VERSION "Version"

NS_ :

BS_:

BU_: Tester CCU IBCS EPB EPS ADC CCURT1 CCURT2 ZCUF ZCUL ZCUR ZCUT EMS IDM DCDC DCDCI IPS NIDU DCU2 OBC OPC LPC CPC EMCM GCU DCU IPU BMS EOP EVCC DCDC2 EDL SRS ECS RBM ICM IID IDC AMP WHUD ARHUD IMR FIMR CD INU IFC FAPA RRR RLR PAS PCS SCMF SCMR SCMRL SCMRR MFS DRM FCP RCP LBMSAD AVAS DLPFL FBLCM FLISD FLLCM FRLCM RLLCMA RLLCMB RRLCMA RRLCMB RLISD DLPML DLPMR TRM PSDL PSDR FLDCM FRDCM HVSPRL HVSPRR RFR SBM WCM ETC TBOX2 TBOX RLBMS EBU FLPDM RLPDM FRPDM RRPDM FLOAR FROAR RLOAR RROAR EOSL EOSR EOST PRBU RT2_C3 OTAWL IDUR PHUDD RAS CBM PLGM TMC LPC2 SAS RCICP SCMRM SCMT SLMRL SLMRR IDU RRISD DSASBM LBMS RT1_C0 RT1_C1

BO_ 2015 Fun_Diag_Rx: 64 Tester
 SG_ Fun_Diag_Request : 7|512@0+ (1,0) [0|0] ""  CCURT1,CCURT2,ZCUF,ZCUL,ZCUR,ZCUT,EMS,IDM,DCDC,DCDCI,IPS,NIDU,DCU2,OBC,OPC,LPC,CPC,EMCM,GCU,DCU,IPU,BMS,EOP,EVCC,DCDC2,EDL,SRS,ECS,EPS,EPB,RBM,IBCS,ICM,IID,IDC,AMP,WHUD,ARHUD,IMR,FIMR,CD,INU,ADC,IFC,FAPA,RRR,RLR,PAS,PCS,SCMF,SCMR,SCMRL,SCMRR,MFS,DRM,FCP,RCP,LBMSAD,AVAS,DLPFL,FBLCM,FLISD,FLLCM,FRLCM,RLLCMA,RLLCMB,RRLCMA,RRLCMB,RLISD,DLPML,DLPMR,TRM,PSDL,PSDR,FLDCM,FRDCM,HVSPRL,HVSPRR,RFR,SBM,WCM,ETC,TBOX2,TBOX,RLBMS,EBU,FLPDM,RLPDM,FRPDM,RRPDM,FLOAR,FROAR,RLOAR,RROAR,EOSL,EOSR,EOST,PRBU

BO_ 368 CCU_DCU_1: 64 CCU
 SG_ DCU_1_CRC : 7|16@0+ (1,0) [0|65535] ""  ADC
 SG_ DCU_1_Counter : 23|8@0+ (1,0) [0|255] ""  ADC
 SG_ DCU_RotSpdAct : 31|16@0+ (1,-32767) [-32767|32766] "rpm"  EPB,ADC
 SG_ DCU_ModeSt : 79|4@0+ (1,0) [0|15] ""  ADC
 SG_ DCU_ADC_MCUBlkst : 268|3@0+ (1,0) [0|7] ""  ADC
 SG_ DCU_ADC_SpdSvModAvl : 256|1@0+ (1,0) [0|1] ""  ADC
 SG_ DCU_ADC_MCUStandstill : 257|1@0+ (1,0) [0|1] ""  ADC
 SG_ DCU_ADC_MCUSpdSVModFit : 271|3@0+ (1,0) [0|7] ""  ADC
 SG_ DCU_ADC_MCUVehSldSt : 258|1@0+ (1,0) [0|1] ""  ADC
 SG_ DCU_ADC_MCUReqTq : 253|11@0+ (1,-1023) [-1023|1023] "Nm"  ADC
 SG_ DCU_TorqAct : 169|13@0+ (0.2,-819) [-819|819] "Nm"  ADC

BO_ 369 CCU_DCU2_1: 64 CCU
 SG_ DCU2_1_CRC : 7|16@0+ (1,0) [0|65535] ""  ADC
 SG_ DCU2_1_Counter : 23|8@0+ (1,0) [0|255] ""  ADC
 SG_ DCU2_RotSpdAct : 31|16@0+ (1,-32767) [-32767|32766] "rpm"  ADC
 SG_ DCU2_ModeSt_Hyb : 221|4@0+ (1,0) [0|15] ""  ADC
 SG_ DCU2_ADC_MCUBlkst : 268|3@0+ (1,0) [0|7] ""  ADC
 SG_ DCU2_ADC_SpdSvModAvl : 256|1@0+ (1,0) [0|1] ""  ADC
 SG_ DCU2_ADC_MCUStandstill : 257|1@0+ (1,0) [0|1] ""  ADC
 SG_ DCU2_ADC_MCUSpdSVModFit : 271|3@0+ (1,0) [0|7] ""  ADC
 SG_ DCU2_ADC_MCUVehSldSt : 258|1@0+ (1,0) [0|1] ""  ADC
 SG_ DCU2_ADC_MCUReqTq : 253|11@0+ (1,-1023) [-1023|1023] "Nm"  ADC

BO_ 513 CCU_IDUR_1: 64 CCU
 SG_ IDUR_RotSpdActL : 31|16@0+ (1,-32767) [-32767|32766] "rpm"  ADC
 SG_ IDUR_RotSpdActR : 135|16@0+ (1,-32767) [-32767|32766] "rpm"  ADC

BO_ 860 CCU_VCU_7: 64 CCU
 SG_ VCU_7_CRC : 7|16@0+ (1,0) [0|65535] ""  CCURT2,RT2_C3,ZCUF,ZCUL,ZCUR,ZCUT,EPB,IID,IDC,ADC,IFC,FAPA,RRR,RLR,DRM
 SG_ VCU_7_Counter : 23|8@0+ (1,0) [0|255] ""  CCURT2,RT2_C3,ZCUF,ZCUL,ZCUR,ZCUT,EPB,IID,IDC,ADC,IFC,FAPA,RRR,RLR,DRM
 SG_ VCU_RoadMod : 27|3@0+ (1,0) [0|7] ""  ECS,IBCS,IDC,ADC,FAPA
 SG_ VCU_GearLvl : 31|4@0+ (1,0) [0|15] ""  CCURT2,RT2_C3,ZCUF,ZCUL,ZCUR,ZCUT,EMS,EPB,IBCS,ADC,IFC,FAPA,RRR,RLR,DRM
 SG_ VCU_VehDrvMod : 38|3@0+ (1,0) [0|7] ""  CCURT2,RT2_C3,ZCUL,ZCUR,EMS,ECS,IBCS,ICM,IDC,AMP,ADC,IFC,FAPA
 SG_ VCU_VehRdySt : 39|1@0+ (1,0) [0|1] ""  CCURT2,RT2_C3,OTAWL,ZCUF,ZCUL,ZCUR,ZCUT,EMS,IDM,IPS,NIDU,DCU2,IDUR,OBC,GCU,DCU,IPU,BMS,ECS,EPB,IBCS,ICM,IID,IDC,PHUDD,ADC,IFC,FAPA,RRR,RLR,EBU
 SG_ VCU_ChgActiveSt_toADC : 52|1@0+ (1,0) [0|1] ""  ADC,IFC,FAPA
 SG_ VCU_PlgConnSt : 91|1@0+ (1,0) [0|1] ""  CCURT2,RT2_C3,ZCUR,ZCUT,NIDU,DCU2,IDUR,GCU,DCU,IPU,ECS,ICM,IID,IDC,PHUDD,ADC,IFC,FAPA,FLLCM,FRLCM
 SG_ VCU_EVRng : 143|9@0+ (1,0) [0|511] "km"  CCURT1,CCURT2,ICM,IID,IDC,PHUDD,ADC,IFC,FAPA
 SG_ VCU_GearLvlDisp : 155|4@0+ (1,0) [0|15] ""  ICM,IID,IDC,PHUDD,WHUD,ARHUD,IMR,FIMR,ADC,IFC,FAPA,PCS
 SG_ VCU_BMS_BattSocDisp : 199|8@0+ (0.3937,0) [0|100] "%"  CCURT2,RT2_C3,ZCUF,ZCUL,ZCUR,ZCUT,EMS,BMS,ICM,IID,IDC,PHUDD,ADC,IFC,FAPA,TBOX,RLBMS
 SG_ VCU_SuspModeReq : 257|2@0+ (1,0) [0|3] ""  ECS,ADC,IFC,FAPA
 SG_ VCU_SuspModeReqEnable : 316|1@0+ (1,0) [0|1] ""  ECS,ADC,IFC,FAPA
 SG_ VCU_PivotSteeringStAvailable : 24|1@0+ (1,0) [0|1] ""  IBCS,IDC,ADC,IFC
 SG_ VCU_PivotSteeringSt : 183|3@0+ (1,0) [0|7] ""  IDUR,IPU,IBCS,IDC,ADC,IFC
 SG_ VCU_GearPosition : 315|3@0+ (1,0) [0|7] ""  CCURT2,BMS,ADC,IFC,FAPA
 SG_ VCU_EcoPlusMod : 341|2@0+ (1,0) [0|3] ""  CCURT2,RT2_C3,IDC,WHUD,ARHUD,ADC
 SG_ ICC_RoadMod : 339|4@0+ (1,0) [0|8] ""  ECS,IBCS,IDC,ADC

BO_ 431 CCU_VCU_8: 64 CCU
 SG_ VCU_TargetRecpTorqSt : 133|2@0+ (1,0) [0|3] ""  IBCS,ADC,IFC,FAPA
 SG_ VCU_AccElecECFail : 151|1@0+ (1,0) [0|1] ""  IBCS,ADC,IFC,FAPA
 SG_ VCU_AccDriverOrvd : 150|1@0+ (1,0) [0|1] ""  ADC,IFC,FAPA
 SG_ VCU_AccTMCFail : 149|1@0+ (1,0) [0|1] ""  IBCS,ADC,IFC,FAPA
 SG_ VCU_TargetRecpTorqNm : 423|14@0+ (1,0) [0|16000] "Nm"  IBCS,ADC,IFC,FAPA
 SG_ VCU_TargetRecpTorqFA : 153|14@0+ (1,0) [0|16000] "Nm"  IBCS,ADC,IFC,FAPA,EBU
 SG_ VCU_TargetRecpTorqRA : 171|14@0+ (1,0) [0|16000] "Nm"  IBCS,ADC,IFC,FAPA,EBU
 SG_ VCU_TorqDriverReqFA : 189|14@0+ (1,0) [0|16000] "Nm"  ECS,IBCS,ADC,IFC,FAPA,EBU
 SG_ VCU_TorqDriverReqRA : 207|14@0+ (1,0) [0|16000] "Nm"  ECS,IBCS,ADC,IFC,FAPA,EBU
 SG_ VCU_VehActDrvTorqFA : 209|14@0+ (1,0) [0|16000] "Nm"  ECS,EPS,IBCS,ADC,IFC,FAPA,EBU
 SG_ VCU_VehActDrvTorqRA : 227|14@0+ (1,0) [0|16000] "Nm"  IDM,ECS,EPS,IBCS,ADC,IFC,FAPA,EBU
 SG_ VCU_TargetRecpTorqFAVD : 104|1@0+ (1,0) [0|1] ""  IBCS,ADC,IFC,FAPA,EBU
 SG_ VCU_TargetRecpTorqRAVD : 105|1@0+ (1,0) [0|1] ""  IBCS,ADC,IFC,FAPA,EBU
 SG_ VCU_TorqDriverReqFAVD : 128|1@0+ (1,0) [0|1] ""  ECS,IBCS,ADC,IFC,FAPA,EBU
 SG_ VCU_TorqDriverReqRAVD : 129|1@0+ (1,0) [0|1] ""  ECS,IBCS,ADC,IFC,FAPA,EBU
 SG_ VCU_VehActDrvTorqFAVD : 244|1@0+ (1,0) [0|1] ""  ECS,EPS,IBCS,ADC,IFC,FAPA,EBU
 SG_ VCU_VehActDrvTorqRAVD : 245|1@0+ (1,0) [0|1] ""  IDM,ECS,EPS,IBCS,ADC,IFC,FAPA,EBU
 SG_ VCU_BcsDecelReq : 243|4@0+ (0.066,-0.99) [-0.99|0] "m/s2"  IBCS,ADC,IFC,FAPA
 SG_ VCU_BcsDecelVD : 255|1@0+ (1,0) [0|1] ""  IBCS,ADC,IFC,FAPA
 SG_ VCU_RecpTorqRL : 261|14@0+ (1,0) [0|16000] ""  IBCS,ADC,FAPA
 SG_ VCU_RecpTorqRLVD : 262|1@0+ (1,0) [0|1] ""  IBCS,ADC,FAPA
 SG_ VCU_RecpTorqRR : 277|14@0+ (1,0) [0|16000] ""  IBCS,ADC,FAPA
 SG_ VCU_RecpTorqRRVD : 278|1@0+ (1,0) [0|1] ""  IBCS,ADC,FAPA
 SG_ VCU_ADSNetErrorFb : 159|3@0+ (1,0) [0|7] ""  ADC,IFC,FAPA
 SG_ VCU_NetModeResp : 156|2@0+ (1,0) [0|3] ""  ADC,FAPA

BO_ 516 CCU_VCU_9: 64 CCU
 SG_ VCU_9_CRC : 7|16@0+ (1,0) [0|65535] ""  CCURT2,RT2_C3,ZCUF,ZCUL,ZCUR,ZCUT,EMS,NIDU,DCU2,IDUR,EDL,ECS,EPB,IBCS,ICM,IDC,INU,ADC,IFC,FAPA,RRR,RLR,PAS,EBU
 SG_ VCU_9_Counter : 23|8@0+ (1,0) [0|255] ""  CCURT2,RT2_C3,ZCUF,ZCUL,ZCUR,ZCUT,EMS,NIDU,DCU2,IDUR,EDL,ECS,EPB,IBCS,ICM,IDC,INU,ADC,IFC,FAPA,RRR,RLR,PAS,EBU
 SG_ VCU_VehWheelTorqMaxVD : 25|1@0+ (1,0) [0|1] ""  ADC,IFC,FAPA
 SG_ VCU_RecpTorq : 71|10@0+ (2,0) [0|2000] "Nm"  IBCS,ADC,IFC,FAPA
 SG_ VCU_RecpTorqSt : 75|2@0+ (1,0) [0|3] ""  IBCS,ADC,IFC,FAPA
 SG_ VCU_MaxRecpTorqSt : 73|2@0+ (1,0) [0|3] ""  IBCS,ADC,IFC,FAPA
 SG_ VCU_MaxRecpTorq : 87|10@0+ (2,0) [0|2000] "Nm"  IBCS,ADC,IFC,FAPA
 SG_ VCU_CrntGearLvl : 92|3@0+ (1,0) [0|7] ""  CCURT2,RT2_C3,OTAWL,ZCUF,ZCUL,ZCUR,ZCUT,NIDU,DCU2,IDUR,DCU,IPU,SRS,ECS,RAS,EPS,EPB,IBCS,IDC,AMP,INU,ADC,IFC,FAPA,RRR,RLR,PAS,DLPML,DLPMR,TBOX,EBU
 SG_ VCU_CrntGearLvlVD : 88|1@0+ (1,0) [0|1] ""  ZCUF,ZCUL,ZCUR,ZCUT,SRS,ECS,EPS,IBCS,AMP,INU,ADC,IFC,FAPA,RRR,RLR,PAS
 SG_ VCU_BrkPedPstVD : 89|1@0+ (1,0) [0|1] ""  CCURT2,RT2_C3,NIDU,DCU2,IDUR,SRS,ECS,IBCS,IDC,ADC,IFC,FAPA
 SG_ VCU_BrkPedPst : 103|8@0+ (0.392,0) [0|99.96] "%"  CCURT2,RT2_C3,NIDU,DCU2,IDUR,SRS,ECS,IBCS,IDC,ADC,IFC,FAPA
 SG_ VCU_APAGasPedalIntv : 112|1@0+ (1,0) [0|1] ""  IBCS,ADC,IFC,FAPA
 SG_ VCU_APAAvailable : 113|1@0+ (1,0) [0|1] ""  IBCS,ADC,IFC,FAPA
 SG_ VCU_APAWheelTorqDriverReq : 111|14@0+ (1,-5000) [-5000|5000] "Nm"  ADC,IFC,FAPA
 SG_ VCU_APAGearIntervern : 137|1@0+ (1,0) [0|1] ""  IBCS,ADC,IFC,FAPA
 SG_ VCU_EMS_AccPedalActPst : 127|8@0+ (0.392,0) [0|99.96] "%"  CCURT2,RT2_C3,EMS,NIDU,DCU2,IDUR,SRS,ECS,IBCS,IDC,AMP,ADC,IFC,FAPA,RRR,RLR,EBU
 SG_ VCU_EMS_AccPedalActPstVD : 136|1@0+ (1,0) [0|1] ""  CCURT2,RT2_C3,EMS,NIDU,DCU2,IDUR,SRS,ECS,IBCS,IDC,AMP,ADC,IFC,FAPA,EBU
 SG_ VCU_ActVehWheelTorq : 135|14@0+ (1,-5000) [-5000|5000] "Nm"  IBCS,ADC,IFC,FAPA
 SG_ VCU_VehWheelTorqMax : 167|14@0+ (1,-5000) [-5000|5000] "Nm"  IBCS,ADC,IFC,FAPA
 SG_ VCU_EMS_BrkPedalSt : 189|1@0+ (1,0) [0|1] ""  CCURT2,RT2_C3,EMS,SRS,ECS,IDC,ADC,IFC,FAPA,RRR,RLR,TBOX
 SG_ VCU_EMS_BrkPedalStVD : 188|1@0+ (1,0) [0|1] ""  CCURT2,RT2_C3,EMS,SRS,ECS,IDC,ADC,IFC,FAPA
 SG_ VCU_ACCMaxRecpDecelVD : 187|1@0+ (1,0) [0|1] ""  ADC,IFC,FAPA
 SG_ VCU_ACCLimitOperatingSt : 186|1@0+ (1,0) [0|1] ""  ADC,IFC,FAPA
 SG_ VCU_APAResp : 185|1@0+ (1,0) [0|1] ""  IBCS,ADC,IFC,FAPA
 SG_ VCU_ADSEcoModReq : 184|1@0+ (1,0) [0|1] ""  ADC,IFC,FAPA
 SG_ VCU_AccButtInfo : 199|8@0+ (1,0) [0|255] ""  IDC,ADC,IFC,FAPA
 SG_ VCU_ACCMaxRecpDecel : 207|8@0+ (0.05,-5) [-5|7.75] "m/s2"  ADC,IFC,FAPA
 SG_ VCU_ACCmaxSpdLimit : 215|4@0+ (1,0) [0|15] ""  ADC,IFC,FAPA
 SG_ VCU_APA_Resp : 210|1@0+ (1,0) [0|1] ""  ADC,IFC,FAPA
 SG_ VCU_RecpTorqFAVD : 208|1@0+ (1,0) [0|1] ""  IBCS,ADC,IFC,FAPA,EBU
 SG_ VCU_RecpTorqRAVD : 209|1@0+ (1,0) [0|1] ""  IBCS,ADC,IFC,FAPA,EBU
 SG_ VCU_MaxRecpTorqFAVD : 152|1@0+ (1,0) [0|1] ""  IBCS,ADC,IFC,FAPA,EBU
 SG_ VCU_MaxRecpTorqRAVD : 153|1@0+ (1,0) [0|1] ""  IBCS,ADC,IFC,FAPA,EBU
 SG_ VCU_RecpTorqNm : 359|14@0+ (1,0) [0|16000] "Nm"  IBCS,ADC,IFC,FAPA
 SG_ VCU_APAWheelTorqDriverReqNm : 361|15@0+ (1,-16000) [-16000|16000] "Nm"  ADC,IFC,FAPA
 SG_ VCU_ActVehWheelTorqNm : 378|15@0+ (1,-16000) [-16000|16000] "Nm"  ECS,IBCS,AMP,ADC,IFC,FAPA
 SG_ VCU_VehWheelTorqMinNm : 395|15@0+ (1,-16000) [-16000|16000] "Nm"  ECS,IBCS,ADC,IFC,FAPA
 SG_ VCU_VehWheelTorqMaxNm : 412|15@0+ (1,-16000) [-16000|16000] "Nm"  ECS,IBCS,ADC,IFC,FAPA
 SG_ VCU_RecpTorqFA : 231|14@0+ (1,0) [0|16000] "Nm"  IBCS,ADC,IFC,FAPA,EBU
 SG_ VCU_RecpTorqRA : 233|14@0+ (1,0) [0|16000] "Nm"  IBCS,ADC,IFC,FAPA,EBU
 SG_ VCU_MaxRecpTorqFA : 251|14@0+ (1,0) [0|16000] "Nm"  IBCS,ADC,IFC,FAPA,EBU
 SG_ VCU_MaxRecpTorqRA : 269|14@0+ (1,0) [0|16000] "Nm"  IBCS,ADC,IFC,FAPA,EBU
 SG_ VCU_BcsDecelEnable : 305|1@0+ (1,0) [0|1] ""  IBCS,IDC,ADC,IFC,FAPA
 SG_ VCU_CrntGearNoTrans : 317|3@0+ (1,0) [0|7] ""  ADC,IFC,FAPA
 SG_ VCU_EzTSt : 314|2@0+ (1,0) [0|3] ""  IBCS,IDC,ADC,FAPA
 SG_ VCU_ITASSt : 444|3@0+ (1,0) [0|7] ""  IBCS,IDC,ADC,FAPA

BO_ 616 CCU_1: 64 CCU
 SG_ CCU_1_CRC : 7|16@0+ (1,0) [0|65535] ""  CCURT2,RT2_C3,OTAWL,ZCUF,ZCUL,ZCUR,ZCUT,NIDU,DCU2,BMS,CBM,RBM,ICM,IID,IDC,ADC,IFC,FAPA,DRM,PLGM,TRM,RLBMS
 SG_ CCU_1_Counter : 23|8@0+ (1,0) [0|255] ""  CCURT2,RT2_C3,OTAWL,ZCUF,ZCUL,ZCUR,ZCUT,NIDU,DCU2,BMS,CBM,RBM,ICM,IID,IDC,ADC,IFC,FAPA,DRM,PLGM,TRM,RLBMS
 SG_ UMM_UsageModeSt : 26|3@0+ (1,0) [0|7] ""  CCURT2,RT2_C3,OTAWL,TMC,ZCUF,ZCUL,ZCUR,ZCUT,EMS,DCDC,DCDCI,IPS,NIDU,DCU2,IDUR,OBC,OPC,LPC,LPC2,CPC,EMCM,GCU,DCU,IPU,BMS,EOP,DCDC2,EDL,SRS,ECS,SAS,CBM,RAS,EPS,EPB,RBM,IBCS,ICM,IID,IDC,PHUDD,RCICP,AMP,WHUD,ARHUD,IMR,FIMR,CD,INU,ADC,IFC,FAPA,RRR,RLR,PAS,PCS,SCMR,SCMRL,SCMRR,SCMRM,SCMT,MFS,SLMRL,SLMRR,DRM,IDU,FCP,RCP,LBMSAD,AVAS,DLPFL,FBLCM,FLISD,FLLCM,FRLCM,RLLCMA,RLLCMB,RRLCMA,RRLCMB,RLISD,RRISD,DLPML,DSASBM,DLPMR,PLGM,TRM,PSDL,PSDR,HVSPRL,HVSPRR,LBMS,TBOX2,TBOX,RLBMS,EBU,FLPDM,RLPDM,FRPDM,RRPDM,FLOAR,FROAR
 SG_ OTA_FuncReq_ADCWakeup : 45|3@0+ (1,0) [0|7] ""  ADC,FAPA
 SG_ UMM_FrontPassengerSeatSt : 57|2@0+ (1,0) [0|3] ""  CCURT2,RT2_C3,OTAWL,ZCUR,SRS,IBCS,ICM,IDC,ADC,IFC,FAPA,RRR,RLR,EBU
 SG_ UMM_DriverSeatSt : 59|2@0+ (1,0) [0|3] ""  CCURT1,CCURT2,RT2_C3,OTAWL,ZCUR,SRS,IBCS,ICM,IDC,ADC,IFC,FAPA,RRR,RLR,EBU
 SG_ VMM_VehModeSt : 159|4@0+ (1,0) [0|15] ""  CCURT2,RT2_C3,OTAWL,TMC,ZCUF,ZCUL,ZCUR,ZCUT,EMS,DCDC,DCDCI,IPS,NIDU,DCU2,IDUR,OBC,OPC,LPC,LPC2,CPC,EMCM,GCU,DCU,IPU,BMS,EOP,DCDC2,EDL,SRS,ECS,SAS,EPS,EPB,RBM,IBCS,ICM,IDC,RCICP,AMP,WHUD,ARHUD,IMR,FIMR,ADC,IFC,FAPA,RRR,RLR,PAS,SCMR,SCMRL,SCMRR,SCMRM,SCMT,MFS,SLMRL,SLMRR,IDU,FCP,RCP,LBMSAD,AVAS,DLPFL,FBLCM,FLISD,FLLCM,FRLCM,RLLCMA,RLLCMB,RRLCMA,RRLCMB,RLISD,RRISD,DLPML,DLPMR,PLGM,TRM,PSDL,PSDR,HVSPRL,HVSPRR,LBMS,RFR,SBM,WCM,ETC,TBOX2,TBOX,RLBMS,EBU,FLPDM,RLPDM,FRPDM,RRPDM,FLOAR,FROAR,RLOAR,RROAR
 SG_ VMM_LastVehModeSt : 155|4@0+ (1,0) [0|15] ""  TMC,ZCUF,ZCUL,ZCUR,ZCUT,EMS,DCDC,DCDCI,IPS,NIDU,DCU2,IDUR,OBC,OPC,LPC,LPC2,CPC,EMCM,GCU,DCU,IPU,BMS,DCDC2,EDL,SRS,EPS,EPB,RBM,IBCS,ICM,IDC,AMP,ADC,IFC,FAPA,PAS,SCMR,SCMRL,SCMRR,MFS,SLMRL,SLMRR,FCP,RCP,AVAS,FLLCM,FRLCM,TRM,PSDL,RFR,SBM,WCM,ETC,TBOX,EBU,FLPDM,FLOAR,FROAR,RLOAR,RROAR
 SG_ VMM_OTAModeSt : 167|2@0+ (1,0) [0|3] ""  CCURT2,RT2_C3,OTAWL,ZCUF,ZCUL,ZCUR,ZCUT,EMS,DCDC,DCDCI,IPS,NIDU,DCU2,IDUR,OBC,OPC,LPC,LPC2,CPC,EMCM,GCU,DCU,IPU,BMS,EOP,DCDC2,EDL,SRS,ECS,EPS,EPB,RBM,IBCS,ICM,IID,IDC,RCICP,AMP,WHUD,ARHUD,ADC,IFC,FAPA,RRR,RLR,PAS,SCMR,SCMRL,SCMRR,SCMRM,SCMT,MFS,SLMRL,SLMRR,IDU,FCP,RCP,LBMSAD,AVAS,DLPFL,FBLCM,FLISD,FLLCM,FRLCM,RLLCMA,RLLCMB,RRLCMA,RRLCMB,RLISD,RRISD,DLPML,DLPMR,TRM,PSDL,PSDR,HVSPRL,HVSPRR,LBMS,RFR,SBM,WCM,ETC,TBOX,RLBMS,EBU,FLPDM,RLPDM,FRPDM,RRPDM,FLOAR,FROAR,RLOAR,RROAR
 SG_ CSM_RC_PAARequest : 287|4@0+ (1,0) [0|15] ""  ADC,FAPA
 SG_ CSM_RC_AuthSt : 281|2@0+ (1,0) [0|3] ""  ADC,FAPA
 SG_ IPDS_EnablePowerSup : 327|2@0+ (1,0) [0|3] ""  CCURT2,ZCUF,ZCUL,ZCUR,ZCUT,EMS,IPS,NIDU,DCU2,IDUR,OBC,OPC,LPC,LPC2,CPC,EMCM,GCU,DCU,IPU,BMS,EDL,SRS,ECS,EPB,RBM,IBCS,ICM,IID,IDC,PHUDD,ADC,FAPA,PCS,EBU
 SG_ Time_Year : 343|8@0+ (1,2000) [2000|2255] "y"  CCURT2,RT2_C3,TMC,ZCUF,ZCUL,ZCUR,ZCUT,EMS,DCDC,DCDCI,IPS,NIDU,DCU2,IDUR,OBC,OPC,LPC,LPC2,CPC,EMCM,GCU,DCU,IPU,BMS,EOP,EVCC,DCDC2,EDL,SRS,ECS,CBM,EPS,EPB,RBM,IBCS,RCICP,AMP,WHUD,ARHUD,IMR,FIMR,INU,ADC,IFC,FAPA,RRR,RLR,PAS,PCS,SCMR,SCMRL,SCMRR,SCMT,MFS,SLMRL,SLMRR,DRM,IDU,FCP,RCP,LBMSAD,DLPFL,FBLCM,FLISD,FLLCM,FRLCM,RLLCMA,RLLCMB,RRLCMA,RRLCMB,RLISD,RRISD,DLPML,DSASBM,DLPMR,PLGM,TRM,PSDL,PSDR,HVSPRL,HVSPRR,LBMS,RLBMS,EBU,FLPDM,RLPDM,FRPDM,RRPDM,FLOAR,FROAR,RLOAR,RROAR
 SG_ Time_Month : 351|4@0+ (1,0) [1|12] "m"  CCURT2,RT2_C3,TMC,ZCUF,ZCUL,ZCUR,ZCUT,EMS,DCDC,DCDCI,IPS,NIDU,DCU2,IDUR,OBC,OPC,LPC,LPC2,CPC,EMCM,GCU,DCU,IPU,BMS,EOP,EVCC,DCDC2,EDL,SRS,ECS,CBM,EPS,EPB,RBM,IBCS,RCICP,AMP,WHUD,ARHUD,IMR,FIMR,INU,ADC,IFC,FAPA,RRR,RLR,PAS,PCS,SCMR,SCMRL,SCMRR,SCMT,MFS,SLMRL,SLMRR,DRM,IDU,FCP,RCP,LBMSAD,DLPFL,FBLCM,FLISD,FLLCM,FRLCM,RLLCMA,RLLCMB,RRLCMA,RRLCMB,RLISD,RRISD,DLPML,DSASBM,DLPMR,PLGM,TRM,PSDL,PSDR,HVSPRL,HVSPRR,LBMS,RLBMS,EBU,FLPDM,RLPDM,FRPDM,RRPDM,FLOAR,FROAR,RLOAR,RROAR
 SG_ Time_Day : 347|5@0+ (1,0) [1|31] "d"  CCURT2,RT2_C3,TMC,ZCUF,ZCUL,ZCUR,ZCUT,EMS,DCDC,DCDCI,IPS,NIDU,DCU2,IDUR,OBC,OPC,LPC,LPC2,CPC,EMCM,GCU,DCU,IPU,BMS,EOP,EVCC,DCDC2,EDL,SRS,ECS,CBM,EPS,EPB,RBM,IBCS,RCICP,AMP,WHUD,ARHUD,IMR,FIMR,INU,ADC,IFC,FAPA,RRR,RLR,PAS,PCS,SCMR,SCMRL,SCMRR,SCMT,MFS,SLMRL,SLMRR,DRM,IDU,FCP,RCP,LBMSAD,DLPFL,FBLCM,FLISD,FLLCM,FRLCM,RLLCMA,RLLCMB,RRLCMA,RRLCMB,RLISD,RRISD,DLPML,DSASBM,DLPMR,PLGM,TRM,PSDL,PSDR,HVSPRL,HVSPRR,LBMS,RLBMS,EBU,FLPDM,RLPDM,FRPDM,RRPDM,FLOAR,FROAR,RLOAR,RROAR
 SG_ Time_Hour : 358|5@0+ (1,0) [0|23] "h"  CCURT2,RT2_C3,TMC,ZCUF,ZCUL,ZCUR,ZCUT,EMS,DCDC,DCDCI,IPS,NIDU,DCU2,IDUR,OBC,OPC,LPC,LPC2,CPC,EMCM,GCU,DCU,IPU,BMS,EOP,EVCC,DCDC2,EDL,SRS,ECS,CBM,EPS,EPB,RBM,IBCS,RCICP,AMP,WHUD,ARHUD,IMR,FIMR,INU,ADC,IFC,FAPA,RRR,RLR,PAS,PCS,SCMR,SCMRL,SCMRR,SCMT,MFS,SLMRL,SLMRR,DRM,IDU,FCP,RCP,LBMSAD,DLPFL,FBLCM,FLISD,FLLCM,FRLCM,RLLCMA,RLLCMB,RRLCMA,RRLCMB,RLISD,RRISD,DLPML,DSASBM,DLPMR,PLGM,TRM,PSDL,PSDR,HVSPRL,HVSPRR,LBMS,RLBMS,EBU,FLPDM,RLPDM,FRPDM,RRPDM,FLOAR,FROAR,RLOAR,RROAR
 SG_ Time_Min : 353|6@0+ (1,0) [0|59] "min"  CCURT2,RT2_C3,TMC,ZCUF,ZCUL,ZCUR,ZCUT,EMS,DCDC,DCDCI,IPS,NIDU,DCU2,IDUR,OBC,OPC,LPC,LPC2,CPC,EMCM,GCU,DCU,IPU,BMS,EOP,EVCC,DCDC2,EDL,SRS,ECS,CBM,EPS,EPB,RBM,IBCS,RCICP,AMP,WHUD,ARHUD,IMR,FIMR,INU,ADC,IFC,FAPA,RRR,RLR,PAS,PCS,SCMR,SCMRL,SCMRR,SCMT,MFS,SLMRL,SLMRR,DRM,IDU,FCP,RCP,LBMSAD,DLPFL,FBLCM,FLISD,FLLCM,FRLCM,RLLCMA,RLLCMB,RRLCMA,RRLCMB,RLISD,RRISD,DLPML,DSASBM,DLPMR,PLGM,TRM,PSDL,PSDR,HVSPRL,HVSPRR,LBMS,RLBMS,EBU,FLPDM,RLPDM,FRPDM,RRPDM,FLOAR,FROAR,RLOAR,RROAR
 SG_ Time_Sec : 363|6@0+ (1,0) [0|59] "s"  CCURT2,RT2_C3,TMC,ZCUF,ZCUL,ZCUR,ZCUT,EMS,DCDC,DCDCI,IPS,NIDU,DCU2,IDUR,OBC,OPC,LPC,LPC2,CPC,EMCM,GCU,DCU,IPU,BMS,EOP,EVCC,DCDC2,EDL,SRS,ECS,CBM,EPS,EPB,RBM,IBCS,RCICP,AMP,WHUD,ARHUD,IMR,FIMR,INU,ADC,IFC,FAPA,RRR,RLR,PAS,PCS,SCMR,SCMRL,SCMRR,SCMT,MFS,SLMRL,SLMRR,DRM,IDU,FCP,RCP,LBMSAD,DLPFL,FBLCM,FLISD,FLLCM,FRLCM,RLLCMA,RLLCMB,RRLCMA,RRLCMB,RLISD,RRISD,DLPML,DSASBM,DLPMR,PLGM,TRM,PSDL,PSDR,HVSPRL,HVSPRR,LBMS,RLBMS,EBU,FLPDM,RLPDM,FRPDM,RRPDM,FLOAR,FROAR,RLOAR,RROAR
 SG_ CCU_DstFlag : 272|1@0+ (1,0) [0|1] ""  ZCUF,ZCUL,ZCUR,ZCUT,ADC,FAPA
 SG_ ASB_DriverActiveBeltFaultSt : 420|1@0+ (1,0) [0|1] ""  IDC,ADC,IFC,FAPA

BO_ 432 ICC_1: 64 CCU
 SG_ ICC_1_CRC : 7|16@0+ (1,0) [0|65535] ""  ECS,RAS,EPS,IBCS,ADC
 SG_ ICC_1_Counter : 23|8@0+ (1,0) [0|255] ""  ECS,RAS,EPS,IBCS,ADC
 SG_ ICC_FcnInfo : 87|12@0+ (1,0) [0|4095] ""  ECS,EPS,IBCS,ADC
 SG_ ICC_FaultSt : 91|12@0+ (1,0) [0|4095] ""  ECS,EPS,ADC
 SG_ ICC_ActorSt : 119|8@0+ (1,0) [0|255] ""  ECS,EPS,ADC
 SG_ ICC_RAS_AgCtrlAvl : 353|2@0+ (1,0) [0|3] "/"  ADC
 SG_ ICC_RAS_CalibratedSt : 360|1@0+ (1,0) [0|1] "/"  ADC
 SG_ ICC_RAS_ErrFeedback : 364|4@0+ (1,0) [0|15] "/"  ADC
 SG_ ICC_RAS_AngleVD : 365|1@0+ (1,0) [0|1] "/"  ADC
 SG_ ICC_RAS_PstOverlaySt : 367|2@0+ (1,0) [0|3] "/"  ADC
 SG_ ICC_RAS_SteerMod : 373|3@0+ (1,0) [0|7] "/"  ADC
 SG_ ICC_RAS_SteeringAngle : 370|11@0+ (0.01,-10.23) [-10.23|10.24] "deg"  ADC
 SG_ ICC_RAS_HealthyStForADC : 375|2@0+ (1,0) [0|3] "/"  ADC
 SG_ ICC_RAS_SteeringAngleSpdVD : 389|1@0+ (1,0) [0|1] "/"  ADC
 SG_ ICC_RAS_ThermalSt : 391|2@0+ (1,0) [0|3] "/"  ADC
 SG_ ICC_RAS_SteeringAngleRate : 388|13@0+ (0.01,-22.52) [-22.52|22.53] "°/s"  ADC
 SG_ ICC_RAS_WarnLamp : 411|2@0+ (1,0) [0|3] "/"  ADC
 SG_ ICC_RAS_MotorTorActMot : 407|12@0+ (0.01,-15) [-15|15] "Nm"  ADC
 SG_ ICC_RAS_ADASTargetAngle : 409|11@0+ (0.01,-10.23) [-10.23|10.24] "deg"  ADC

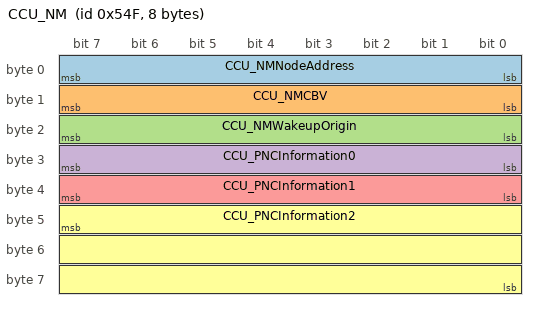
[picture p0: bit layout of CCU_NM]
BO_ 1359 CCU_NM: 8 CCU
 SG_ CCU_NMNodeAddress : 7|8@0+ (1,0) [0|255] ""  CCURT1,TMC,ZCUF,ZCUL,ZCUR,ZCUT,EMS,IPS,NIDU,BMS,EVCC,ECS,CBM,RBM,IBCS,ICM,IID,IDC,PHUDD,AMP,CD,ADC,FAPA,SCMR,SCMRL,SCMRR,SCMRM,SCMT,MFS,SLMRL,SLMRR,IDU,LBMSAD,PLGM,PSDL,PSDR,FLDCM,FRDCM,LBMS,TBOX,RLBMS,EBU,FLPDM,RLPDM,FRPDM,RRPDM
 SG_ CCU_NMCBV : 15|8@0+ (1,0) [0|0] ""  CCURT1,TMC,ZCUF,ZCUL,ZCUR,ZCUT,EMS,IPS,NIDU,BMS,EVCC,ECS,CBM,RBM,IBCS,ICM,IID,IDC,PHUDD,AMP,CD,ADC,FAPA,SCMR,SCMRL,SCMRR,SCMRM,SCMT,MFS,SLMRL,SLMRR,IDU,LBMSAD,PLGM,PSDL,PSDR,FLDCM,FRDCM,LBMS,TBOX,RLBMS,EBU,FLPDM,RLPDM,FRPDM,RRPDM
 SG_ CCU_NMWakeupOrigin : 23|8@0+ (1,0) [0|255] ""  CCURT1,TMC,ZCUF,ZCUL,ZCUR,ZCUT,EMS,IPS,NIDU,BMS,EVCC,ECS,CBM,RBM,IBCS,ICM,IID,IDC,PHUDD,AMP,CD,ADC,FAPA,SCMR,SCMRL,SCMRR,SCMRM,SCMT,MFS,SLMRL,SLMRR,IDU,LBMSAD,PLGM,PSDL,PSDR,FLDCM,FRDCM,LBMS,TBOX,RLBMS,EBU
 SG_ CCU_PNCInformation0 : 31|8@0+ (1,0) [0|255] ""  CCURT1,TMC,ZCUF,ZCUL,ZCUR,ZCUT,EMS,IPS,NIDU,BMS,EVCC,ECS,CBM,RBM,IBCS,ICM,IID,IDC,PHUDD,AMP,CD,ADC,FAPA,SCMR,SCMRL,SCMRR,SCMRM,SCMT,MFS,SLMRL,SLMRR,IDU,LBMSAD,PLGM,PSDL,PSDR,FLDCM,FRDCM,LBMS,TBOX,RLBMS,EBU,FLPDM,RLPDM,FRPDM,RRPDM
 SG_ CCU_PNCInformation1 : 39|8@0+ (1,0) [0|255] ""  CCURT1,TMC,ZCUF,ZCUL,ZCUR,ZCUT,EMS,IPS,NIDU,BMS,EVCC,ECS,CBM,RBM,IBCS,ICM,IID,IDC,PHUDD,AMP,CD,ADC,FAPA,SCMR,SCMRL,SCMRR,SCMRM,SCMT,MFS,SLMRL,SLMRR,IDU,LBMSAD,PLGM,PSDL,PSDR,FLDCM,FRDCM,LBMS,TBOX,RLBMS,EBU,FLPDM,RLPDM,FRPDM,RRPDM
 SG_ CCU_PNCInformation2 : 47|24@0+ (1,0) [0|0] ""  CCURT1,TMC,ZCUF,ZCUL,ZCUR,ZCUT,EMS,IPS,NIDU,BMS,EVCC,ECS,CBM,RBM,IBCS,ICM,IID,IDC,PHUDD,AMP,CD,ADC,FAPA,SCMR,SCMRL,SCMRR,SCMRM,SCMT,MFS,SLMRL,SLMRR,IDU,LBMSAD,PLGM,PSDL,PSDR,FLDCM,FRDCM,LBMS,TBOX,RLBMS,EBU,FLPDM,RLPDM,FRPDM,RRPDM

BO_ 359 BCS_1_B: 64 IBCS
 SG_ BCS_1_B_CRC : 7|16@0+ (1,0) [0|65535] ""  CCU,CCURT1,RT1_C0,RT1_C1,EPS,EPB,ADC
 SG_ BCS_1_B_Counter : 23|8@0+ (1,0) [0|255] ""  CCU,CCURT1,RT1_C0,RT1_C1,EPS,EPB,ADC
 SG_ BCS_FLWheelSpd_B : 31|13@0+ (0.05625,0) [0|240] "km/h"  CCU,CCURT1,RT1_C0,RT1_C1,EPS,EPB,ADC
 SG_ BCS_FLWheelSpdVD_B : 34|1@0+ (1,0) [0|1] ""  CCU,CCURT1,RT1_C0,RT1_C1,EPS,EPB,ADC
 SG_ BCS_FLWheelRotatedDirection_B : 33|1@0+ (1,0) [0|1] ""  CCU,CCURT1,RT1_C0,RT1_C1,EPB,ADC
 SG_ BCS_FLWheelRotatedDirectionVD_B : 32|1@0+ (1,0) [0|1] ""  CCU,CCURT1,RT1_C0,RT1_C1,EPB,ADC
 SG_ BCS_FRWheelSpd_B : 47|13@0+ (0.05625,0) [0|240] "km/h"  CCU,CCURT1,RT1_C0,RT1_C1,EPS,EPB,ADC
 SG_ BCS_FRWheelSpdVD_B : 50|1@0+ (1,0) [0|1] ""  CCU,CCURT1,RT1_C0,RT1_C1,EPS,EPB,ADC
 SG_ BCS_FRWheelRotatedDirection_B : 49|1@0+ (1,0) [0|1] ""  CCU,CCURT1,RT1_C0,RT1_C1,EPB,ADC
 SG_ BCS_FRWheelRotatedDirectionVD_B : 48|1@0+ (1,0) [0|1] ""  CCU,CCURT1,RT1_C0,RT1_C1,EPB,ADC
 SG_ BCS_RLWheelSpd_B : 63|13@0+ (0.05625,0) [0|240] "km/h"  CCU,CCURT1,RT1_C0,RT1_C1,EPS,EPB,ADC
 SG_ BCS_RLWheelSpdVD_B : 66|1@0+ (1,0) [0|1] ""  CCU,CCURT1,RT1_C0,RT1_C1,EPS,EPB,ADC
 SG_ BCS_RLWheelRotatedDirection_B : 65|1@0+ (1,0) [0|1] ""  CCU,CCURT1,RT1_C0,RT1_C1,EPB,ADC
 SG_ BCS_RLWheelRotatedDirectionVD_B : 64|1@0+ (1,0) [0|1] ""  CCU,CCURT1,RT1_C0,RT1_C1,EPB,ADC
 SG_ BCS_RRWheelSpd_B : 79|13@0+ (0.05625,0) [0|240] "km/h"  CCU,CCURT1,RT1_C0,RT1_C1,EPS,EPB,ADC
 SG_ BCS_RRWheelSpdVD_B : 82|1@0+ (1,0) [0|1] ""  CCU,CCURT1,RT1_C0,RT1_C1,EPS,EPB,ADC
 SG_ BCS_RRWheelRotatedDirection_B : 81|1@0+ (1,0) [0|1] ""  CCU,CCURT1,RT1_C0,RT1_C1,EPB,ADC
 SG_ BCS_RRWheelRotatedDirectionVD_B : 80|1@0+ (1,0) [0|1] ""  CCU,CCURT1,RT1_C0,RT1_C1,EPB,ADC
 SG_ BCS_HHCCtrlSt_B : 95|1@0+ (1,0) [0|1] ""  ADC
 SG_ BCS_HDCCtrlSt_B : 93|2@0+ (1,0) [0|3] ""  ADC
 SG_ BCS_HDCErrSt_B : 91|1@0+ (1,0) [0|1] ""  ADC
 SG_ BCS_FLWheelSpdEdgesSum_B : 103|12@0+ (1,0) [0|4095] ""  EPB,ADC
 SG_ BCS_FRWheelSpdEdgesSum_B : 107|12@0+ (1,0) [0|4095] ""  EPB,ADC
 SG_ BCS_RLWheelSpdEdgesSum_B : 127|12@0+ (1,0) [0|4095] ""  EPB,ADC
 SG_ BCS_RRWheelSpdEdgesSum_B : 131|12@0+ (1,0) [0|4095] ""  EPB,ADC
 SG_ BCS_FLWheelSpdEdgesSumVD_B : 151|1@0+ (1,0) [0|1] ""  EPB,ADC
 SG_ BCS_FRWheelSpdEdgesSumVD_B : 150|1@0+ (1,0) [0|1] ""  EPB,ADC
 SG_ BCS_RLWheelSpdEdgesSumVD_B : 149|1@0+ (1,0) [0|1] ""  EPB,ADC
 SG_ BCS_RRWheelSpdEdgesSumVD_B : 148|1@0+ (1,0) [0|1] ""  EPB,ADC
 SG_ BCS_FLWheelRotatedDirectionAPA_B : 147|2@0+ (1,0) [0|3] ""  EPB,ADC
 SG_ BCS_FRWheelRotatedDirectionAPA_B : 145|2@0+ (1,0) [0|3] ""  EPB,ADC
 SG_ BCS_RLWheelRotatedDirectionAPA_B : 159|2@0+ (1,0) [0|3] ""  EPB,ADC
 SG_ BCS_RRWheelRotatedDirectionAPA_B : 157|2@0+ (1,0) [0|3] ""  EPB,ADC
 SG_ BCS_ParkingReqToEPB_B : 155|2@0+ (1,0) [0|3] ""  EPB,ADC
 SG_ BCS_VDCOff_B : 153|1@0+ (1,0) [0|1] ""  ADC
 SG_ BCS_AVHSt_B : 152|1@0+ (1,0) [0|1] ""  EPB,ADC
 SG_ BCS_AVHStandby_B : 167|1@0+ (1,0) [0|1] ""  EPB,ADC
 SG_ BCS_AVHAvailable_B : 166|1@0+ (1,0) [0|1] ""  EPB,ADC
 SG_ BCS_TCSOff_B : 165|1@0+ (1,0) [0|1] ""  ADC
 SG_ BCS_BrakeOverHeat_B : 160|1@0+ (1,0) [0|1] ""  ADC
 SG_ BCS_ABAactive_B : 175|1@0+ (1,0) [0|1] ""  ADC
 SG_ BCS_ABAavailable_B : 174|1@0+ (1,0) [0|1] ""  ADC
 SG_ BCS_ABPActive_B : 173|1@0+ (1,0) [0|1] ""  ADC
 SG_ BCS_ABPAvailable_B : 172|1@0+ (1,0) [0|1] ""  ADC
 SG_ BCS_AEBActive_B : 171|1@0+ (1,0) [0|1] ""  ADC
 SG_ BCS_AEBAvailable_B : 170|1@0+ (1,0) [0|1] ""  ADC
 SG_ BCS_AWBActive_B : 169|1@0+ (1,0) [0|1] ""  ADC
 SG_ BCS_AWBAvailable_B : 168|1@0+ (1,0) [0|1] ""  ADC
 SG_ BCS_VehicleStandStillSt_B : 180|2@0+ (1,0) [0|3] ""  EPB,ADC
 SG_ BCS_AEBBAActive_B : 178|1@0+ (1,0) [0|1] ""  ADC
 SG_ IPB_InputRodStroke_B : 363|10@0+ (0.05,-5) [-5|46.15] "mm"  CCU,CCURT1,RT1_C0,RT1_C1,ADC
 SG_ IPB_InputRodStrokeSt_B : 379|1@0+ (1,0) [0|1] ""  CCU,CCURT1,ADC
 SG_ BCS_RAEBActive_B : 378|1@0+ (1,0) [0|1] ""  ADC
 SG_ BCS_RAEBAvailable_B : 377|1@0+ (1,0) [0|1] ""  ADC
 SG_ IPB_PlungerPressureSt_B : 376|1@0+ (1,0) [0|1] ""  CCU,CCURT1,RT1_C0,RT1_C1,EPB,ADC
 SG_ IPB_PlungerPressure_B : 391|12@0+ (0.3,-5) [-5|301.9] "bar"  CCU,CCURT1,RT1_C0,RT1_C1,EPB,ADC
 SG_ BCS_BrkTqCtrlAvlDrivingRdn_B : 191|3@0+ (1,0) [0|7] ""  CCU,ADC
 SG_ BCS_BrkTqCtrlActvRdn_B : 188|2@0+ (1,0) [0|3] ""  CCU,ADC
 SG_ BCS_L3CommunicationVld_B : 88|1@0+ (1,0) [0|1] ""  CCU,ADC
 SG_ BCS_LFIActiveSt_B : 163|1@0+ (1,0) [0|1] ""  CCU,ADC

CM_ SG_ 2015 Fun_Diag_Request "Diagnostic function request";
CM_ SG_ 368 DCU_1_CRC "E2E Profile 5 CRC";
CM_ SG_ 368 DCU_1_Counter "E2E Profile 5 Counter";
CM_ SG_ 368 DCU_RotSpdAct "actual rotation speed of drvie motor";
CM_ SG_ 368 DCU_ModeSt "mode status of drive motor";
CM_ SG_ 368 DCU_ADC_MCUBlkst "DCU block state";
CM_ SG_ 368 DCU_ADC_SpdSvModAvl "DCU speed mode available state";
CM_ SG_ 368 DCU_ADC_MCUStandstill "DCU standstill state";
CM_ SG_ 368 DCU_ADC_MCUSpdSVModFit "DCU speed mode fault";
CM_ SG_ 368 DCU_ADC_MCUVehSldSt "DCU detect vehicle slide state";
CM_ SG_ 368 DCU_ADC_MCUReqTq "DCU innner request torque";
CM_ SG_ 368 DCU_TorqAct "actual torque of drive motor";
CM_ SG_ 369 DCU2_1_CRC "E2E Profile 5 CRC";
CM_ SG_ 369 DCU2_1_Counter "E2E Profile 5 Counter";
CM_ SG_ 369 DCU2_RotSpdAct "actual rotation speed of drvie motor";
CM_ SG_ 369 DCU2_ModeSt_Hyb "mode status of drive motor";
CM_ SG_ 369 DCU2_ADC_MCUBlkst "DCU2 block state";
CM_ SG_ 369 DCU2_ADC_SpdSvModAvl "DCU2 speed mode available state";
CM_ SG_ 369 DCU2_ADC_MCUStandstill "DCU2 standstill state";
CM_ SG_ 369 DCU2_ADC_MCUSpdSVModFit "DCU2 speed mode fault";
CM_ SG_ 369 DCU2_ADC_MCUVehSldSt "DCU2 detect vehicle slide state";
CM_ SG_ 369 DCU2_ADC_MCUReqTq "DCU2 innner request torque";
CM_ SG_ 513 IDUR_RotSpdActL "actual rotation speed of drvie motor";
CM_ SG_ 513 IDUR_RotSpdActR "actual rotation speed of drvie motor";
CM_ SG_ 860 VCU_7_CRC "E2E Profile 5 CRC";
CM_ SG_ 860 VCU_7_Counter "E2E Profile 5 Counter";
CM_ SG_ 860 VCU_RoadMod "Road mode for display";
CM_ SG_ 860 VCU_GearLvl "Gear lever for PEPS";
CM_ SG_ 860 VCU_VehDrvMod "Drive mode for display";
CM_ SG_ 860 VCU_VehRdySt "HEV system ready status";
CM_ SG_ 860 VCU_ChgActiveSt_toADC "Charge active status";
CM_ SG_ 860 VCU_PlgConnSt "Charge connector  connected Status";
CM_ SG_ 860 VCU_EVRng "EV range for display";
CM_ SG_ 860 VCU_GearLvlDisp "Gear lever for display";
CM_ SG_ 860 VCU_BMS_BattSocDisp "Average SOC of battery pack for display";
CM_ SG_ 860 VCU_SuspModeReq "VCU to SDC  AVDC mode request ";
CM_ SG_ 860 VCU_SuspModeReqEnable "VCU to SDC AVDC  mode request enable status ";
CM_ SG_ 860 VCU_PivotSteeringStAvailable "Whether VCU is available for VCU pivot steering status";
CM_ SG_ 860 VCU_PivotSteeringSt "ITAS working status";
CM_ SG_ 860 VCU_GearPosition "Gear lever for PEPS TCC";
CM_ SG_ 860 VCU_EcoPlusMod "EcoPlus mode is activated";
CM_ SG_ 860 ICC_RoadMod "Cross-Country Road Mode for Display";
CM_ SG_ 431 VCU_TargetRecpTorqSt "Status of  Target cuperation torque of generator";
CM_ SG_ 431 VCU_AccElecECFail "Indicate the error state of electronic engine control";
CM_ SG_ 431 VCU_AccDriverOrvd "Indicating the torque demanded by the driver is higher than the torque demanded by ACC";
CM_ SG_ 431 VCU_AccTMCFail "Indicating VCU in limp-home (error) mode";
CM_ SG_ 431 VCU_TargetRecpTorqNm "Current target recuperation torque of generator";
CM_ SG_ 431 VCU_TargetRecpTorqFA "Target cuperation torque of generator for front axel";
CM_ SG_ 431 VCU_TargetRecpTorqRA "Target cuperation torque of generator for rear axel";
CM_ SG_ 431 VCU_TorqDriverReqFA "the driver torque request for front axel";
CM_ SG_ 431 VCU_TorqDriverReqRA "the driver torque request for rear axel or left rear wheel hub motor";
CM_ SG_ 431 VCU_VehActDrvTorqFA "Vehicle actual drive torque for front axel";
CM_ SG_ 431 VCU_VehActDrvTorqRA "Vehicle actual drive torque for  rear axel or  left rear wheel hub motor";
CM_ SG_ 431 VCU_TargetRecpTorqFAVD "Status of? Target cuperation torque of generator for front axel";
CM_ SG_ 431 VCU_TargetRecpTorqRAVD "Status of? Target cuperation torque of generator for rear axel";
CM_ SG_ 431 VCU_TorqDriverReqFAVD "Status of the driver torque request for front axel";
CM_ SG_ 431 VCU_TorqDriverReqRAVD "Status of the driver torque request for rear axel or  left rear wheel hub motor";
CM_ SG_ 431 VCU_VehActDrvTorqFAVD "Vehicle actual drive torque valid data for front axel";
CM_ SG_ 431 VCU_VehActDrvTorqRAVD "Vehicle actual drive torque valid data for rear axel or  left rear wheel hub motor";
CM_ SG_ 431 VCU_BcsDecelReq "target deceleration to BCS by AVDC";
CM_ SG_ 431 VCU_BcsDecelVD "Quality/Fault of AVDC deceleration to BCS";
CM_ SG_ 431 VCU_RecpTorqRL "Current recuperation torque of left rear wheel hub motor";
CM_ SG_ 431 VCU_RecpTorqRLVD "Status ofCurrent recuperation torque of left rear wheel hub motor";
CM_ SG_ 431 VCU_RecpTorqRR "Current recuperation torque of Right rear wheel hub motor";
CM_ SG_ 431 VCU_RecpTorqRRVD "Status ofCurrent recuperation torque of Right rear wheel hub motor";
CM_ SG_ 431 VCU_ADSNetErrorFb "ADS Net Error Feedback";
CM_ SG_ 431 VCU_NetModeResp "VCU Use Net Feedback";
CM_ SG_ 516 VCU_9_CRC "E2E Profile 5 CRC";
CM_ SG_ 516 VCU_9_Counter "E2E Profile 5 Counter";
CM_ SG_ 516 VCU_VehWheelTorqMaxVD "Actual effective maximum adjustable torque on wheel level validity";
CM_ SG_ 516 VCU_RecpTorq "Current recuperation torque of generator";
CM_ SG_ 516 VCU_RecpTorqSt "Status of recuperation torque of generator";
CM_ SG_ 516 VCU_MaxRecpTorqSt "Status of target recuperation torque request by BCS to generator";
CM_ SG_ 516 VCU_MaxRecpTorq "Current maximum available recuperation torque of generator";
CM_ SG_ 516 VCU_CrntGearLvl "VCU current carry out gear level";
CM_ SG_ 516 VCU_CrntGearLvlVD "Valid bit for ActualGearPosition.";
CM_ SG_ 516 VCU_BrkPedPstVD "Current brake pedal position valid data";
CM_ SG_ 516 VCU_BrkPedPst "Current brake pedal position";
CM_ SG_ 516 VCU_APAGasPedalIntv "VCU judge if  the driver intervened base the accelerator pedal position";
CM_ SG_ 516 VCU_APAAvailable "Whether VCU is available for APA function";
CM_ SG_ 516 VCU_APAWheelTorqDriverReq "The driver torque on wheel request to APA";
CM_ SG_ 516 VCU_APAGearIntervern "During parking, If there is a request from GSM to change the gearlevel, this signal will be set to 1:with intervention (GSM gearlevel invalid will also be regard as a gearlevel request)";
CM_ SG_ 516 VCU_EMS_AccPedalActPst "Current accelerate pedal actual position";
CM_ SG_ 516 VCU_EMS_AccPedalActPstVD "Current accelerate pedal actual position validity";
CM_ SG_ 516 VCU_ActVehWheelTorq "Actual effective engine torque on wheel level";
CM_ SG_ 516 VCU_VehWheelTorqMax "Actual effective maximum adjustable torque on wheel level";
CM_ SG_ 516 VCU_EMS_BrkPedalSt " Brake pedal status";
CM_ SG_ 516 VCU_EMS_BrkPedalStVD "VCU_EMS_BrakePedSt valid data";
CM_ SG_ 516 VCU_ACCMaxRecpDecelVD "VCU_ACCMaxRecpDecel validvalidity";
CM_ SG_ 516 VCU_ACCLimitOperatingSt "Operation status of ACC Limit mode, When VCU Enter the power-saving mode";
CM_ SG_ 516 VCU_APAResp "Indicate whether VCU can response PAA gear and torque request";
CM_ SG_ 516 VCU_ADSEcoModReq "Request ADS to enter ECO mode";
CM_ SG_ 516 VCU_AccButtInfo "ACC Button Information";
CM_ SG_ 516 VCU_ACCMaxRecpDecel "Current maximum recuperationdeceleration of generator";
CM_ SG_ 516 VCU_ACCmaxSpdLimit "When VCU Enter the power-saving mode，the maximum ACC target speed limited by VCU";
CM_ SG_ 516 VCU_APA_Resp "VCU response to APA if VCU is response the gear shif and torque request";
CM_ SG_ 516 VCU_RecpTorqFAVD "Status of front axel maximum recuperation torque of generator";
CM_ SG_ 516 VCU_RecpTorqRAVD "Status of rear axel maximum recuperation torque of generator";
CM_ SG_ 516 VCU_MaxRecpTorqFAVD "Status of front axel maximum recuperation torque of generator";
CM_ SG_ 516 VCU_MaxRecpTorqRAVD "Status of front axel maximum recuperation torque of generator";
CM_ SG_ 516 VCU_RecpTorqNm "Current recuperation torque of generator";
CM_ SG_ 516 VCU_APAWheelTorqDriverReqNm "The driver torque on wheel request to APA";
CM_ SG_ 516 VCU_ActVehWheelTorqNm "Actual effective engine torque on wheel level";
CM_ SG_ 516 VCU_VehWheelTorqMinNm "Actual effective minimum adjustable torque on wheel level";
CM_ SG_ 516 VCU_VehWheelTorqMaxNm "Actual effective maximum adjustable torque on wheel level";
CM_ SG_ 516 VCU_RecpTorqFA "Current recuperation torque of generator FA";
CM_ SG_ 516 VCU_RecpTorqRA "Current recuperation torque of generator RA";
CM_ SG_ 516 VCU_MaxRecpTorqFA "Current maximum available recuperation torque of generator FA";
CM_ SG_ 516 VCU_MaxRecpTorqRA "Current maximum available recuperation torque of generator RA";
CM_ SG_ 516 VCU_BcsDecelEnable "AVDC deceleration to BCS enable";
CM_ SG_ 516 VCU_CrntGearNoTrans "VCU Gear Lever send to ADS without trans";
CM_ SG_ 516 VCU_EzTSt "This signal indicates VCU-Easy turn state";
CM_ SG_ 516 VCU_ITASSt "This signal indicates VCU state that can enter iTAS or not";
CM_ SG_ 616 CCU_1_CRC "E2E Profile 5 CRC";
CM_ SG_ 616 CCU_1_Counter "E2E Profile 5 Counter";
CM_ SG_ 616 UMM_UsageModeSt "Usage mode state";
CM_ SG_ 616 OTA_FuncReq_ADCWakeup "OTA Requset ADC to Wakeup";
CM_ SG_ 616 UMM_FrontPassengerSeatSt "Front Right Seat Sensor Status";
CM_ SG_ 616 UMM_DriverSeatSt "Front Left Seat Sensor Status";
CM_ SG_ 616 VMM_VehModeSt "Vehicle mode state";
CM_ SG_ 616 VMM_LastVehModeSt "Last time vehicle mode";
CM_ SG_ 616 VMM_OTAModeSt "OTA Mode state";
CM_ SG_ 616 CSM_RC_PAARequest "CSM_RC_Park request";
CM_ SG_ 616 CSM_RC_AuthSt "Auth Result with SBM/TBOX/KAE";
CM_ SG_ 616 IPDS_EnablePowerSup "Enable power supply";
CM_ SG_ 616 Time_Year "Year number";
CM_ SG_ 616 Time_Month "Month number";
CM_ SG_ 616 Time_Day "Day number";
CM_ SG_ 616 Time_Hour "Hour number";
CM_ SG_ 616 Time_Min "Minute number";
CM_ SG_ 616 Time_Sec "Second number";
CM_ SG_ 616 CCU_DstFlag "Daylight Saving Time Flag";
CM_ SG_ 616 ASB_DriverActiveBeltFaultSt "Driver Side Active Seat Belt Fault State";
CM_ SG_ 432 ICC_1_CRC "E2E Profile 5 CRC";
CM_ SG_ 432 ICC_1_Counter "E2E Profile 5 Counter";
CM_ SG_ 432 ICC_FcnInfo "ICC system Function Action Information";
CM_ SG_ 432 ICC_FaultSt "ICC System Fault Status";
CM_ SG_ 432 ICC_ActorSt "ICC System Actor Status";
CM_ SG_ 432 ICC_RAS_AgCtrlAvl "RAS  Angle  control status";
CM_ SG_ 432 ICC_RAS_CalibratedSt "Calibration status of RAS sensors";
CM_ SG_ 432 ICC_RAS_ErrFeedback "RAS fault feedback";
CM_ SG_ 432 ICC_RAS_AngleVD "RAS Angle VD";
CM_ SG_ 432 ICC_RAS_PstOverlaySt "RAS  Angle  control status";
CM_ SG_ 432 ICC_RAS_SteerMod "The current working mode of RAS";
CM_ SG_ 432 ICC_RAS_SteeringAngle "The actual Angle of the rear wheel";
CM_ SG_ 432 ICC_RAS_HealthyStForADC "The health status of RAS's own software and hardware";
CM_ SG_ 432 ICC_RAS_SteeringAngleSpdVD "rear wheel angular velocity VD";
CM_ SG_ 432 ICC_RAS_ThermalSt "The overheating state of the RAS motor";
CM_ SG_ 432 ICC_RAS_SteeringAngleRate "Rear wheel rotation Angle speed";
CM_ SG_ 432 ICC_RAS_WarnLamp "The status of RAS fault light indicates";
CM_ SG_ 432 ICC_RAS_MotorTorActMot "RAS Actural motor torque";
CM_ SG_ 432 ICC_RAS_ADASTargetAngle "The target request Angle of ICC to RAS";
CM_ SG_ 1359 CCU_NMNodeAddress "CCU node address";
CM_ SG_ 1359 CCU_NMCBV "CCU Network management control bit vector";
CM_ SG_ 1359 CCU_NMWakeupOrigin "Origin of the wake up";
CM_ SG_ 1359 CCU_PNCInformation0 "PNC Information";
CM_ SG_ 1359 CCU_PNCInformation1 "PNC Information";
CM_ SG_ 1359 CCU_PNCInformation2 "PNC Information";
CM_ SG_ 359 BCS_1_B_CRC "E2E Profile 5 CRC";
CM_ SG_ 359 BCS_1_B_Counter "E2E Profile 5 Counter";
CM_ SG_ 359 BCS_FLWheelSpd_B "Current wheel speed information of front left wheel";
CM_ SG_ 359 BCS_FLWheelSpdVD_B "Quality/fault information to current wheel speed of front left wheel";
CM_ SG_ 359 BCS_FLWheelRotatedDirection_B "FL wheel rotate direction";
CM_ SG_ 359 BCS_FLWheelRotatedDirectionVD_B "FL wheel rotate direction validity";
CM_ SG_ 359 BCS_FRWheelSpd_B "Current wheel speed information of front right wheel";
CM_ SG_ 359 BCS_FRWheelSpdVD_B "Quality/fault information to current wheel speed of front right  wheel";
CM_ SG_ 359 BCS_FRWheelRotatedDirection_B "FR wheel rotate direction";
CM_ SG_ 359 BCS_FRWheelRotatedDirectionVD_B "FR wheel rotate direction validity";
CM_ SG_ 359 BCS_RLWheelSpd_B "Current wheel speed information of rear left wheel";
CM_ SG_ 359 BCS_RLWheelSpdVD_B "Quality/fault information to current wheel speed of rear left wheel";
CM_ SG_ 359 BCS_RLWheelRotatedDirection_B "RL wheel rotate direction";
CM_ SG_ 359 BCS_RLWheelRotatedDirectionVD_B "RL wheel rotate direction validity";
CM_ SG_ 359 BCS_RRWheelSpd_B "Current wheel speed information of rear right wheel";
CM_ SG_ 359 BCS_RRWheelSpdVD_B "Quality/fault information to current wheel speed of rear right wheel";
CM_ SG_ 359 BCS_RRWheelRotatedDirection_B "RR wheel rotate direction";
CM_ SG_ 359 BCS_RRWheelRotatedDirectionVD_B "RR wheel rotate direction validity";
CM_ SG_ 359 BCS_HHCCtrlSt_B "HHC(Hill Hold Control) control status";
CM_ SG_ 359 BCS_HDCCtrlSt_B "HDC(Hill Descent Control) control status";
CM_ SG_ 359 BCS_HDCErrSt_B "HDC error status";
CM_ SG_ 359 BCS_FLWheelSpdEdgesSum_B "Accumulated sum of rising and falling edges of front left wheel speed sensor output·since IGN ON( the wheel plate have 48 teeth/cycle,the edge is 96)";
CM_ SG_ 359 BCS_FRWheelSpdEdgesSum_B "Accumulated sum of rising and falling edges of front right wheel speed sensor output·since IGN ON( the wheel plate have 48 teeth/cycle,the edge is 96)";
CM_ SG_ 359 BCS_RLWheelSpdEdgesSum_B "Accumulated sum of rising and falling edges of rear left wheel speed sensor output·since IGN ON( the wheel plate have 48 teeth/cycle,the edge is 96)";
CM_ SG_ 359 BCS_RRWheelSpdEdgesSum_B "Accumulated sum of rising and falling edges of  rear right wheel speed sensor output·since IGN ON( the wheel plate have 48 teeth/cycle,the edge is 96)";
CM_ SG_ 359 BCS_FLWheelSpdEdgesSumVD_B "Quality/fault information to current wheel speed edges sum of front left wheel";
CM_ SG_ 359 BCS_FRWheelSpdEdgesSumVD_B "Quality/fault information to current wheel speed edges sum of front right wheel";
CM_ SG_ 359 BCS_RLWheelSpdEdgesSumVD_B "Quality/fault information to current wheel speed edges sum of rear left wheel";
CM_ SG_ 359 BCS_RRWheelSpdEdgesSumVD_B "Quality/fault information to current wheel speed edges sum of rear right wheel";
CM_ SG_ 359 BCS_FLWheelRotatedDirectionAPA_B "FL wheel rotate direction for APA";
CM_ SG_ 359 BCS_FRWheelRotatedDirectionAPA_B "FR wheel rotate direction for APA";
CM_ SG_ 359 BCS_RLWheelRotatedDirectionAPA_B "RL wheel rotate direction for APA";
CM_ SG_ 359 BCS_RRWheelRotatedDirectionAPA_B "RR wheel rotate direction for APA";
CM_ SG_ 359 BCS_ParkingReqToEPB_B "Indicates the release/lock brake request to EPB";
CM_ SG_ 359 BCS_VDCOff_B "VDC is switched off ";
CM_ SG_ 359 BCS_AVHSt_B "Indicates AVH(Auto Vehicle Hold)in active or not ";
CM_ SG_ 359 BCS_AVHStandby_B "Indicates AVH(Auto Vehicle Hold)in standby mode or not ";
CM_ SG_ 359 BCS_AVHAvailable_B "HMI responsible, can get degrate AVH(Auto Vehicle Hold) statement from DSW and send out ";
CM_ SG_ 359 BCS_TCSOff_B "TCS is switched off ";
CM_ SG_ 359 BCS_BrakeOverHeat_B "Indicating brake temperature too high or not";
CM_ SG_ 359 BCS_ABAactive_B "ABA(Adaptive Brake Assistance) is active";
CM_ SG_ 359 BCS_ABAavailable_B "The ABA(Adaptive Brake Assistance)  function is available";
CM_ SG_ 359 BCS_ABPActive_B "ABP(Automatic brake Pre-fill) is active";
CM_ SG_ 359 BCS_ABPAvailable_B "ABP(Automatic brake Pre-fill) is available";
CM_ SG_ 359 BCS_AEBActive_B "AEB(Automatic EmergencyBraking) is active (in deceleration)";
CM_ SG_ 359 BCS_AEBAvailable_B "AEB(Automatic EmergencyBraking) is available";
CM_ SG_ 359 BCS_AWBActive_B "AWB(Automatic Warning Brake) is active";
CM_ SG_ 359 BCS_AWBAvailable_B "AWB(Automatic Warning Brake) is available";
CM_ SG_ 359 BCS_VehicleStandStillSt_B "Indicating whether the vehicle is standstill or not;must not be set until standstill is surely reached.";
CM_ SG_ 359 BCS_AEBBAActive_B "Indicates AEBBA active or not";
CM_ SG_ 359 IPB_InputRodStroke_B "Indicate inputRod stroke value";
CM_ SG_ 359 IPB_InputRodStrokeSt_B "Indicate inputRod stroke status";
CM_ SG_ 359 BCS_RAEBActive_B "RAEB is active ";
CM_ SG_ 359 BCS_RAEBAvailable_B "RAEB is available ";
CM_ SG_ 359 IPB_PlungerPressureSt_B "Indicate plunger pressure status";
CM_ SG_ 359 IPB_PlungerPressure_B "Indicate plunger pressure value";
CM_ SG_ 359 BCS_BrkTqCtrlAvlDrivingRdn_B "It indicates  whether  ESP/IPB is available for cruise function ，in redunant mode,including L3/L4/L5.";
CM_ SG_ 359 BCS_BrkTqCtrlActvRdn_B "It indicates  whether  ESP/IPB is  responsed for the brake request of ADAS, in redunant mode,including L3/L4/L5.";
CM_ SG_ 359 BCS_L3CommunicationVld_B "The validity of CAN bus communication .";
CM_ SG_ 359 BCS_LFIActiveSt_B "The activation status of the LFI function。";

BA_DEF_ BO_  "GenMsgCycleTime" INT 0 0;
BA_DEF_ BO_  "GenMsgCycleTimeFast" INT 0 0;
BA_DEF_ BO_  "GenMsgSendType" ENUM  "Periodic","Event","IfActive","POE","PA","FixedPeriodic","Event","EnabledPeriodic","NotUsed","NotUsed","EventPeriodic","NotUsed","NotUsed","NoMsgSendType";
BA_DEF_ BO_  "VFrameFormat" ENUM  "StandardCAN","ExtendedCAN","reserved","reserved","reserved","reserved","reserved","reserved","reserved","reserved","reserved","reserved","reserved","reserved","StandardCAN_FD","ExtendedCAN_FD";
BA_DEF_ BO_  "CANFD_BRS" ENUM  "0","1";
BA_DEF_ SG_  "EventCommandSignal" ENUM  "No","Yes";
BA_DEF_ SG_  "GatewayedSignals" ENUM  "No","Yes";
BA_DEF_ SG_  "GenSigInactiveValue" HEX 0 0;
BA_DEF_ SG_  "GenSigInvalidValue" HEX 0 0;
BA_DEF_ SG_  "GenSigSendType" ENUM  "Trigger","Passive","Cyclic","OnWrite","OnWriteWithRepetition","OnChange","OnChangeWithRepetition","IfActive","IfActiveWithRepetition","NoSigSendType";
BA_DEF_ SG_  "GenSigStartValue" HEX 0 0;
BA_DEF_ SG_  "GenSigTimeoutValue" HEX 0 0;
BA_DEF_ SG_  "Remark" STRING ;
BA_DEF_  "Manufacturer" STRING ;
BA_DEF_  "Project" STRING ;
BA_DEF_  "Version" STRING ;
BA_DEF_  "Date" STRING ;
BA_DEF_  "Author" STRING ;
BA_DEF_  "DBName" STRING ;
BA_DEF_  "BusType" STRING ;
BA_DEF_  "Checker" STRING ;
BA_DEF_  "Approver" STRING ;
BA_ "Manufacturer" "GACRND";
BA_ "Project" "A88";
BA_ "Version" "0.1";
BA_ "Date" "2026/7/27 10:55:45";
BA_ "Author" "LeoFeng";
BA_ "DBName" "ADCPublic_CANFD2";
BA_ "BusType" "CAN FD";
BA_ "Checker" "Miss Fan";
BA_ "Approver" "Mr Hu";

BA_ "GenMsgCycleTime" BO_ 2015 0;
BA_ "GenMsgCycleTimeFast" BO_ 2015 0;
BA_ "GenMsgSendType" BO_ 2015 1;
BA_ "VFrameFormat" BO_ 2015 14;
BA_ "CANFD_BRS" BO_ 2015 1;
BA_ "GenMsgCycleTime" BO_ 368 10;
BA_ "GenMsgCycleTimeFast" BO_ 368 0;
BA_ "GenMsgSendType" BO_ 368 0;
BA_ "VFrameFormat" BO_ 368 14;
BA_ "CANFD_BRS" BO_ 368 1;
BA_ "GenMsgCycleTime" BO_ 368 10;
BA_ "GenMsgCycleTimeFast" BO_ 368 0;
BA_ "GenMsgSendType" BO_ 368 0;
BA_ "VFrameFormat" BO_ 368 14;
BA_ "CANFD_BRS" BO_ 368 1;
BA_ "GenMsgCycleTime" BO_ 368 10;
BA_ "GenMsgCycleTimeFast" BO_ 368 0;
BA_ "GenMsgSendType" BO_ 368 0;
BA_ "VFrameFormat" BO_ 368 14;
BA_ "CANFD_BRS" BO_ 368 1;
BA_ "GenMsgCycleTime" BO_ 368 10;
BA_ "GenMsgCycleTimeFast" BO_ 368 0;
BA_ "GenMsgSendType" BO_ 368 0;
BA_ "VFrameFormat" BO_ 368 14;
BA_ "CANFD_BRS" BO_ 368 1;
BA_ "GenMsgCycleTime" BO_ 368 10;
BA_ "GenMsgCycleTimeFast" BO_ 368 0;
BA_ "GenMsgSendType" BO_ 368 0;
BA_ "VFrameFormat" BO_ 368 14;
BA_ "CANFD_BRS" BO_ 368 1;
BA_ "GenMsgCycleTime" BO_ 368 10;
BA_ "GenMsgCycleTimeFast" BO_ 368 0;
BA_ "GenMsgSendType" BO_ 368 0;
BA_ "VFrameFormat" BO_ 368 14;
BA_ "CANFD_BRS" BO_ 368 1;
BA_ "GenMsgCycleTime" BO_ 368 10;
BA_ "GenMsgCycleTimeFast" BO_ 368 0;
BA_ "GenMsgSendType" BO_ 368 0;
BA_ "VFrameFormat" BO_ 368 14;
BA_ "CANFD_BRS" BO_ 368 1;
BA_ "GenMsgCycleTime" BO_ 368 10;
BA_ "GenMsgCycleTimeFast" BO_ 368 0;
BA_ "GenMsgSendType" BO_ 368 0;
BA_ "VFrameFormat" BO_ 368 14;
BA_ "CANFD_BRS" BO_ 368 1;
BA_ "GenMsgCycleTime" BO_ 368 10;
BA_ "GenMsgCycleTimeFast" BO_ 368 0;
BA_ "GenMsgSendType" BO_ 368 0;
BA_ "VFrameFormat" BO_ 368 14;
BA_ "CANFD_BRS" BO_ 368 1;
BA_ "GenMsgCycleTime" BO_ 368 10;
BA_ "GenMsgCycleTimeFast" BO_ 368 0;
BA_ "GenMsgSendType" BO_ 368 0;
BA_ "VFrameFormat" BO_ 368 14;
BA_ "CANFD_BRS" BO_ 368 1;
BA_ "GenMsgCycleTime" BO_ 368 10;
BA_ "GenMsgCycleTimeFast" BO_ 368 0;
BA_ "GenMsgSendType" BO_ 368 0;
BA_ "VFrameFormat" BO_ 368 14;
BA_ "CANFD_BRS" BO_ 368 1;
BA_ "GenMsgCycleTime" BO_ 369 10;
BA_ "GenMsgCycleTimeFast" BO_ 369 0;
BA_ "GenMsgSendType" BO_ 369 0;
BA_ "VFrameFormat" BO_ 369 14;
BA_ "CANFD_BRS" BO_ 369 1;
BA_ "GenMsgCycleTime" BO_ 369 10;
BA_ "GenMsgCycleTimeFast" BO_ 369 0;
BA_ "GenMsgSendType" BO_ 369 0;
BA_ "VFrameFormat" BO_ 369 14;
BA_ "CANFD_BRS" BO_ 369 1;
BA_ "GenMsgCycleTime" BO_ 369 10;
BA_ "GenMsgCycleTimeFast" BO_ 369 0;
BA_ "GenMsgSendType" BO_ 369 0;
BA_ "VFrameFormat" BO_ 369 14;
BA_ "CANFD_BRS" BO_ 369 1;
BA_ "GenMsgCycleTime" BO_ 369 10;
BA_ "GenMsgCycleTimeFast" BO_ 369 0;
BA_ "GenMsgSendType" BO_ 369 0;
BA_ "VFrameFormat" BO_ 369 14;
BA_ "CANFD_BRS" BO_ 369 1;
BA_ "GenMsgCycleTime" BO_ 369 10;
BA_ "GenMsgCycleTimeFast" BO_ 369 0;
BA_ "GenMsgSendType" BO_ 369 0;
BA_ "VFrameFormat" BO_ 369 14;
BA_ "CANFD_BRS" BO_ 369 1;
BA_ "GenMsgCycleTime" BO_ 369 10;
BA_ "GenMsgCycleTimeFast" BO_ 369 0;
BA_ "GenMsgSendType" BO_ 369 0;
BA_ "VFrameFormat" BO_ 369 14;
BA_ "CANFD_BRS" BO_ 369 1;
BA_ "GenMsgCycleTime" BO_ 369 10;
BA_ "GenMsgCycleTimeFast" BO_ 369 0;
BA_ "GenMsgSendType" BO_ 369 0;
BA_ "VFrameFormat" BO_ 369 14;
BA_ "CANFD_BRS" BO_ 369 1;
BA_ "GenMsgCycleTime" BO_ 369 10;
BA_ "GenMsgCycleTimeFast" BO_ 369 0;
BA_ "GenMsgSendType" BO_ 369 0;
BA_ "VFrameFormat" BO_ 369 14;
BA_ "CANFD_BRS" BO_ 369 1;
BA_ "GenMsgCycleTime" BO_ 369 10;
BA_ "GenMsgCycleTimeFast" BO_ 369 0;
BA_ "GenMsgSendType" BO_ 369 0;
BA_ "VFrameFormat" BO_ 369 14;
BA_ "CANFD_BRS" BO_ 369 1;
BA_ "GenMsgCycleTime" BO_ 369 10;
BA_ "GenMsgCycleTimeFast" BO_ 369 0;
BA_ "GenMsgSendType" BO_ 369 0;
BA_ "VFrameFormat" BO_ 369 14;
BA_ "CANFD_BRS" BO_ 369 1;
BA_ "GenMsgCycleTime" BO_ 513 10;
BA_ "GenMsgCycleTimeFast" BO_ 513 0;
BA_ "GenMsgSendType" BO_ 513 0;
BA_ "VFrameFormat" BO_ 513 14;
BA_ "CANFD_BRS" BO_ 513 1;
BA_ "GenMsgCycleTime" BO_ 513 10;
BA_ "GenMsgCycleTimeFast" BO_ 513 0;
BA_ "GenMsgSendType" BO_ 513 0;
BA_ "VFrameFormat" BO_ 513 14;
BA_ "CANFD_BRS" BO_ 513 1;
BA_ "GenMsgCycleTime" BO_ 860 100;
BA_ "GenMsgCycleTimeFast" BO_ 860 0;
BA_ "GenMsgSendType" BO_ 860 0;
BA_ "VFrameFormat" BO_ 860 14;
BA_ "CANFD_BRS" BO_ 860 1;
BA_ "GenMsgCycleTime" BO_ 860 100;
BA_ "GenMsgCycleTimeFast" BO_ 860 0;
BA_ "GenMsgSendType" BO_ 860 0;
BA_ "VFrameFormat" BO_ 860 14;
BA_ "CANFD_BRS" BO_ 860 1;
BA_ "GenMsgCycleTime" BO_ 860 100;
BA_ "GenMsgCycleTimeFast" BO_ 860 0;
BA_ "GenMsgSendType" BO_ 860 0;
BA_ "VFrameFormat" BO_ 860 14;
BA_ "CANFD_BRS" BO_ 860 1;
BA_ "GenMsgCycleTime" BO_ 860 100;
BA_ "GenMsgCycleTimeFast" BO_ 860 0;
BA_ "GenMsgSendType" BO_ 860 0;
BA_ "VFrameFormat" BO_ 860 14;
BA_ "CANFD_BRS" BO_ 860 1;
BA_ "GenMsgCycleTime" BO_ 860 100;
BA_ "GenMsgCycleTimeFast" BO_ 860 0;
BA_ "GenMsgSendType" BO_ 860 0;
BA_ "VFrameFormat" BO_ 860 14;
BA_ "CANFD_BRS" BO_ 860 1;
BA_ "GenMsgCycleTime" BO_ 860 100;
BA_ "GenMsgCycleTimeFast" BO_ 860 0;
BA_ "GenMsgSendType" BO_ 860 0;
BA_ "VFrameFormat" BO_ 860 14;
BA_ "CANFD_BRS" BO_ 860 1;
BA_ "GenMsgCycleTime" BO_ 860 100;
BA_ "GenMsgCycleTimeFast" BO_ 860 0;
BA_ "GenMsgSendType" BO_ 860 0;
BA_ "VFrameFormat" BO_ 860 14;
BA_ "CANFD_BRS" BO_ 860 1;
BA_ "GenMsgCycleTime" BO_ 860 100;
BA_ "GenMsgCycleTimeFast" BO_ 860 0;
BA_ "GenMsgSendType" BO_ 860 0;
BA_ "VFrameFormat" BO_ 860 14;
BA_ "CANFD_BRS" BO_ 860 1;
BA_ "GenMsgCycleTime" BO_ 860 100;
BA_ "GenMsgCycleTimeFast" BO_ 860 0;
BA_ "GenMsgSendType" BO_ 860 0;
BA_ "VFrameFormat" BO_ 860 14;
BA_ "CANFD_BRS" BO_ 860 1;
BA_ "GenMsgCycleTime" BO_ 860 100;
BA_ "GenMsgCycleTimeFast" BO_ 860 0;
BA_ "GenMsgSendType" BO_ 860 0;
BA_ "VFrameFormat" BO_ 860 14;
BA_ "CANFD_BRS" BO_ 860 1;
BA_ "GenMsgCycleTime" BO_ 860 100;
BA_ "GenMsgCycleTimeFast" BO_ 860 0;
BA_ "GenMsgSendType" BO_ 860 0;
BA_ "VFrameFormat" BO_ 860 14;
BA_ "CANFD_BRS" BO_ 860 1;
BA_ "GenMsgCycleTime" BO_ 860 100;
BA_ "GenMsgCycleTimeFast" BO_ 860 0;
BA_ "GenMsgSendType" BO_ 860 0;
BA_ "VFrameFormat" BO_ 860 14;
BA_ "CANFD_BRS" BO_ 860 1;
BA_ "GenMsgCycleTime" BO_ 860 100;
BA_ "GenMsgCycleTimeFast" BO_ 860 0;
BA_ "GenMsgSendType" BO_ 860 0;
BA_ "VFrameFormat" BO_ 860 14;
BA_ "CANFD_BRS" BO_ 860 1;
BA_ "GenMsgCycleTime" BO_ 860 100;
BA_ "GenMsgCycleTimeFast" BO_ 860 0;
BA_ "GenMsgSendType" BO_ 860 0;
BA_ "VFrameFormat" BO_ 860 14;
BA_ "CANFD_BRS" BO_ 860 1;
BA_ "GenMsgCycleTime" BO_ 860 100;
BA_ "GenMsgCycleTimeFast" BO_ 860 0;
BA_ "GenMsgSendType" BO_ 860 0;
BA_ "VFrameFormat" BO_ 860 14;
BA_ "CANFD_BRS" BO_ 860 1;
BA_ "GenMsgCycleTime" BO_ 860 100;
BA_ "GenMsgCycleTimeFast" BO_ 860 0;
BA_ "GenMsgSendType" BO_ 860 0;
BA_ "VFrameFormat" BO_ 860 14;
BA_ "CANFD_BRS" BO_ 860 1;
BA_ "GenMsgCycleTime" BO_ 860 100;
BA_ "GenMsgCycleTimeFast" BO_ 860 0;
BA_ "GenMsgSendType" BO_ 860 0;
BA_ "VFrameFormat" BO_ 860 14;
BA_ "CANFD_BRS" BO_ 860 1;
BA_ "GenMsgCycleTime" BO_ 860 100;
BA_ "GenMsgCycleTimeFast" BO_ 860 0;
BA_ "GenMsgSendType" BO_ 860 0;
BA_ "VFrameFormat" BO_ 860 14;
BA_ "CANFD_BRS" BO_ 860 1;
BA_ "GenMsgCycleTime" BO_ 431 10;
BA_ "GenMsgCycleTimeFast" BO_ 431 0;
BA_ "GenMsgSendType" BO_ 431 0;
BA_ "VFrameFormat" BO_ 431 14;
BA_ "CANFD_BRS" BO_ 431 1;
BA_ "GenMsgCycleTime" BO_ 431 10;
BA_ "GenMsgCycleTimeFast" BO_ 431 0;
BA_ "GenMsgSendType" BO_ 431 0;
BA_ "VFrameFormat" BO_ 431 14;
BA_ "CANFD_BRS" BO_ 431 1;
BA_ "GenMsgCycleTime" BO_ 431 10;
BA_ "GenMsgCycleTimeFast" BO_ 431 0;
BA_ "GenMsgSendType" BO_ 431 0;
BA_ "VFrameFormat" BO_ 431 14;
BA_ "CANFD_BRS" BO_ 431 1;
BA_ "GenMsgCycleTime" BO_ 431 10;
BA_ "GenMsgCycleTimeFast" BO_ 431 0;
BA_ "GenMsgSendType" BO_ 431 0;
BA_ "VFrameFormat" BO_ 431 14;
BA_ "CANFD_BRS" BO_ 431 1;
BA_ "GenMsgCycleTime" BO_ 431 10;
BA_ "GenMsgCycleTimeFast" BO_ 431 0;
BA_ "GenMsgSendType" BO_ 431 0;
BA_ "VFrameFormat" BO_ 431 14;
BA_ "CANFD_BRS" BO_ 431 1;
BA_ "GenMsgCycleTime" BO_ 431 10;
BA_ "GenMsgCycleTimeFast" BO_ 431 0;
BA_ "GenMsgSendType" BO_ 431 0;
BA_ "VFrameFormat" BO_ 431 14;
BA_ "CANFD_BRS" BO_ 431 1;
BA_ "GenMsgCycleTime" BO_ 431 10;
BA_ "GenMsgCycleTimeFast" BO_ 431 0;
BA_ "GenMsgSendType" BO_ 431 0;
BA_ "VFrameFormat" BO_ 431 14;
BA_ "CANFD_BRS" BO_ 431 1;
BA_ "GenMsgCycleTime" BO_ 431 10;
BA_ "GenMsgCycleTimeFast" BO_ 431 0;
BA_ "GenMsgSendType" BO_ 431 0;
BA_ "VFrameFormat" BO_ 431 14;
BA_ "CANFD_BRS" BO_ 431 1;
BA_ "GenMsgCycleTime" BO_ 431 10;
BA_ "GenMsgCycleTimeFast" BO_ 431 0;
BA_ "GenMsgSendType" BO_ 431 0;
BA_ "VFrameFormat" BO_ 431 14;
BA_ "CANFD_BRS" BO_ 431 1;
BA_ "GenMsgCycleTime" BO_ 431 10;
BA_ "GenMsgCycleTimeFast" BO_ 431 0;
BA_ "GenMsgSendType" BO_ 431 0;
BA_ "VFrameFormat" BO_ 431 14;
BA_ "CANFD_BRS" BO_ 431 1;
BA_ "GenMsgCycleTime" BO_ 431 10;
BA_ "GenMsgCycleTimeFast" BO_ 431 0;
BA_ "GenMsgSendType" BO_ 431 0;
BA_ "VFrameFormat" BO_ 431 14;
BA_ "CANFD_BRS" BO_ 431 1;
BA_ "GenMsgCycleTime" BO_ 431 10;
BA_ "GenMsgCycleTimeFast" BO_ 431 0;
BA_ "GenMsgSendType" BO_ 431 0;
BA_ "VFrameFormat" BO_ 431 14;
BA_ "CANFD_BRS" BO_ 431 1;
BA_ "GenMsgCycleTime" BO_ 431 10;
BA_ "GenMsgCycleTimeFast" BO_ 431 0;
BA_ "GenMsgSendType" BO_ 431 0;
BA_ "VFrameFormat" BO_ 431 14;
BA_ "CANFD_BRS" BO_ 431 1;
BA_ "GenMsgCycleTime" BO_ 431 10;
BA_ "GenMsgCycleTimeFast" BO_ 431 0;
BA_ "GenMsgSendType" BO_ 431 0;
BA_ "VFrameFormat" BO_ 431 14;
BA_ "CANFD_BRS" BO_ 431 1;
BA_ "GenMsgCycleTime" BO_ 431 10;
BA_ "GenMsgCycleTimeFast" BO_ 431 0;
BA_ "GenMsgSendType" BO_ 431 0;
BA_ "VFrameFormat" BO_ 431 14;
BA_ "CANFD_BRS" BO_ 431 1;
BA_ "GenMsgCycleTime" BO_ 431 10;
BA_ "GenMsgCycleTimeFast" BO_ 431 0;
BA_ "GenMsgSendType" BO_ 431 0;
BA_ "VFrameFormat" BO_ 431 14;
BA_ "CANFD_BRS" BO_ 431 1;
BA_ "GenMsgCycleTime" BO_ 431 10;
BA_ "GenMsgCycleTimeFast" BO_ 431 0;
BA_ "GenMsgSendType" BO_ 431 0;
BA_ "VFrameFormat" BO_ 431 14;
BA_ "CANFD_BRS" BO_ 431 1;
BA_ "GenMsgCycleTime" BO_ 431 10;
BA_ "GenMsgCycleTimeFast" BO_ 431 0;
BA_ "GenMsgSendType" BO_ 431 0;
BA_ "VFrameFormat" BO_ 431 14;
BA_ "CANFD_BRS" BO_ 431 1;
BA_ "GenMsgCycleTime" BO_ 431 10;
BA_ "GenMsgCycleTimeFast" BO_ 431 0;
BA_ "GenMsgSendType" BO_ 431 0;
BA_ "VFrameFormat" BO_ 431 14;
BA_ "CANFD_BRS" BO_ 431 1;
BA_ "GenMsgCycleTime" BO_ 431 10;
BA_ "GenMsgCycleTimeFast" BO_ 431 0;
BA_ "GenMsgSendType" BO_ 431 0;
BA_ "VFrameFormat" BO_ 431 14;
BA_ "CANFD_BRS" BO_ 431 1;
BA_ "GenMsgCycleTime" BO_ 431 10;
BA_ "GenMsgCycleTimeFast" BO_ 431 0;
BA_ "GenMsgSendType" BO_ 431 0;
BA_ "VFrameFormat" BO_ 431 14;
BA_ "CANFD_BRS" BO_ 431 1;
BA_ "GenMsgCycleTime" BO_ 431 10;
BA_ "GenMsgCycleTimeFast" BO_ 431 0;
BA_ "GenMsgSendType" BO_ 431 0;
BA_ "VFrameFormat" BO_ 431 14;
BA_ "CANFD_BRS" BO_ 431 1;
BA_ "GenMsgCycleTime" BO_ 431 10;
BA_ "GenMsgCycleTimeFast" BO_ 431 0;
BA_ "GenMsgSendType" BO_ 431 0;
BA_ "VFrameFormat" BO_ 431 14;
BA_ "CANFD_BRS" BO_ 431 1;
BA_ "GenMsgCycleTime" BO_ 431 10;
BA_ "GenMsgCycleTimeFast" BO_ 431 0;
BA_ "GenMsgSendType" BO_ 431 0;
BA_ "VFrameFormat" BO_ 431 14;
BA_ "CANFD_BRS" BO_ 431 1;
BA_ "GenMsgCycleTime" BO_ 431 10;
BA_ "GenMsgCycleTimeFast" BO_ 431 0;
BA_ "GenMsgSendType" BO_ 431 0;
BA_ "VFrameFormat" BO_ 431 14;
BA_ "CANFD_BRS" BO_ 431 1;
BA_ "GenMsgCycleTime" BO_ 516 20;
BA_ "GenMsgCycleTimeFast" BO_ 516 0;
BA_ "GenMsgSendType" BO_ 516 0;
BA_ "VFrameFormat" BO_ 516 14;
BA_ "CANFD_BRS" BO_ 516 1;
BA_ "GenMsgCycleTime" BO_ 516 20;
BA_ "GenMsgCycleTimeFast" BO_ 516 0;
BA_ "GenMsgSendType" BO_ 516 0;
BA_ "VFrameFormat" BO_ 516 14;
BA_ "CANFD_BRS" BO_ 516 1;
BA_ "GenMsgCycleTime" BO_ 516 20;
BA_ "GenMsgCycleTimeFast" BO_ 516 0;
BA_ "GenMsgSendType" BO_ 516 0;
BA_ "VFrameFormat" BO_ 516 14;
BA_ "CANFD_BRS" BO_ 516 1;
BA_ "GenMsgCycleTime" BO_ 516 20;
BA_ "GenMsgCycleTimeFast" BO_ 516 0;
BA_ "GenMsgSendType" BO_ 516 0;
BA_ "VFrameFormat" BO_ 516 14;
BA_ "CANFD_BRS" BO_ 516 1;
BA_ "GenMsgCycleTime" BO_ 516 20;
BA_ "GenMsgCycleTimeFast" BO_ 516 0;
BA_ "GenMsgSendType" BO_ 516 0;
BA_ "VFrameFormat" BO_ 516 14;
BA_ "CANFD_BRS" BO_ 516 1;
BA_ "GenMsgCycleTime" BO_ 516 20;
BA_ "GenMsgCycleTimeFast" BO_ 516 0;
BA_ "GenMsgSendType" BO_ 516 0;
BA_ "VFrameFormat" BO_ 516 14;
BA_ "CANFD_BRS" BO_ 516 1;
BA_ "GenMsgCycleTime" BO_ 516 20;
BA_ "GenMsgCycleTimeFast" BO_ 516 0;
BA_ "GenMsgSendType" BO_ 516 0;
BA_ "VFrameFormat" BO_ 516 14;
BA_ "CANFD_BRS" BO_ 516 1;
BA_ "GenMsgCycleTime" BO_ 516 20;
BA_ "GenMsgCycleTimeFast" BO_ 516 0;
BA_ "GenMsgSendType" BO_ 516 0;
BA_ "VFrameFormat" BO_ 516 14;
BA_ "CANFD_BRS" BO_ 516 1;
BA_ "GenMsgCycleTime" BO_ 516 20;
BA_ "GenMsgCycleTimeFast" BO_ 516 0;
BA_ "GenMsgSendType" BO_ 516 0;
BA_ "VFrameFormat" BO_ 516 14;
BA_ "CANFD_BRS" BO_ 516 1;
BA_ "GenMsgCycleTime" BO_ 516 20;
BA_ "GenMsgCycleTimeFast" BO_ 516 0;
BA_ "GenMsgSendType" BO_ 516 0;
BA_ "VFrameFormat" BO_ 516 14;
BA_ "CANFD_BRS" BO_ 516 1;
BA_ "GenMsgCycleTime" BO_ 516 20;
BA_ "GenMsgCycleTimeFast" BO_ 516 0;
BA_ "GenMsgSendType" BO_ 516 0;
BA_ "VFrameFormat" BO_ 516 14;
BA_ "CANFD_BRS" BO_ 516 1;
BA_ "GenMsgCycleTime" BO_ 516 20;
BA_ "GenMsgCycleTimeFast" BO_ 516 0;
BA_ "GenMsgSendType" BO_ 516 0;
BA_ "VFrameFormat" BO_ 516 14;
BA_ "CANFD_BRS" BO_ 516 1;
BA_ "GenMsgCycleTime" BO_ 516 20;
BA_ "GenMsgCycleTimeFast" BO_ 516 0;
BA_ "GenMsgSendType" BO_ 516 0;
BA_ "VFrameFormat" BO_ 516 14;
BA_ "CANFD_BRS" BO_ 516 1;
BA_ "GenMsgCycleTime" BO_ 516 20;
BA_ "GenMsgCycleTimeFast" BO_ 516 0;
BA_ "GenMsgSendType" BO_ 516 0;
BA_ "VFrameFormat" BO_ 516 14;
BA_ "CANFD_BRS" BO_ 516 1;
BA_ "GenMsgCycleTime" BO_ 516 20;
BA_ "GenMsgCycleTimeFast" BO_ 516 0;
BA_ "GenMsgSendType" BO_ 516 0;
BA_ "VFrameFormat" BO_ 516 14;
BA_ "CANFD_BRS" BO_ 516 1;
BA_ "GenMsgCycleTime" BO_ 516 20;
BA_ "GenMsgCycleTimeFast" BO_ 516 0;
BA_ "GenMsgSendType" BO_ 516 0;
BA_ "VFrameFormat" BO_ 516 14;
BA_ "CANFD_BRS" BO_ 516 1;
BA_ "GenMsgCycleTime" BO_ 516 20;
BA_ "GenMsgCycleTimeFast" BO_ 516 0;
BA_ "GenMsgSendType" BO_ 516 0;
BA_ "VFrameFormat" BO_ 516 14;
BA_ "CANFD_BRS" BO_ 516 1;
BA_ "GenMsgCycleTime" BO_ 516 20;
BA_ "GenMsgCycleTimeFast" BO_ 516 0;
BA_ "GenMsgSendType" BO_ 516 0;
BA_ "VFrameFormat" BO_ 516 14;
BA_ "CANFD_BRS" BO_ 516 1;
BA_ "GenMsgCycleTime" BO_ 516 20;
BA_ "GenMsgCycleTimeFast" BO_ 516 0;
BA_ "GenMsgSendType" BO_ 516 0;
BA_ "VFrameFormat" BO_ 516 14;
BA_ "CANFD_BRS" BO_ 516 1;
BA_ "GenMsgCycleTime" BO_ 516 20;
BA_ "GenMsgCycleTimeFast" BO_ 516 0;
BA_ "GenMsgSendType" BO_ 516 0;
BA_ "VFrameFormat" BO_ 516 14;
BA_ "CANFD_BRS" BO_ 516 1;
BA_ "GenMsgCycleTime" BO_ 516 20;
BA_ "GenMsgCycleTimeFast" BO_ 516 0;
BA_ "GenMsgSendType" BO_ 516 0;
BA_ "VFrameFormat" BO_ 516 14;
BA_ "CANFD_BRS" BO_ 516 1;
BA_ "GenMsgCycleTime" BO_ 516 20;
BA_ "GenMsgCycleTimeFast" BO_ 516 0;
BA_ "GenMsgSendType" BO_ 516 0;
BA_ "VFrameFormat" BO_ 516 14;
BA_ "CANFD_BRS" BO_ 516 1;
BA_ "GenMsgCycleTime" BO_ 516 20;
BA_ "GenMsgCycleTimeFast" BO_ 516 0;
BA_ "GenMsgSendType" BO_ 516 0;
BA_ "VFrameFormat" BO_ 516 14;
BA_ "CANFD_BRS" BO_ 516 1;
BA_ "GenMsgCycleTime" BO_ 516 20;
BA_ "GenMsgCycleTimeFast" BO_ 516 0;
BA_ "GenMsgSendType" BO_ 516 0;
BA_ "VFrameFormat" BO_ 516 14;
BA_ "CANFD_BRS" BO_ 516 1;
BA_ "GenMsgCycleTime" BO_ 516 20;
BA_ "GenMsgCycleTimeFast" BO_ 516 0;
BA_ "GenMsgSendType" BO_ 516 0;
BA_ "VFrameFormat" BO_ 516 14;
BA_ "CANFD_BRS" BO_ 516 1;
BA_ "GenMsgCycleTime" BO_ 516 20;
BA_ "GenMsgCycleTimeFast" BO_ 516 0;
BA_ "GenMsgSendType" BO_ 516 0;
BA_ "VFrameFormat" BO_ 516 14;
BA_ "CANFD_BRS" BO_ 516 1;
BA_ "GenMsgCycleTime" BO_ 516 20;
BA_ "GenMsgCycleTimeFast" BO_ 516 0;
BA_ "GenMsgSendType" BO_ 516 0;
BA_ "VFrameFormat" BO_ 516 14;
BA_ "CANFD_BRS" BO_ 516 1;
BA_ "GenMsgCycleTime" BO_ 516 20;
BA_ "GenMsgCycleTimeFast" BO_ 516 0;
BA_ "GenMsgSendType" BO_ 516 0;
BA_ "VFrameFormat" BO_ 516 14;
BA_ "CANFD_BRS" BO_ 516 1;
BA_ "GenMsgCycleTime" BO_ 516 20;
BA_ "GenMsgCycleTimeFast" BO_ 516 0;
BA_ "GenMsgSendType" BO_ 516 0;
BA_ "VFrameFormat" BO_ 516 14;
BA_ "CANFD_BRS" BO_ 516 1;
BA_ "GenMsgCycleTime" BO_ 516 20;
BA_ "GenMsgCycleTimeFast" BO_ 516 0;
BA_ "GenMsgSendType" BO_ 516 0;
BA_ "VFrameFormat" BO_ 516 14;
BA_ "CANFD_BRS" BO_ 516 1;
BA_ "GenMsgCycleTime" BO_ 516 20;
BA_ "GenMsgCycleTimeFast" BO_ 516 0;
BA_ "GenMsgSendType" BO_ 516 0;
BA_ "VFrameFormat" BO_ 516 14;
BA_ "CANFD_BRS" BO_ 516 1;
BA_ "GenMsgCycleTime" BO_ 516 20;
BA_ "GenMsgCycleTimeFast" BO_ 516 0;
BA_ "GenMsgSendType" BO_ 516 0;
BA_ "VFrameFormat" BO_ 516 14;
BA_ "CANFD_BRS" BO_ 516 1;
BA_ "GenMsgCycleTime" BO_ 516 20;
BA_ "GenMsgCycleTimeFast" BO_ 516 0;
BA_ "GenMsgSendType" BO_ 516 0;
BA_ "VFrameFormat" BO_ 516 14;
BA_ "CANFD_BRS" BO_ 516 1;
BA_ "GenMsgCycleTime" BO_ 516 20;
BA_ "GenMsgCycleTimeFast" BO_ 516 0;
BA_ "GenMsgSendType" BO_ 516 0;
BA_ "VFrameFormat" BO_ 516 14;
BA_ "CANFD_BRS" BO_ 516 1;
BA_ "GenMsgCycleTime" BO_ 516 20;
BA_ "GenMsgCycleTimeFast" BO_ 516 0;
BA_ "GenMsgSendType" BO_ 516 0;
BA_ "VFrameFormat" BO_ 516 14;
BA_ "CANFD_BRS" BO_ 516 1;
BA_ "GenMsgCycleTime" BO_ 516 20;
BA_ "GenMsgCycleTimeFast" BO_ 516 0;
BA_ "GenMsgSendType" BO_ 516 0;
BA_ "VFrameFormat" BO_ 516 14;
BA_ "CANFD_BRS" BO_ 516 1;
BA_ "GenMsgCycleTime" BO_ 516 20;
BA_ "GenMsgCycleTimeFast" BO_ 516 0;
BA_ "GenMsgSendType" BO_ 516 0;
BA_ "VFrameFormat" BO_ 516 14;
BA_ "CANFD_BRS" BO_ 516 1;
BA_ "GenMsgCycleTime" BO_ 516 20;
BA_ "GenMsgCycleTimeFast" BO_ 516 0;
BA_ "GenMsgSendType" BO_ 516 0;
BA_ "VFrameFormat" BO_ 516 14;
BA_ "CANFD_BRS" BO_ 516 1;
BA_ "GenMsgCycleTime" BO_ 516 20;
BA_ "GenMsgCycleTimeFast" BO_ 516 0;
BA_ "GenMsgSendType" BO_ 516 0;
BA_ "VFrameFormat" BO_ 516 14;
BA_ "CANFD_BRS" BO_ 516 1;
BA_ "GenMsgCycleTime" BO_ 516 20;
BA_ "GenMsgCycleTimeFast" BO_ 516 0;
BA_ "GenMsgSendType" BO_ 516 0;
BA_ "VFrameFormat" BO_ 516 14;
BA_ "CANFD_BRS" BO_ 516 1;
BA_ "GenMsgCycleTime" BO_ 516 20;
BA_ "GenMsgCycleTimeFast" BO_ 516 0;
BA_ "GenMsgSendType" BO_ 516 0;
BA_ "VFrameFormat" BO_ 516 14;
BA_ "CANFD_BRS" BO_ 516 1;
BA_ "GenMsgCycleTime" BO_ 516 20;
BA_ "GenMsgCycleTimeFast" BO_ 516 0;
BA_ "GenMsgSendType" BO_ 516 0;
BA_ "VFrameFormat" BO_ 516 14;
BA_ "CANFD_BRS" BO_ 516 1;
BA_ "GenMsgCycleTime" BO_ 516 20;
BA_ "GenMsgCycleTimeFast" BO_ 516 0;
BA_ "GenMsgSendType" BO_ 516 0;
BA_ "VFrameFormat" BO_ 516 14;
BA_ "CANFD_BRS" BO_ 516 1;
BA_ "GenMsgCycleTime" BO_ 516 20;
BA_ "GenMsgCycleTimeFast" BO_ 516 0;
BA_ "GenMsgSendType" BO_ 516 0;
BA_ "VFrameFormat" BO_ 516 14;
BA_ "CANFD_BRS" BO_ 516 1;
BA_ "GenMsgCycleTime" BO_ 516 20;
BA_ "GenMsgCycleTimeFast" BO_ 516 0;
BA_ "GenMsgSendType" BO_ 516 0;
BA_ "VFrameFormat" BO_ 516 14;
BA_ "CANFD_BRS" BO_ 516 1;
BA_ "GenMsgCycleTime" BO_ 516 20;
BA_ "GenMsgCycleTimeFast" BO_ 516 0;
BA_ "GenMsgSendType" BO_ 516 0;
BA_ "VFrameFormat" BO_ 516 14;
BA_ "CANFD_BRS" BO_ 516 1;
BA_ "GenMsgCycleTime" BO_ 616 20;
BA_ "GenMsgCycleTimeFast" BO_ 616 0;
BA_ "GenMsgSendType" BO_ 616 0;
BA_ "VFrameFormat" BO_ 616 14;
BA_ "CANFD_BRS" BO_ 616 1;
BA_ "GenMsgCycleTime" BO_ 616 20;
BA_ "GenMsgCycleTimeFast" BO_ 616 0;
BA_ "GenMsgSendType" BO_ 616 0;
BA_ "VFrameFormat" BO_ 616 14;
BA_ "CANFD_BRS" BO_ 616 1;
BA_ "GenMsgCycleTime" BO_ 616 20;
BA_ "GenMsgCycleTimeFast" BO_ 616 0;
BA_ "GenMsgSendType" BO_ 616 0;
BA_ "VFrameFormat" BO_ 616 14;
BA_ "CANFD_BRS" BO_ 616 1;
BA_ "GenMsgCycleTime" BO_ 616 20;
BA_ "GenMsgCycleTimeFast" BO_ 616 0;
BA_ "GenMsgSendType" BO_ 616 0;
BA_ "VFrameFormat" BO_ 616 14;
BA_ "CANFD_BRS" BO_ 616 1;
BA_ "GenMsgCycleTime" BO_ 616 20;
BA_ "GenMsgCycleTimeFast" BO_ 616 0;
BA_ "GenMsgSendType" BO_ 616 0;
BA_ "VFrameFormat" BO_ 616 14;
BA_ "CANFD_BRS" BO_ 616 1;
BA_ "GenMsgCycleTime" BO_ 616 20;
BA_ "GenMsgCycleTimeFast" BO_ 616 0;
BA_ "GenMsgSendType" BO_ 616 0;
BA_ "VFrameFormat" BO_ 616 14;
BA_ "CANFD_BRS" BO_ 616 1;
BA_ "GenMsgCycleTime" BO_ 616 20;
BA_ "GenMsgCycleTimeFast" BO_ 616 0;
BA_ "GenMsgSendType" BO_ 616 0;
BA_ "VFrameFormat" BO_ 616 14;
BA_ "CANFD_BRS" BO_ 616 1;
BA_ "GenMsgCycleTime" BO_ 616 20;
BA_ "GenMsgCycleTimeFast" BO_ 616 0;
BA_ "GenMsgSendType" BO_ 616 0;
BA_ "VFrameFormat" BO_ 616 14;
BA_ "CANFD_BRS" BO_ 616 1;
BA_ "GenMsgCycleTime" BO_ 616 20;
BA_ "GenMsgCycleTimeFast" BO_ 616 0;
BA_ "GenMsgSendType" BO_ 616 0;
BA_ "VFrameFormat" BO_ 616 14;
BA_ "CANFD_BRS" BO_ 616 1;
BA_ "GenMsgCycleTime" BO_ 616 20;
BA_ "GenMsgCycleTimeFast" BO_ 616 0;
BA_ "GenMsgSendType" BO_ 616 0;
BA_ "VFrameFormat" BO_ 616 14;
BA_ "CANFD_BRS" BO_ 616 1;
BA_ "GenMsgCycleTime" BO_ 616 20;
BA_ "GenMsgCycleTimeFast" BO_ 616 0;
BA_ "GenMsgSendType" BO_ 616 0;
BA_ "VFrameFormat" BO_ 616 14;
BA_ "CANFD_BRS" BO_ 616 1;
BA_ "GenMsgCycleTime" BO_ 616 20;
BA_ "GenMsgCycleTimeFast" BO_ 616 0;
BA_ "GenMsgSendType" BO_ 616 0;
BA_ "VFrameFormat" BO_ 616 14;
BA_ "CANFD_BRS" BO_ 616 1;
BA_ "GenMsgCycleTime" BO_ 616 20;
BA_ "GenMsgCycleTimeFast" BO_ 616 0;
BA_ "GenMsgSendType" BO_ 616 0;
BA_ "VFrameFormat" BO_ 616 14;
BA_ "CANFD_BRS" BO_ 616 1;
BA_ "GenMsgCycleTime" BO_ 616 20;
BA_ "GenMsgCycleTimeFast" BO_ 616 0;
BA_ "GenMsgSendType" BO_ 616 0;
BA_ "VFrameFormat" BO_ 616 14;
BA_ "CANFD_BRS" BO_ 616 1;
BA_ "GenMsgCycleTime" BO_ 616 20;
BA_ "GenMsgCycleTimeFast" BO_ 616 0;
BA_ "GenMsgSendType" BO_ 616 0;
BA_ "VFrameFormat" BO_ 616 14;
BA_ "CANFD_BRS" BO_ 616 1;
BA_ "GenMsgCycleTime" BO_ 616 20;
BA_ "GenMsgCycleTimeFast" BO_ 616 0;
BA_ "GenMsgSendType" BO_ 616 0;
BA_ "VFrameFormat" BO_ 616 14;
BA_ "CANFD_BRS" BO_ 616 1;
BA_ "GenMsgCycleTime" BO_ 616 20;
BA_ "GenMsgCycleTimeFast" BO_ 616 0;
BA_ "GenMsgSendType" BO_ 616 0;
BA_ "VFrameFormat" BO_ 616 14;
BA_ "CANFD_BRS" BO_ 616 1;
BA_ "GenMsgCycleTime" BO_ 616 20;
BA_ "GenMsgCycleTimeFast" BO_ 616 0;
BA_ "GenMsgSendType" BO_ 616 0;
BA_ "VFrameFormat" BO_ 616 14;
BA_ "CANFD_BRS" BO_ 616 1;
BA_ "GenMsgCycleTime" BO_ 616 20;
BA_ "GenMsgCycleTimeFast" BO_ 616 0;
BA_ "GenMsgSendType" BO_ 616 0;
BA_ "VFrameFormat" BO_ 616 14;
BA_ "CANFD_BRS" BO_ 616 1;
BA_ "GenMsgCycleTime" BO_ 616 20;
BA_ "GenMsgCycleTimeFast" BO_ 616 0;
BA_ "GenMsgSendType" BO_ 616 0;
BA_ "VFrameFormat" BO_ 616 14;
BA_ "CANFD_BRS" BO_ 616 1;
BA_ "GenMsgCycleTime" BO_ 432 10;
BA_ "GenMsgCycleTimeFast" BO_ 432 0;
BA_ "GenMsgSendType" BO_ 432 0;
BA_ "VFrameFormat" BO_ 432 14;
BA_ "CANFD_BRS" BO_ 432 1;
BA_ "GenMsgCycleTime" BO_ 432 10;
BA_ "GenMsgCycleTimeFast" BO_ 432 0;
BA_ "GenMsgSendType" BO_ 432 0;
BA_ "VFrameFormat" BO_ 432 14;
BA_ "CANFD_BRS" BO_ 432 1;
BA_ "GenMsgCycleTime" BO_ 432 10;
BA_ "GenMsgCycleTimeFast" BO_ 432 0;
BA_ "GenMsgSendType" BO_ 432 0;
BA_ "VFrameFormat" BO_ 432 14;
BA_ "CANFD_BRS" BO_ 432 1;
BA_ "GenMsgCycleTime" BO_ 432 10;
BA_ "GenMsgCycleTimeFast" BO_ 432 0;
BA_ "GenMsgSendType" BO_ 432 0;
BA_ "VFrameFormat" BO_ 432 14;
BA_ "CANFD_BRS" BO_ 432 1;
BA_ "GenMsgCycleTime" BO_ 432 10;
BA_ "GenMsgCycleTimeFast" BO_ 432 0;
BA_ "GenMsgSendType" BO_ 432 0;
BA_ "VFrameFormat" BO_ 432 14;
BA_ "CANFD_BRS" BO_ 432 1;
BA_ "GenMsgCycleTime" BO_ 432 10;
BA_ "GenMsgCycleTimeFast" BO_ 432 0;
BA_ "GenMsgSendType" BO_ 432 0;
BA_ "VFrameFormat" BO_ 432 14;
BA_ "CANFD_BRS" BO_ 432 1;
BA_ "GenMsgCycleTime" BO_ 432 10;
BA_ "GenMsgCycleTimeFast" BO_ 432 0;
BA_ "GenMsgSendType" BO_ 432 0;
BA_ "VFrameFormat" BO_ 432 14;
BA_ "CANFD_BRS" BO_ 432 1;
BA_ "GenMsgCycleTime" BO_ 432 10;
BA_ "GenMsgCycleTimeFast" BO_ 432 0;
BA_ "GenMsgSendType" BO_ 432 0;
BA_ "VFrameFormat" BO_ 432 14;
BA_ "CANFD_BRS" BO_ 432 1;
BA_ "GenMsgCycleTime" BO_ 432 10;
BA_ "GenMsgCycleTimeFast" BO_ 432 0;
BA_ "GenMsgSendType" BO_ 432 0;
BA_ "VFrameFormat" BO_ 432 14;
BA_ "CANFD_BRS" BO_ 432 1;
BA_ "GenMsgCycleTime" BO_ 432 10;
BA_ "GenMsgCycleTimeFast" BO_ 432 0;
BA_ "GenMsgSendType" BO_ 432 0;
BA_ "VFrameFormat" BO_ 432 14;
BA_ "CANFD_BRS" BO_ 432 1;
BA_ "GenMsgCycleTime" BO_ 432 10;
BA_ "GenMsgCycleTimeFast" BO_ 432 0;
BA_ "GenMsgSendType" BO_ 432 0;
BA_ "VFrameFormat" BO_ 432 14;
BA_ "CANFD_BRS" BO_ 432 1;
BA_ "GenMsgCycleTime" BO_ 432 10;
BA_ "GenMsgCycleTimeFast" BO_ 432 0;
BA_ "GenMsgSendType" BO_ 432 0;
BA_ "VFrameFormat" BO_ 432 14;
BA_ "CANFD_BRS" BO_ 432 1;
BA_ "GenMsgCycleTime" BO_ 432 10;
BA_ "GenMsgCycleTimeFast" BO_ 432 0;
BA_ "GenMsgSendType" BO_ 432 0;
BA_ "VFrameFormat" BO_ 432 14;
BA_ "CANFD_BRS" BO_ 432 1;
BA_ "GenMsgCycleTime" BO_ 432 10;
BA_ "GenMsgCycleTimeFast" BO_ 432 0;
BA_ "GenMsgSendType" BO_ 432 0;
BA_ "VFrameFormat" BO_ 432 14;
BA_ "CANFD_BRS" BO_ 432 1;
BA_ "GenMsgCycleTime" BO_ 432 10;
BA_ "GenMsgCycleTimeFast" BO_ 432 0;
BA_ "GenMsgSendType" BO_ 432 0;
BA_ "VFrameFormat" BO_ 432 14;
BA_ "CANFD_BRS" BO_ 432 1;
BA_ "GenMsgCycleTime" BO_ 432 10;
BA_ "GenMsgCycleTimeFast" BO_ 432 0;
BA_ "GenMsgSendType" BO_ 432 0;
BA_ "VFrameFormat" BO_ 432 14;
BA_ "CANFD_BRS" BO_ 432 1;
BA_ "GenMsgCycleTime" BO_ 432 10;
BA_ "GenMsgCycleTimeFast" BO_ 432 0;
BA_ "GenMsgSendType" BO_ 432 0;
BA_ "VFrameFormat" BO_ 432 14;
BA_ "CANFD_BRS" BO_ 432 1;
BA_ "GenMsgCycleTime" BO_ 432 10;
BA_ "GenMsgCycleTimeFast" BO_ 432 0;
BA_ "GenMsgSendType" BO_ 432 0;
BA_ "VFrameFormat" BO_ 432 14;
BA_ "CANFD_BRS" BO_ 432 1;
BA_ "GenMsgCycleTime" BO_ 432 10;
BA_ "GenMsgCycleTimeFast" BO_ 432 0;
BA_ "GenMsgSendType" BO_ 432 0;
BA_ "VFrameFormat" BO_ 432 14;
BA_ "CANFD_BRS" BO_ 432 1;
BA_ "GenMsgCycleTime" BO_ 1359 200;
BA_ "GenMsgCycleTimeFast" BO_ 1359 0;
BA_ "GenMsgSendType" BO_ 1359 0;
BA_ "VFrameFormat" BO_ 1359 0;
BA_ "CANFD_BRS" BO_ 1359 1;
BA_ "GenMsgCycleTime" BO_ 1359 200;
BA_ "GenMsgCycleTimeFast" BO_ 1359 0;
BA_ "GenMsgSendType" BO_ 1359 0;
BA_ "VFrameFormat" BO_ 1359 0;
BA_ "CANFD_BRS" BO_ 1359 1;
BA_ "GenMsgCycleTime" BO_ 1359 200;
BA_ "GenMsgCycleTimeFast" BO_ 1359 0;
BA_ "GenMsgSendType" BO_ 1359 0;
BA_ "VFrameFormat" BO_ 1359 0;
BA_ "CANFD_BRS" BO_ 1359 1;
BA_ "GenMsgCycleTime" BO_ 1359 200;
BA_ "GenMsgCycleTimeFast" BO_ 1359 0;
BA_ "GenMsgSendType" BO_ 1359 0;
BA_ "VFrameFormat" BO_ 1359 0;
BA_ "CANFD_BRS" BO_ 1359 1;
BA_ "GenMsgCycleTime" BO_ 1359 200;
BA_ "GenMsgCycleTimeFast" BO_ 1359 0;
BA_ "GenMsgSendType" BO_ 1359 0;
BA_ "VFrameFormat" BO_ 1359 0;
BA_ "CANFD_BRS" BO_ 1359 1;
BA_ "GenMsgCycleTime" BO_ 1359 200;
BA_ "GenMsgCycleTimeFast" BO_ 1359 0;
BA_ "GenMsgSendType" BO_ 1359 0;
BA_ "VFrameFormat" BO_ 1359 0;
BA_ "CANFD_BRS" BO_ 1359 1;
BA_ "GenMsgCycleTime" BO_ 359 10;
BA_ "GenMsgCycleTimeFast" BO_ 359 0;
BA_ "GenMsgSendType" BO_ 359 0;
BA_ "VFrameFormat" BO_ 359 14;
BA_ "CANFD_BRS" BO_ 359 1;
BA_ "GenMsgCycleTime" BO_ 359 10;
BA_ "GenMsgCycleTimeFast" BO_ 359 0;
BA_ "GenMsgSendType" BO_ 359 0;
BA_ "VFrameFormat" BO_ 359 14;
BA_ "CANFD_BRS" BO_ 359 1;
BA_ "GenMsgCycleTime" BO_ 359 10;
BA_ "GenMsgCycleTimeFast" BO_ 359 0;
BA_ "GenMsgSendType" BO_ 359 0;
BA_ "VFrameFormat" BO_ 359 14;
BA_ "CANFD_BRS" BO_ 359 1;
BA_ "GenMsgCycleTime" BO_ 359 10;
BA_ "GenMsgCycleTimeFast" BO_ 359 0;
BA_ "GenMsgSendType" BO_ 359 0;
BA_ "VFrameFormat" BO_ 359 14;
BA_ "CANFD_BRS" BO_ 359 1;
BA_ "GenMsgCycleTime" BO_ 359 10;
BA_ "GenMsgCycleTimeFast" BO_ 359 0;
BA_ "GenMsgSendType" BO_ 359 0;
BA_ "VFrameFormat" BO_ 359 14;
BA_ "CANFD_BRS" BO_ 359 1;
BA_ "GenMsgCycleTime" BO_ 359 10;
BA_ "GenMsgCycleTimeFast" BO_ 359 0;
BA_ "GenMsgSendType" BO_ 359 0;
BA_ "VFrameFormat" BO_ 359 14;
BA_ "CANFD_BRS" BO_ 359 1;
BA_ "GenMsgCycleTime" BO_ 359 10;
BA_ "GenMsgCycleTimeFast" BO_ 359 0;
BA_ "GenMsgSendType" BO_ 359 0;
BA_ "VFrameFormat" BO_ 359 14;
BA_ "CANFD_BRS" BO_ 359 1;
BA_ "GenMsgCycleTime" BO_ 359 10;
BA_ "GenMsgCycleTimeFast" BO_ 359 0;
BA_ "GenMsgSendType" BO_ 359 0;
BA_ "VFrameFormat" BO_ 359 14;
BA_ "CANFD_BRS" BO_ 359 1;
BA_ "GenMsgCycleTime" BO_ 359 10;
BA_ "GenMsgCycleTimeFast" BO_ 359 0;
BA_ "GenMsgSendType" BO_ 359 0;
BA_ "VFrameFormat" BO_ 359 14;
BA_ "CANFD_BRS" BO_ 359 1;
BA_ "GenMsgCycleTime" BO_ 359 10;
BA_ "GenMsgCycleTimeFast" BO_ 359 0;
BA_ "GenMsgSendType" BO_ 359 0;
BA_ "VFrameFormat" BO_ 359 14;
BA_ "CANFD_BRS" BO_ 359 1;
BA_ "GenMsgCycleTime" BO_ 359 10;
BA_ "GenMsgCycleTimeFast" BO_ 359 0;
BA_ "GenMsgSendType" BO_ 359 0;
BA_ "VFrameFormat" BO_ 359 14;
BA_ "CANFD_BRS" BO_ 359 1;
BA_ "GenMsgCycleTime" BO_ 359 10;
BA_ "GenMsgCycleTimeFast" BO_ 359 0;
BA_ "GenMsgSendType" BO_ 359 0;
BA_ "VFrameFormat" BO_ 359 14;
BA_ "CANFD_BRS" BO_ 359 1;
BA_ "GenMsgCycleTime" BO_ 359 10;
BA_ "GenMsgCycleTimeFast" BO_ 359 0;
BA_ "GenMsgSendType" BO_ 359 0;
BA_ "VFrameFormat" BO_ 359 14;
BA_ "CANFD_BRS" BO_ 359 1;
BA_ "GenMsgCycleTime" BO_ 359 10;
BA_ "GenMsgCycleTimeFast" BO_ 359 0;
BA_ "GenMsgSendType" BO_ 359 0;
BA_ "VFrameFormat" BO_ 359 14;
BA_ "CANFD_BRS" BO_ 359 1;
BA_ "GenMsgCycleTime" BO_ 359 10;
BA_ "GenMsgCycleTimeFast" BO_ 359 0;
BA_ "GenMsgSendType" BO_ 359 0;
BA_ "VFrameFormat" BO_ 359 14;
BA_ "CANFD_BRS" BO_ 359 1;
BA_ "GenMsgCycleTime" BO_ 359 10;
BA_ "GenMsgCycleTimeFast" BO_ 359 0;
BA_ "GenMsgSendType" BO_ 359 0;
BA_ "VFrameFormat" BO_ 359 14;
BA_ "CANFD_BRS" BO_ 359 1;
BA_ "GenMsgCycleTime" BO_ 359 10;
BA_ "GenMsgCycleTimeFast" BO_ 359 0;
BA_ "GenMsgSendType" BO_ 359 0;
BA_ "VFrameFormat" BO_ 359 14;
BA_ "CANFD_BRS" BO_ 359 1;
BA_ "GenMsgCycleTime" BO_ 359 10;
BA_ "GenMsgCycleTimeFast" BO_ 359 0;
BA_ "GenMsgSendType" BO_ 359 0;
BA_ "VFrameFormat" BO_ 359 14;
BA_ "CANFD_BRS" BO_ 359 1;
BA_ "GenMsgCycleTime" BO_ 359 10;
BA_ "GenMsgCycleTimeFast" BO_ 359 0;
BA_ "GenMsgSendType" BO_ 359 0;
BA_ "VFrameFormat" BO_ 359 14;
BA_ "CANFD_BRS" BO_ 359 1;
BA_ "GenMsgCycleTime" BO_ 359 10;
BA_ "GenMsgCycleTimeFast" BO_ 359 0;
BA_ "GenMsgSendType" BO_ 359 0;
BA_ "VFrameFormat" BO_ 359 14;
BA_ "CANFD_BRS" BO_ 359 1;
BA_ "GenMsgCycleTime" BO_ 359 10;
BA_ "GenMsgCycleTimeFast" BO_ 359 0;
BA_ "GenMsgSendType" BO_ 359 0;
BA_ "VFrameFormat" BO_ 359 14;
BA_ "CANFD_BRS" BO_ 359 1;
BA_ "GenMsgCycleTime" BO_ 359 10;
BA_ "GenMsgCycleTimeFast" BO_ 359 0;
BA_ "GenMsgSendType" BO_ 359 0;
BA_ "VFrameFormat" BO_ 359 14;
BA_ "CANFD_BRS" BO_ 359 1;
BA_ "GenMsgCycleTime" BO_ 359 10;
BA_ "GenMsgCycleTimeFast" BO_ 359 0;
BA_ "GenMsgSendType" BO_ 359 0;
BA_ "VFrameFormat" BO_ 359 14;
BA_ "CANFD_BRS" BO_ 359 1;
BA_ "GenMsgCycleTime" BO_ 359 10;
BA_ "GenMsgCycleTimeFast" BO_ 359 0;
BA_ "GenMsgSendType" BO_ 359 0;
BA_ "VFrameFormat" BO_ 359 14;
BA_ "CANFD_BRS" BO_ 359 1;
BA_ "GenMsgCycleTime" BO_ 359 10;
BA_ "GenMsgCycleTimeFast" BO_ 359 0;
BA_ "GenMsgSendType" BO_ 359 0;
BA_ "VFrameFormat" BO_ 359 14;
BA_ "CANFD_BRS" BO_ 359 1;
BA_ "GenMsgCycleTime" BO_ 359 10;
BA_ "GenMsgCycleTimeFast" BO_ 359 0;
BA_ "GenMsgSendType" BO_ 359 0;
BA_ "VFrameFormat" BO_ 359 14;
BA_ "CANFD_BRS" BO_ 359 1;
BA_ "GenMsgCycleTime" BO_ 359 10;
BA_ "GenMsgCycleTimeFast" BO_ 359 0;
BA_ "GenMsgSendType" BO_ 359 0;
BA_ "VFrameFormat" BO_ 359 14;
BA_ "CANFD_BRS" BO_ 359 1;
BA_ "GenMsgCycleTime" BO_ 359 10;
BA_ "GenMsgCycleTimeFast" BO_ 359 0;
BA_ "GenMsgSendType" BO_ 359 0;
BA_ "VFrameFormat" BO_ 359 14;
BA_ "CANFD_BRS" BO_ 359 1;
BA_ "GenMsgCycleTime" BO_ 359 10;
BA_ "GenMsgCycleTimeFast" BO_ 359 0;
BA_ "GenMsgSendType" BO_ 359 0;
BA_ "VFrameFormat" BO_ 359 14;
BA_ "CANFD_BRS" BO_ 359 1;
BA_ "GenMsgCycleTime" BO_ 359 10;
BA_ "GenMsgCycleTimeFast" BO_ 359 0;
BA_ "GenMsgSendType" BO_ 359 0;
BA_ "VFrameFormat" BO_ 359 14;
BA_ "CANFD_BRS" BO_ 359 1;
BA_ "GenMsgCycleTime" BO_ 359 10;
BA_ "GenMsgCycleTimeFast" BO_ 359 0;
BA_ "GenMsgSendType" BO_ 359 0;
BA_ "VFrameFormat" BO_ 359 14;
BA_ "CANFD_BRS" BO_ 359 1;
BA_ "GenMsgCycleTime" BO_ 359 10;
BA_ "GenMsgCycleTimeFast" BO_ 359 0;
BA_ "GenMsgSendType" BO_ 359 0;
BA_ "VFrameFormat" BO_ 359 14;
BA_ "CANFD_BRS" BO_ 359 1;
BA_ "GenMsgCycleTime" BO_ 359 10;
BA_ "GenMsgCycleTimeFast" BO_ 359 0;
BA_ "GenMsgSendType" BO_ 359 0;
BA_ "VFrameFormat" BO_ 359 14;
BA_ "CANFD_BRS" BO_ 359 1;
BA_ "GenMsgCycleTime" BO_ 359 10;
BA_ "GenMsgCycleTimeFast" BO_ 359 0;
BA_ "GenMsgSendType" BO_ 359 0;
BA_ "VFrameFormat" BO_ 359 14;
BA_ "CANFD_BRS" BO_ 359 1;
BA_ "GenMsgCycleTime" BO_ 359 10;
BA_ "GenMsgCycleTimeFast" BO_ 359 0;
BA_ "GenMsgSendType" BO_ 359 0;
BA_ "VFrameFormat" BO_ 359 14;
BA_ "CANFD_BRS" BO_ 359 1;
BA_ "GenMsgCycleTime" BO_ 359 10;
BA_ "GenMsgCycleTimeFast" BO_ 359 0;
BA_ "GenMsgSendType" BO_ 359 0;
BA_ "VFrameFormat" BO_ 359 14;
BA_ "CANFD_BRS" BO_ 359 1;
BA_ "GenMsgCycleTime" BO_ 359 10;
BA_ "GenMsgCycleTimeFast" BO_ 359 0;
BA_ "GenMsgSendType" BO_ 359 0;
BA_ "VFrameFormat" BO_ 359 14;
BA_ "CANFD_BRS" BO_ 359 1;
BA_ "GenMsgCycleTime" BO_ 359 10;
BA_ "GenMsgCycleTimeFast" BO_ 359 0;
BA_ "GenMsgSendType" BO_ 359 0;
BA_ "VFrameFormat" BO_ 359 14;
BA_ "CANFD_BRS" BO_ 359 1;
BA_ "GenMsgCycleTime" BO_ 359 10;
BA_ "GenMsgCycleTimeFast" BO_ 359 0;
BA_ "GenMsgSendType" BO_ 359 0;
BA_ "VFrameFormat" BO_ 359 14;
BA_ "CANFD_BRS" BO_ 359 1;
BA_ "GenMsgCycleTime" BO_ 359 10;
BA_ "GenMsgCycleTimeFast" BO_ 359 0;
BA_ "GenMsgSendType" BO_ 359 0;
BA_ "VFrameFormat" BO_ 359 14;
BA_ "CANFD_BRS" BO_ 359 1;
BA_ "GenMsgCycleTime" BO_ 359 10;
BA_ "GenMsgCycleTimeFast" BO_ 359 0;
BA_ "GenMsgSendType" BO_ 359 0;
BA_ "VFrameFormat" BO_ 359 14;
BA_ "CANFD_BRS" BO_ 359 1;
BA_ "GenMsgCycleTime" BO_ 359 10;
BA_ "GenMsgCycleTimeFast" BO_ 359 0;
BA_ "GenMsgSendType" BO_ 359 0;
BA_ "VFrameFormat" BO_ 359 14;
BA_ "CANFD_BRS" BO_ 359 1;
BA_ "GenMsgCycleTime" BO_ 359 10;
BA_ "GenMsgCycleTimeFast" BO_ 359 0;
BA_ "GenMsgSendType" BO_ 359 0;
BA_ "VFrameFormat" BO_ 359 14;
BA_ "CANFD_BRS" BO_ 359 1;
BA_ "GenMsgCycleTime" BO_ 359 10;
BA_ "GenMsgCycleTimeFast" BO_ 359 0;
BA_ "GenMsgSendType" BO_ 359 0;
BA_ "VFrameFormat" BO_ 359 14;
BA_ "CANFD_BRS" BO_ 359 1;
BA_ "GenMsgCycleTime" BO_ 359 10;
BA_ "GenMsgCycleTimeFast" BO_ 359 0;
BA_ "GenMsgSendType" BO_ 359 0;
BA_ "VFrameFormat" BO_ 359 14;
BA_ "CANFD_BRS" BO_ 359 1;
BA_ "GenMsgCycleTime" BO_ 359 10;
BA_ "GenMsgCycleTimeFast" BO_ 359 0;
BA_ "GenMsgSendType" BO_ 359 0;
BA_ "VFrameFormat" BO_ 359 14;
BA_ "CANFD_BRS" BO_ 359 1;
BA_ "GenMsgCycleTime" BO_ 359 10;
BA_ "GenMsgCycleTimeFast" BO_ 359 0;
BA_ "GenMsgSendType" BO_ 359 0;
BA_ "VFrameFormat" BO_ 359 14;
BA_ "CANFD_BRS" BO_ 359 1;
BA_ "GenMsgCycleTime" BO_ 359 10;
BA_ "GenMsgCycleTimeFast" BO_ 359 0;
BA_ "GenMsgSendType" BO_ 359 0;
BA_ "VFrameFormat" BO_ 359 14;
BA_ "CANFD_BRS" BO_ 359 1;
BA_ "GenMsgCycleTime" BO_ 359 10;
BA_ "GenMsgCycleTimeFast" BO_ 359 0;
BA_ "GenMsgSendType" BO_ 359 0;
BA_ "VFrameFormat" BO_ 359 14;
BA_ "CANFD_BRS" BO_ 359 1;
BA_ "GenMsgCycleTime" BO_ 359 10;
BA_ "GenMsgCycleTimeFast" BO_ 359 0;
BA_ "GenMsgSendType" BO_ 359 0;
BA_ "VFrameFormat" BO_ 359 14;
BA_ "CANFD_BRS" BO_ 359 1;
BA_ "GenMsgCycleTime" BO_ 359 10;
BA_ "GenMsgCycleTimeFast" BO_ 359 0;
BA_ "GenMsgSendType" BO_ 359 0;
BA_ "VFrameFormat" BO_ 359 14;
BA_ "CANFD_BRS" BO_ 359 1;
BA_ "GenMsgCycleTime" BO_ 359 10;
BA_ "GenMsgCycleTimeFast" BO_ 359 0;
BA_ "GenMsgSendType" BO_ 359 0;
BA_ "VFrameFormat" BO_ 359 14;
BA_ "CANFD_BRS" BO_ 359 1;
BA_ "GenMsgCycleTime" BO_ 359 10;
BA_ "GenMsgCycleTimeFast" BO_ 359 0;
BA_ "GenMsgSendType" BO_ 359 0;
BA_ "VFrameFormat" BO_ 359 14;
BA_ "CANFD_BRS" BO_ 359 1;
BA_ "GenMsgCycleTime" BO_ 359 10;
BA_ "GenMsgCycleTimeFast" BO_ 359 0;
BA_ "GenMsgSendType" BO_ 359 0;
BA_ "VFrameFormat" BO_ 359 14;
BA_ "CANFD_BRS" BO_ 359 1;
BA_ "GenMsgCycleTime" BO_ 359 10;
BA_ "GenMsgCycleTimeFast" BO_ 359 0;
BA_ "GenMsgSendType" BO_ 359 0;
BA_ "VFrameFormat" BO_ 359 14;
BA_ "CANFD_BRS" BO_ 359 1;
BA_ "GenMsgCycleTime" BO_ 359 10;
BA_ "GenMsgCycleTimeFast" BO_ 359 0;
BA_ "GenMsgSendType" BO_ 359 0;
BA_ "VFrameFormat" BO_ 359 14;
BA_ "CANFD_BRS" BO_ 359 1;
BA_ "GenMsgCycleTime" BO_ 359 10;
BA_ "GenMsgCycleTimeFast" BO_ 359 0;
BA_ "GenMsgSendType" BO_ 359 0;
BA_ "VFrameFormat" BO_ 359 14;
BA_ "CANFD_BRS" BO_ 359 1;
BA_ "GenMsgCycleTime" BO_ 359 10;
BA_ "GenMsgCycleTimeFast" BO_ 359 0;
BA_ "GenMsgSendType" BO_ 359 0;
BA_ "VFrameFormat" BO_ 359 14;
BA_ "CANFD_BRS" BO_ 359 1;
BA_ "GenMsgCycleTime" BO_ 359 10;
BA_ "GenMsgCycleTimeFast" BO_ 359 0;
BA_ "GenMsgSendType" BO_ 359 0;
BA_ "VFrameFormat" BO_ 359 14;
BA_ "CANFD_BRS" BO_ 359 1;
BA_ "GenMsgCycleTime" BO_ 359 10;
BA_ "GenMsgCycleTimeFast" BO_ 359 0;
BA_ "GenMsgSendType" BO_ 359 0;
BA_ "VFrameFormat" BO_ 359 14;
BA_ "CANFD_BRS" BO_ 359 1;

BA_ "EventCommandSignal" SG_ 2015 Fun_Diag_Request 0;
BA_ "GatewayedSignals" SG_ 2015 Fun_Diag_Request 0;
BA_ "GenSigInactiveValue" SG_ 2015 Fun_Diag_Request 0;
BA_ "GenSigInvalidValue" SG_ 2015 Fun_Diag_Request 0;
BA_ "GenSigSendType" SG_ 2015 Fun_Diag_Request 1;
BA_ "GenSigStartValue" SG_ 2015 Fun_Diag_Request 0;
BA_ "GenSigTimeoutValue" SG_ 2015 Fun_Diag_Request 0;
BA_ "Remark" SG_ 2015 Fun_Diag_Request "";
BA_ "EventCommandSignal" SG_ 368 DCU_1_CRC 0;
BA_ "GatewayedSignals" SG_ 368 DCU_1_CRC 0;
BA_ "GenSigInactiveValue" SG_ 368 DCU_1_CRC 0;
BA_ "GenSigInvalidValue" SG_ 368 DCU_1_CRC 0;
BA_ "GenSigSendType" SG_ 368 DCU_1_CRC 1;
BA_ "GenSigStartValue" SG_ 368 DCU_1_CRC 0;
BA_ "GenSigTimeoutValue" SG_ 368 DCU_1_CRC 0;
BA_ "Remark" SG_ 368 DCU_1_CRC "";
BA_ "EventCommandSignal" SG_ 368 DCU_1_Counter 0;
BA_ "GatewayedSignals" SG_ 368 DCU_1_Counter 0;
BA_ "GenSigInactiveValue" SG_ 368 DCU_1_Counter 0;
BA_ "GenSigInvalidValue" SG_ 368 DCU_1_Counter 0;
BA_ "GenSigSendType" SG_ 368 DCU_1_Counter 1;
BA_ "GenSigStartValue" SG_ 368 DCU_1_Counter 0;
BA_ "GenSigTimeoutValue" SG_ 368 DCU_1_Counter 0;
BA_ "Remark" SG_ 368 DCU_1_Counter "";
BA_ "EventCommandSignal" SG_ 368 DCU_RotSpdAct 0;
BA_ "GatewayedSignals" SG_ 368 DCU_RotSpdAct 0;
BA_ "GenSigInactiveValue" SG_ 368 DCU_RotSpdAct 0;
BA_ "GenSigInvalidValue" SG_ 368 DCU_RotSpdAct 65535;
BA_ "GenSigSendType" SG_ 368 DCU_RotSpdAct 1;
BA_ "GenSigStartValue" SG_ 368 DCU_RotSpdAct 32767;
BA_ "GenSigTimeoutValue" SG_ 368 DCU_RotSpdAct 0;
BA_ "Remark" SG_ 368 DCU_RotSpdAct "";
BA_ "EventCommandSignal" SG_ 368 DCU_ModeSt 0;
BA_ "GatewayedSignals" SG_ 368 DCU_ModeSt 0;
BA_ "GenSigInactiveValue" SG_ 368 DCU_ModeSt 0;
BA_ "GenSigInvalidValue" SG_ 368 DCU_ModeSt 0;
BA_ "GenSigSendType" SG_ 368 DCU_ModeSt 1;
BA_ "GenSigStartValue" SG_ 368 DCU_ModeSt 1;
BA_ "GenSigTimeoutValue" SG_ 368 DCU_ModeSt 0;
BA_ "Remark" SG_ 368 DCU_ModeSt "";
BA_ "EventCommandSignal" SG_ 368 DCU_ADC_MCUBlkst 0;
BA_ "GatewayedSignals" SG_ 368 DCU_ADC_MCUBlkst 0;
BA_ "GenSigInactiveValue" SG_ 368 DCU_ADC_MCUBlkst 0;
BA_ "GenSigInvalidValue" SG_ 368 DCU_ADC_MCUBlkst 7;
BA_ "GenSigSendType" SG_ 368 DCU_ADC_MCUBlkst 1;
BA_ "GenSigStartValue" SG_ 368 DCU_ADC_MCUBlkst 0;
BA_ "GenSigTimeoutValue" SG_ 368 DCU_ADC_MCUBlkst 0;
BA_ "Remark" SG_ 368 DCU_ADC_MCUBlkst "";
BA_ "EventCommandSignal" SG_ 368 DCU_ADC_SpdSvModAvl 0;
BA_ "GatewayedSignals" SG_ 368 DCU_ADC_SpdSvModAvl 0;
BA_ "GenSigInactiveValue" SG_ 368 DCU_ADC_SpdSvModAvl 0;
BA_ "GenSigInvalidValue" SG_ 368 DCU_ADC_SpdSvModAvl 1;
BA_ "GenSigSendType" SG_ 368 DCU_ADC_SpdSvModAvl 1;
BA_ "GenSigStartValue" SG_ 368 DCU_ADC_SpdSvModAvl 0;
BA_ "GenSigTimeoutValue" SG_ 368 DCU_ADC_SpdSvModAvl 0;
BA_ "Remark" SG_ 368 DCU_ADC_SpdSvModAvl "";
BA_ "EventCommandSignal" SG_ 368 DCU_ADC_MCUStandstill 0;
BA_ "GatewayedSignals" SG_ 368 DCU_ADC_MCUStandstill 0;
BA_ "GenSigInactiveValue" SG_ 368 DCU_ADC_MCUStandstill 0;
BA_ "GenSigInvalidValue" SG_ 368 DCU_ADC_MCUStandstill 1;
BA_ "GenSigSendType" SG_ 368 DCU_ADC_MCUStandstill 1;
BA_ "GenSigStartValue" SG_ 368 DCU_ADC_MCUStandstill 0;
BA_ "GenSigTimeoutValue" SG_ 368 DCU_ADC_MCUStandstill 0;
BA_ "Remark" SG_ 368 DCU_ADC_MCUStandstill "";
BA_ "EventCommandSignal" SG_ 368 DCU_ADC_MCUSpdSVModFit 0;
BA_ "GatewayedSignals" SG_ 368 DCU_ADC_MCUSpdSVModFit 0;
BA_ "GenSigInactiveValue" SG_ 368 DCU_ADC_MCUSpdSVModFit 0;
BA_ "GenSigInvalidValue" SG_ 368 DCU_ADC_MCUSpdSVModFit 7;
BA_ "GenSigSendType" SG_ 368 DCU_ADC_MCUSpdSVModFit 1;
BA_ "GenSigStartValue" SG_ 368 DCU_ADC_MCUSpdSVModFit 0;
BA_ "GenSigTimeoutValue" SG_ 368 DCU_ADC_MCUSpdSVModFit 0;
BA_ "Remark" SG_ 368 DCU_ADC_MCUSpdSVModFit "";
BA_ "EventCommandSignal" SG_ 368 DCU_ADC_MCUVehSldSt 0;
BA_ "GatewayedSignals" SG_ 368 DCU_ADC_MCUVehSldSt 0;
BA_ "GenSigInactiveValue" SG_ 368 DCU_ADC_MCUVehSldSt 0;
BA_ "GenSigInvalidValue" SG_ 368 DCU_ADC_MCUVehSldSt 1;
BA_ "GenSigSendType" SG_ 368 DCU_ADC_MCUVehSldSt 1;
BA_ "GenSigStartValue" SG_ 368 DCU_ADC_MCUVehSldSt 0;
BA_ "GenSigTimeoutValue" SG_ 368 DCU_ADC_MCUVehSldSt 0;
BA_ "Remark" SG_ 368 DCU_ADC_MCUVehSldSt "";
BA_ "EventCommandSignal" SG_ 368 DCU_ADC_MCUReqTq 0;
BA_ "GatewayedSignals" SG_ 368 DCU_ADC_MCUReqTq 0;
BA_ "GenSigInactiveValue" SG_ 368 DCU_ADC_MCUReqTq 0;
BA_ "GenSigInvalidValue" SG_ 368 DCU_ADC_MCUReqTq 2047;
BA_ "GenSigSendType" SG_ 368 DCU_ADC_MCUReqTq 1;
BA_ "GenSigStartValue" SG_ 368 DCU_ADC_MCUReqTq 1023;
BA_ "GenSigTimeoutValue" SG_ 368 DCU_ADC_MCUReqTq 0;
BA_ "Remark" SG_ 368 DCU_ADC_MCUReqTq "";
BA_ "EventCommandSignal" SG_ 368 DCU_TorqAct 0;
BA_ "GatewayedSignals" SG_ 368 DCU_TorqAct 0;
BA_ "GenSigInactiveValue" SG_ 368 DCU_TorqAct 0;
BA_ "GenSigInvalidValue" SG_ 368 DCU_TorqAct 0;
BA_ "GenSigSendType" SG_ 368 DCU_TorqAct 1;
BA_ "GenSigStartValue" SG_ 368 DCU_TorqAct 4095;
BA_ "GenSigTimeoutValue" SG_ 368 DCU_TorqAct 0;
BA_ "Remark" SG_ 368 DCU_TorqAct "";
BA_ "EventCommandSignal" SG_ 369 DCU2_1_CRC 0;
BA_ "GatewayedSignals" SG_ 369 DCU2_1_CRC 0;
BA_ "GenSigInactiveValue" SG_ 369 DCU2_1_CRC 0;
BA_ "GenSigInvalidValue" SG_ 369 DCU2_1_CRC 0;
BA_ "GenSigSendType" SG_ 369 DCU2_1_CRC 1;
BA_ "GenSigStartValue" SG_ 369 DCU2_1_CRC 0;
BA_ "GenSigTimeoutValue" SG_ 369 DCU2_1_CRC 0;
BA_ "Remark" SG_ 369 DCU2_1_CRC "";
BA_ "EventCommandSignal" SG_ 369 DCU2_1_Counter 0;
BA_ "GatewayedSignals" SG_ 369 DCU2_1_Counter 0;
BA_ "GenSigInactiveValue" SG_ 369 DCU2_1_Counter 0;
BA_ "GenSigInvalidValue" SG_ 369 DCU2_1_Counter 0;
BA_ "GenSigSendType" SG_ 369 DCU2_1_Counter 1;
BA_ "GenSigStartValue" SG_ 369 DCU2_1_Counter 0;
BA_ "GenSigTimeoutValue" SG_ 369 DCU2_1_Counter 0;
BA_ "Remark" SG_ 369 DCU2_1_Counter "";
BA_ "EventCommandSignal" SG_ 369 DCU2_RotSpdAct 0;
BA_ "GatewayedSignals" SG_ 369 DCU2_RotSpdAct 0;
BA_ "GenSigInactiveValue" SG_ 369 DCU2_RotSpdAct 0;
BA_ "GenSigInvalidValue" SG_ 369 DCU2_RotSpdAct 65535;
BA_ "GenSigSendType" SG_ 369 DCU2_RotSpdAct 1;
BA_ "GenSigStartValue" SG_ 369 DCU2_RotSpdAct 32767;
BA_ "GenSigTimeoutValue" SG_ 369 DCU2_RotSpdAct 0;
BA_ "Remark" SG_ 369 DCU2_RotSpdAct "";
BA_ "EventCommandSignal" SG_ 369 DCU2_ModeSt_Hyb 0;
BA_ "GatewayedSignals" SG_ 369 DCU2_ModeSt_Hyb 0;
BA_ "GenSigInactiveValue" SG_ 369 DCU2_ModeSt_Hyb 0;
BA_ "GenSigInvalidValue" SG_ 369 DCU2_ModeSt_Hyb 0;
BA_ "GenSigSendType" SG_ 369 DCU2_ModeSt_Hyb 1;
BA_ "GenSigStartValue" SG_ 369 DCU2_ModeSt_Hyb 1;
BA_ "GenSigTimeoutValue" SG_ 369 DCU2_ModeSt_Hyb 0;
BA_ "Remark" SG_ 369 DCU2_ModeSt_Hyb "";
BA_ "EventCommandSignal" SG_ 369 DCU2_ADC_MCUBlkst 0;
BA_ "GatewayedSignals" SG_ 369 DCU2_ADC_MCUBlkst 0;
BA_ "GenSigInactiveValue" SG_ 369 DCU2_ADC_MCUBlkst 0;
BA_ "GenSigInvalidValue" SG_ 369 DCU2_ADC_MCUBlkst 7;
BA_ "GenSigSendType" SG_ 369 DCU2_ADC_MCUBlkst 1;
BA_ "GenSigStartValue" SG_ 369 DCU2_ADC_MCUBlkst 0;
BA_ "GenSigTimeoutValue" SG_ 369 DCU2_ADC_MCUBlkst 0;
BA_ "Remark" SG_ 369 DCU2_ADC_MCUBlkst "";
BA_ "EventCommandSignal" SG_ 369 DCU2_ADC_SpdSvModAvl 0;
BA_ "GatewayedSignals" SG_ 369 DCU2_ADC_SpdSvModAvl 0;
BA_ "GenSigInactiveValue" SG_ 369 DCU2_ADC_SpdSvModAvl 0;
BA_ "GenSigInvalidValue" SG_ 369 DCU2_ADC_SpdSvModAvl 1;
BA_ "GenSigSendType" SG_ 369 DCU2_ADC_SpdSvModAvl 1;
BA_ "GenSigStartValue" SG_ 369 DCU2_ADC_SpdSvModAvl 0;
BA_ "GenSigTimeoutValue" SG_ 369 DCU2_ADC_SpdSvModAvl 0;
BA_ "Remark" SG_ 369 DCU2_ADC_SpdSvModAvl "";
BA_ "EventCommandSignal" SG_ 369 DCU2_ADC_MCUStandstill 0;
BA_ "GatewayedSignals" SG_ 369 DCU2_ADC_MCUStandstill 0;
BA_ "GenSigInactiveValue" SG_ 369 DCU2_ADC_MCUStandstill 0;
BA_ "GenSigInvalidValue" SG_ 369 DCU2_ADC_MCUStandstill 1;
BA_ "GenSigSendType" SG_ 369 DCU2_ADC_MCUStandstill 1;
BA_ "GenSigStartValue" SG_ 369 DCU2_ADC_MCUStandstill 0;
BA_ "GenSigTimeoutValue" SG_ 369 DCU2_ADC_MCUStandstill 0;
BA_ "Remark" SG_ 369 DCU2_ADC_MCUStandstill "";
BA_ "EventCommandSignal" SG_ 369 DCU2_ADC_MCUSpdSVModFit 0;
BA_ "GatewayedSignals" SG_ 369 DCU2_ADC_MCUSpdSVModFit 0;
BA_ "GenSigInactiveValue" SG_ 369 DCU2_ADC_MCUSpdSVModFit 0;
BA_ "GenSigInvalidValue" SG_ 369 DCU2_ADC_MCUSpdSVModFit 7;
BA_ "GenSigSendType" SG_ 369 DCU2_ADC_MCUSpdSVModFit 1;
BA_ "GenSigStartValue" SG_ 369 DCU2_ADC_MCUSpdSVModFit 0;
BA_ "GenSigTimeoutValue" SG_ 369 DCU2_ADC_MCUSpdSVModFit 0;
BA_ "Remark" SG_ 369 DCU2_ADC_MCUSpdSVModFit "";
BA_ "EventCommandSignal" SG_ 369 DCU2_ADC_MCUVehSldSt 0;
BA_ "GatewayedSignals" SG_ 369 DCU2_ADC_MCUVehSldSt 0;
BA_ "GenSigInactiveValue" SG_ 369 DCU2_ADC_MCUVehSldSt 0;
BA_ "GenSigInvalidValue" SG_ 369 DCU2_ADC_MCUVehSldSt 1;
BA_ "GenSigSendType" SG_ 369 DCU2_ADC_MCUVehSldSt 1;
BA_ "GenSigStartValue" SG_ 369 DCU2_ADC_MCUVehSldSt 0;
BA_ "GenSigTimeoutValue" SG_ 369 DCU2_ADC_MCUVehSldSt 0;
BA_ "Remark" SG_ 369 DCU2_ADC_MCUVehSldSt "";
BA_ "EventCommandSignal" SG_ 369 DCU2_ADC_MCUReqTq 0;
BA_ "GatewayedSignals" SG_ 369 DCU2_ADC_MCUReqTq 0;
BA_ "GenSigInactiveValue" SG_ 369 DCU2_ADC_MCUReqTq 0;
BA_ "GenSigInvalidValue" SG_ 369 DCU2_ADC_MCUReqTq 2047;
BA_ "GenSigSendType" SG_ 369 DCU2_ADC_MCUReqTq 1;
BA_ "GenSigStartValue" SG_ 369 DCU2_ADC_MCUReqTq 1023;
BA_ "GenSigTimeoutValue" SG_ 369 DCU2_ADC_MCUReqTq 0;
BA_ "Remark" SG_ 369 DCU2_ADC_MCUReqTq "";
BA_ "EventCommandSignal" SG_ 513 IDUR_RotSpdActL 0;
BA_ "GatewayedSignals" SG_ 513 IDUR_RotSpdActL 0;
BA_ "GenSigInactiveValue" SG_ 513 IDUR_RotSpdActL 0;
BA_ "GenSigInvalidValue" SG_ 513 IDUR_RotSpdActL 65535;
BA_ "GenSigSendType" SG_ 513 IDUR_RotSpdActL 1;
BA_ "GenSigStartValue" SG_ 513 IDUR_RotSpdActL 32767;
BA_ "GenSigTimeoutValue" SG_ 513 IDUR_RotSpdActL 0;
BA_ "Remark" SG_ 513 IDUR_RotSpdActL "";
BA_ "EventCommandSignal" SG_ 513 IDUR_RotSpdActR 0;
BA_ "GatewayedSignals" SG_ 513 IDUR_RotSpdActR 0;
BA_ "GenSigInactiveValue" SG_ 513 IDUR_RotSpdActR 0;
BA_ "GenSigInvalidValue" SG_ 513 IDUR_RotSpdActR 65535;
BA_ "GenSigSendType" SG_ 513 IDUR_RotSpdActR 1;
BA_ "GenSigStartValue" SG_ 513 IDUR_RotSpdActR 32767;
BA_ "GenSigTimeoutValue" SG_ 513 IDUR_RotSpdActR 0;
BA_ "Remark" SG_ 513 IDUR_RotSpdActR "";
BA_ "EventCommandSignal" SG_ 860 VCU_7_CRC 0;
BA_ "GatewayedSignals" SG_ 860 VCU_7_CRC 0;
BA_ "GenSigInactiveValue" SG_ 860 VCU_7_CRC 0;
BA_ "GenSigInvalidValue" SG_ 860 VCU_7_CRC 0;
BA_ "GenSigSendType" SG_ 860 VCU_7_CRC 1;
BA_ "GenSigStartValue" SG_ 860 VCU_7_CRC 0;
BA_ "GenSigTimeoutValue" SG_ 860 VCU_7_CRC 0;
BA_ "Remark" SG_ 860 VCU_7_CRC "";
BA_ "EventCommandSignal" SG_ 860 VCU_7_Counter 0;
BA_ "GatewayedSignals" SG_ 860 VCU_7_Counter 0;
BA_ "GenSigInactiveValue" SG_ 860 VCU_7_Counter 0;
BA_ "GenSigInvalidValue" SG_ 860 VCU_7_Counter 0;
BA_ "GenSigSendType" SG_ 860 VCU_7_Counter 1;
BA_ "GenSigStartValue" SG_ 860 VCU_7_Counter 0;
BA_ "GenSigTimeoutValue" SG_ 860 VCU_7_Counter 0;
BA_ "Remark" SG_ 860 VCU_7_Counter "";
BA_ "EventCommandSignal" SG_ 860 VCU_RoadMod 0;
BA_ "GatewayedSignals" SG_ 860 VCU_RoadMod 0;
BA_ "GenSigInactiveValue" SG_ 860 VCU_RoadMod 0;
BA_ "GenSigInvalidValue" SG_ 860 VCU_RoadMod 0;
BA_ "GenSigSendType" SG_ 860 VCU_RoadMod 1;
BA_ "GenSigStartValue" SG_ 860 VCU_RoadMod 0;
BA_ "GenSigTimeoutValue" SG_ 860 VCU_RoadMod 0;
BA_ "Remark" SG_ 860 VCU_RoadMod "";
BA_ "EventCommandSignal" SG_ 860 VCU_GearLvl 0;
BA_ "GatewayedSignals" SG_ 860 VCU_GearLvl 0;
BA_ "GenSigInactiveValue" SG_ 860 VCU_GearLvl 0;
BA_ "GenSigInvalidValue" SG_ 860 VCU_GearLvl 0;
BA_ "GenSigSendType" SG_ 860 VCU_GearLvl 1;
BA_ "GenSigStartValue" SG_ 860 VCU_GearLvl 0;
BA_ "GenSigTimeoutValue" SG_ 860 VCU_GearLvl 0;
BA_ "Remark" SG_ 860 VCU_GearLvl "";
BA_ "EventCommandSignal" SG_ 860 VCU_VehDrvMod 0;
BA_ "GatewayedSignals" SG_ 860 VCU_VehDrvMod 0;
BA_ "GenSigInactiveValue" SG_ 860 VCU_VehDrvMod 0;
BA_ "GenSigInvalidValue" SG_ 860 VCU_VehDrvMod 0;
BA_ "GenSigSendType" SG_ 860 VCU_VehDrvMod 1;
BA_ "GenSigStartValue" SG_ 860 VCU_VehDrvMod 0;
BA_ "GenSigTimeoutValue" SG_ 860 VCU_VehDrvMod 0;
BA_ "Remark" SG_ 860 VCU_VehDrvMod "";
BA_ "EventCommandSignal" SG_ 860 VCU_VehRdySt 0;
BA_ "GatewayedSignals" SG_ 860 VCU_VehRdySt 0;
BA_ "GenSigInactiveValue" SG_ 860 VCU_VehRdySt 0;
BA_ "GenSigInvalidValue" SG_ 860 VCU_VehRdySt 0;
BA_ "GenSigSendType" SG_ 860 VCU_VehRdySt 1;
BA_ "GenSigStartValue" SG_ 860 VCU_VehRdySt 0;
BA_ "GenSigTimeoutValue" SG_ 860 VCU_VehRdySt 0;
BA_ "Remark" SG_ 860 VCU_VehRdySt "";
BA_ "EventCommandSignal" SG_ 860 VCU_ChgActiveSt_toADC 0;
BA_ "GatewayedSignals" SG_ 860 VCU_ChgActiveSt_toADC 0;
BA_ "GenSigInactiveValue" SG_ 860 VCU_ChgActiveSt_toADC 0;
BA_ "GenSigInvalidValue" SG_ 860 VCU_ChgActiveSt_toADC 0;
BA_ "GenSigSendType" SG_ 860 VCU_ChgActiveSt_toADC 1;
BA_ "GenSigStartValue" SG_ 860 VCU_ChgActiveSt_toADC 0;
BA_ "GenSigTimeoutValue" SG_ 860 VCU_ChgActiveSt_toADC 0;
BA_ "Remark" SG_ 860 VCU_ChgActiveSt_toADC "";
BA_ "EventCommandSignal" SG_ 860 VCU_PlgConnSt 0;
BA_ "GatewayedSignals" SG_ 860 VCU_PlgConnSt 0;
BA_ "GenSigInactiveValue" SG_ 860 VCU_PlgConnSt 0;
BA_ "GenSigInvalidValue" SG_ 860 VCU_PlgConnSt 0;
BA_ "GenSigSendType" SG_ 860 VCU_PlgConnSt 1;
BA_ "GenSigStartValue" SG_ 860 VCU_PlgConnSt 0;
BA_ "GenSigTimeoutValue" SG_ 860 VCU_PlgConnSt 0;
BA_ "Remark" SG_ 860 VCU_PlgConnSt "";
BA_ "EventCommandSignal" SG_ 860 VCU_EVRng 0;
BA_ "GatewayedSignals" SG_ 860 VCU_EVRng 0;
BA_ "GenSigInactiveValue" SG_ 860 VCU_EVRng 0;
BA_ "GenSigInvalidValue" SG_ 860 VCU_EVRng 0;
BA_ "GenSigSendType" SG_ 860 VCU_EVRng 1;
BA_ "GenSigStartValue" SG_ 860 VCU_EVRng 510;
BA_ "GenSigTimeoutValue" SG_ 860 VCU_EVRng 0;
BA_ "Remark" SG_ 860 VCU_EVRng "";
BA_ "EventCommandSignal" SG_ 860 VCU_GearLvlDisp 0;
BA_ "GatewayedSignals" SG_ 860 VCU_GearLvlDisp 0;
BA_ "GenSigInactiveValue" SG_ 860 VCU_GearLvlDisp 0;
BA_ "GenSigInvalidValue" SG_ 860 VCU_GearLvlDisp 0;
BA_ "GenSigSendType" SG_ 860 VCU_GearLvlDisp 1;
BA_ "GenSigStartValue" SG_ 860 VCU_GearLvlDisp 0;
BA_ "GenSigTimeoutValue" SG_ 860 VCU_GearLvlDisp 0;
BA_ "Remark" SG_ 860 VCU_GearLvlDisp "";
BA_ "EventCommandSignal" SG_ 860 VCU_BMS_BattSocDisp 0;
BA_ "GatewayedSignals" SG_ 860 VCU_BMS_BattSocDisp 0;
BA_ "GenSigInactiveValue" SG_ 860 VCU_BMS_BattSocDisp 0;
BA_ "GenSigInvalidValue" SG_ 860 VCU_BMS_BattSocDisp 255;
BA_ "GenSigSendType" SG_ 860 VCU_BMS_BattSocDisp 1;
BA_ "GenSigStartValue" SG_ 860 VCU_BMS_BattSocDisp 0;
BA_ "GenSigTimeoutValue" SG_ 860 VCU_BMS_BattSocDisp 0;
BA_ "Remark" SG_ 860 VCU_BMS_BattSocDisp "";
BA_ "EventCommandSignal" SG_ 860 VCU_SuspModeReq 0;
BA_ "GatewayedSignals" SG_ 860 VCU_SuspModeReq 0;
BA_ "GenSigInactiveValue" SG_ 860 VCU_SuspModeReq 0;
BA_ "GenSigInvalidValue" SG_ 860 VCU_SuspModeReq 0;
BA_ "GenSigSendType" SG_ 860 VCU_SuspModeReq 1;
BA_ "GenSigStartValue" SG_ 860 VCU_SuspModeReq 0;
BA_ "GenSigTimeoutValue" SG_ 860 VCU_SuspModeReq 0;
BA_ "Remark" SG_ 860 VCU_SuspModeReq "";
BA_ "EventCommandSignal" SG_ 860 VCU_SuspModeReqEnable 0;
BA_ "GatewayedSignals" SG_ 860 VCU_SuspModeReqEnable 0;
BA_ "GenSigInactiveValue" SG_ 860 VCU_SuspModeReqEnable 0;
BA_ "GenSigInvalidValue" SG_ 860 VCU_SuspModeReqEnable 0;
BA_ "GenSigSendType" SG_ 860 VCU_SuspModeReqEnable 1;
BA_ "GenSigStartValue" SG_ 860 VCU_SuspModeReqEnable 0;
BA_ "GenSigTimeoutValue" SG_ 860 VCU_SuspModeReqEnable 0;
BA_ "Remark" SG_ 860 VCU_SuspModeReqEnable "";
BA_ "EventCommandSignal" SG_ 860 VCU_PivotSteeringStAvailable 0;
BA_ "GatewayedSignals" SG_ 860 VCU_PivotSteeringStAvailable 0;
BA_ "GenSigInactiveValue" SG_ 860 VCU_PivotSteeringStAvailable 0;
BA_ "GenSigInvalidValue" SG_ 860 VCU_PivotSteeringStAvailable 0;
BA_ "GenSigSendType" SG_ 860 VCU_PivotSteeringStAvailable 1;
BA_ "GenSigStartValue" SG_ 860 VCU_PivotSteeringStAvailable 0;
BA_ "GenSigTimeoutValue" SG_ 860 VCU_PivotSteeringStAvailable 0;
BA_ "Remark" SG_ 860 VCU_PivotSteeringStAvailable "";
BA_ "EventCommandSignal" SG_ 860 VCU_PivotSteeringSt 0;
BA_ "GatewayedSignals" SG_ 860 VCU_PivotSteeringSt 0;
BA_ "GenSigInactiveValue" SG_ 860 VCU_PivotSteeringSt 0;
BA_ "GenSigInvalidValue" SG_ 860 VCU_PivotSteeringSt 0;
BA_ "GenSigSendType" SG_ 860 VCU_PivotSteeringSt 1;
BA_ "GenSigStartValue" SG_ 860 VCU_PivotSteeringSt 0;
BA_ "GenSigTimeoutValue" SG_ 860 VCU_PivotSteeringSt 0;
BA_ "Remark" SG_ 860 VCU_PivotSteeringSt "";
BA_ "EventCommandSignal" SG_ 860 VCU_GearPosition 0;
BA_ "GatewayedSignals" SG_ 860 VCU_GearPosition 0;
BA_ "GenSigInactiveValue" SG_ 860 VCU_GearPosition 0;
BA_ "GenSigInvalidValue" SG_ 860 VCU_GearPosition 0;
BA_ "GenSigSendType" SG_ 860 VCU_GearPosition 1;
BA_ "GenSigStartValue" SG_ 860 VCU_GearPosition 0;
BA_ "GenSigTimeoutValue" SG_ 860 VCU_GearPosition 0;
BA_ "Remark" SG_ 860 VCU_GearPosition "";
BA_ "EventCommandSignal" SG_ 860 VCU_EcoPlusMod 0;
BA_ "GatewayedSignals" SG_ 860 VCU_EcoPlusMod 0;
BA_ "GenSigInactiveValue" SG_ 860 VCU_EcoPlusMod 0;
BA_ "GenSigInvalidValue" SG_ 860 VCU_EcoPlusMod 0;
BA_ "GenSigSendType" SG_ 860 VCU_EcoPlusMod 1;
BA_ "GenSigStartValue" SG_ 860 VCU_EcoPlusMod 0;
BA_ "GenSigTimeoutValue" SG_ 860 VCU_EcoPlusMod 0;
BA_ "Remark" SG_ 860 VCU_EcoPlusMod "";
BA_ "EventCommandSignal" SG_ 860 ICC_RoadMod 0;
BA_ "GatewayedSignals" SG_ 860 ICC_RoadMod 0;
BA_ "GenSigInactiveValue" SG_ 860 ICC_RoadMod 0;
BA_ "GenSigInvalidValue" SG_ 860 ICC_RoadMod 0;
BA_ "GenSigSendType" SG_ 860 ICC_RoadMod 1;
BA_ "GenSigStartValue" SG_ 860 ICC_RoadMod 0;
BA_ "GenSigTimeoutValue" SG_ 860 ICC_RoadMod 0;
BA_ "Remark" SG_ 860 ICC_RoadMod "";
BA_ "EventCommandSignal" SG_ 431 VCU_TargetRecpTorqSt 0;
BA_ "GatewayedSignals" SG_ 431 VCU_TargetRecpTorqSt 0;
BA_ "GenSigInactiveValue" SG_ 431 VCU_TargetRecpTorqSt 0;
BA_ "GenSigInvalidValue" SG_ 431 VCU_TargetRecpTorqSt 0;
BA_ "GenSigSendType" SG_ 431 VCU_TargetRecpTorqSt 1;
BA_ "GenSigStartValue" SG_ 431 VCU_TargetRecpTorqSt 0;
BA_ "GenSigTimeoutValue" SG_ 431 VCU_TargetRecpTorqSt 0;
BA_ "Remark" SG_ 431 VCU_TargetRecpTorqSt "";
BA_ "EventCommandSignal" SG_ 431 VCU_AccElecECFail 0;
BA_ "GatewayedSignals" SG_ 431 VCU_AccElecECFail 0;
BA_ "GenSigInactiveValue" SG_ 431 VCU_AccElecECFail 0;
BA_ "GenSigInvalidValue" SG_ 431 VCU_AccElecECFail 0;
BA_ "GenSigSendType" SG_ 431 VCU_AccElecECFail 1;
BA_ "GenSigStartValue" SG_ 431 VCU_AccElecECFail 0;
BA_ "GenSigTimeoutValue" SG_ 431 VCU_AccElecECFail 0;
BA_ "Remark" SG_ 431 VCU_AccElecECFail "";
BA_ "EventCommandSignal" SG_ 431 VCU_AccDriverOrvd 0;
BA_ "GatewayedSignals" SG_ 431 VCU_AccDriverOrvd 0;
BA_ "GenSigInactiveValue" SG_ 431 VCU_AccDriverOrvd 0;
BA_ "GenSigInvalidValue" SG_ 431 VCU_AccDriverOrvd 0;
BA_ "GenSigSendType" SG_ 431 VCU_AccDriverOrvd 1;
BA_ "GenSigStartValue" SG_ 431 VCU_AccDriverOrvd 0;
BA_ "GenSigTimeoutValue" SG_ 431 VCU_AccDriverOrvd 0;
BA_ "Remark" SG_ 431 VCU_AccDriverOrvd "";
BA_ "EventCommandSignal" SG_ 431 VCU_AccTMCFail 0;
BA_ "GatewayedSignals" SG_ 431 VCU_AccTMCFail 0;
BA_ "GenSigInactiveValue" SG_ 431 VCU_AccTMCFail 0;
BA_ "GenSigInvalidValue" SG_ 431 VCU_AccTMCFail 0;
BA_ "GenSigSendType" SG_ 431 VCU_AccTMCFail 1;
BA_ "GenSigStartValue" SG_ 431 VCU_AccTMCFail 0;
BA_ "GenSigTimeoutValue" SG_ 431 VCU_AccTMCFail 0;
BA_ "Remark" SG_ 431 VCU_AccTMCFail "";
BA_ "EventCommandSignal" SG_ 431 VCU_TargetRecpTorqNm 0;
BA_ "GatewayedSignals" SG_ 431 VCU_TargetRecpTorqNm 0;
BA_ "GenSigInactiveValue" SG_ 431 VCU_TargetRecpTorqNm 0;
BA_ "GenSigInvalidValue" SG_ 431 VCU_TargetRecpTorqNm 0;
BA_ "GenSigSendType" SG_ 431 VCU_TargetRecpTorqNm 1;
BA_ "GenSigStartValue" SG_ 431 VCU_TargetRecpTorqNm 0;
BA_ "GenSigTimeoutValue" SG_ 431 VCU_TargetRecpTorqNm 0;
BA_ "Remark" SG_ 431 VCU_TargetRecpTorqNm "";
BA_ "EventCommandSignal" SG_ 431 VCU_TargetRecpTorqFA 0;
BA_ "GatewayedSignals" SG_ 431 VCU_TargetRecpTorqFA 0;
BA_ "GenSigInactiveValue" SG_ 431 VCU_TargetRecpTorqFA 0;
BA_ "GenSigInvalidValue" SG_ 431 VCU_TargetRecpTorqFA 0;
BA_ "GenSigSendType" SG_ 431 VCU_TargetRecpTorqFA 1;
BA_ "GenSigStartValue" SG_ 431 VCU_TargetRecpTorqFA 0;
BA_ "GenSigTimeoutValue" SG_ 431 VCU_TargetRecpTorqFA 0;
BA_ "Remark" SG_ 431 VCU_TargetRecpTorqFA "";
BA_ "EventCommandSignal" SG_ 431 VCU_TargetRecpTorqRA 0;
BA_ "GatewayedSignals" SG_ 431 VCU_TargetRecpTorqRA 0;
BA_ "GenSigInactiveValue" SG_ 431 VCU_TargetRecpTorqRA 0;
BA_ "GenSigInvalidValue" SG_ 431 VCU_TargetRecpTorqRA 0;
BA_ "GenSigSendType" SG_ 431 VCU_TargetRecpTorqRA 1;
BA_ "GenSigStartValue" SG_ 431 VCU_TargetRecpTorqRA 0;
BA_ "GenSigTimeoutValue" SG_ 431 VCU_TargetRecpTorqRA 0;
BA_ "Remark" SG_ 431 VCU_TargetRecpTorqRA "";
BA_ "EventCommandSignal" SG_ 431 VCU_TorqDriverReqFA 0;
BA_ "GatewayedSignals" SG_ 431 VCU_TorqDriverReqFA 0;
BA_ "GenSigInactiveValue" SG_ 431 VCU_TorqDriverReqFA 0;
BA_ "GenSigInvalidValue" SG_ 431 VCU_TorqDriverReqFA 0;
BA_ "GenSigSendType" SG_ 431 VCU_TorqDriverReqFA 1;
BA_ "GenSigStartValue" SG_ 431 VCU_TorqDriverReqFA 0;
BA_ "GenSigTimeoutValue" SG_ 431 VCU_TorqDriverReqFA 0;
BA_ "Remark" SG_ 431 VCU_TorqDriverReqFA "";
BA_ "EventCommandSignal" SG_ 431 VCU_TorqDriverReqRA 0;
BA_ "GatewayedSignals" SG_ 431 VCU_TorqDriverReqRA 0;
BA_ "GenSigInactiveValue" SG_ 431 VCU_TorqDriverReqRA 0;
BA_ "GenSigInvalidValue" SG_ 431 VCU_TorqDriverReqRA 0;
BA_ "GenSigSendType" SG_ 431 VCU_TorqDriverReqRA 1;
BA_ "GenSigStartValue" SG_ 431 VCU_TorqDriverReqRA 0;
BA_ "GenSigTimeoutValue" SG_ 431 VCU_TorqDriverReqRA 0;
BA_ "Remark" SG_ 431 VCU_TorqDriverReqRA "";
BA_ "EventCommandSignal" SG_ 431 VCU_VehActDrvTorqFA 0;
BA_ "GatewayedSignals" SG_ 431 VCU_VehActDrvTorqFA 0;
BA_ "GenSigInactiveValue" SG_ 431 VCU_VehActDrvTorqFA 0;
BA_ "GenSigInvalidValue" SG_ 431 VCU_VehActDrvTorqFA 0;
BA_ "GenSigSendType" SG_ 431 VCU_VehActDrvTorqFA 1;
BA_ "GenSigStartValue" SG_ 431 VCU_VehActDrvTorqFA 0;
BA_ "GenSigTimeoutValue" SG_ 431 VCU_VehActDrvTorqFA 0;
BA_ "Remark" SG_ 431 VCU_VehActDrvTorqFA "";
BA_ "EventCommandSignal" SG_ 431 VCU_VehActDrvTorqRA 0;
BA_ "GatewayedSignals" SG_ 431 VCU_VehActDrvTorqRA 0;
BA_ "GenSigInactiveValue" SG_ 431 VCU_VehActDrvTorqRA 0;
BA_ "GenSigInvalidValue" SG_ 431 VCU_VehActDrvTorqRA 0;
BA_ "GenSigSendType" SG_ 431 VCU_VehActDrvTorqRA 1;
BA_ "GenSigStartValue" SG_ 431 VCU_VehActDrvTorqRA 0;
BA_ "GenSigTimeoutValue" SG_ 431 VCU_VehActDrvTorqRA 0;
BA_ "Remark" SG_ 431 VCU_VehActDrvTorqRA "";
BA_ "EventCommandSignal" SG_ 431 VCU_TargetRecpTorqFAVD 0;
BA_ "GatewayedSignals" SG_ 431 VCU_TargetRecpTorqFAVD 0;
BA_ "GenSigInactiveValue" SG_ 431 VCU_TargetRecpTorqFAVD 0;
BA_ "GenSigInvalidValue" SG_ 431 VCU_TargetRecpTorqFAVD 0;
BA_ "GenSigSendType" SG_ 431 VCU_TargetRecpTorqFAVD 1;
BA_ "GenSigStartValue" SG_ 431 VCU_TargetRecpTorqFAVD 0;
BA_ "GenSigTimeoutValue" SG_ 431 VCU_TargetRecpTorqFAVD 0;
BA_ "Remark" SG_ 431 VCU_TargetRecpTorqFAVD "";
BA_ "EventCommandSignal" SG_ 431 VCU_TargetRecpTorqRAVD 0;
BA_ "GatewayedSignals" SG_ 431 VCU_TargetRecpTorqRAVD 0;
BA_ "GenSigInactiveValue" SG_ 431 VCU_TargetRecpTorqRAVD 0;
BA_ "GenSigInvalidValue" SG_ 431 VCU_TargetRecpTorqRAVD 0;
BA_ "GenSigSendType" SG_ 431 VCU_TargetRecpTorqRAVD 1;
BA_ "GenSigStartValue" SG_ 431 VCU_TargetRecpTorqRAVD 0;
BA_ "GenSigTimeoutValue" SG_ 431 VCU_TargetRecpTorqRAVD 0;
BA_ "Remark" SG_ 431 VCU_TargetRecpTorqRAVD "";
BA_ "EventCommandSignal" SG_ 431 VCU_TorqDriverReqFAVD 0;
BA_ "GatewayedSignals" SG_ 431 VCU_TorqDriverReqFAVD 0;
BA_ "GenSigInactiveValue" SG_ 431 VCU_TorqDriverReqFAVD 0;
BA_ "GenSigInvalidValue" SG_ 431 VCU_TorqDriverReqFAVD 0;
BA_ "GenSigSendType" SG_ 431 VCU_TorqDriverReqFAVD 1;
BA_ "GenSigStartValue" SG_ 431 VCU_TorqDriverReqFAVD 0;
BA_ "GenSigTimeoutValue" SG_ 431 VCU_TorqDriverReqFAVD 0;
BA_ "Remark" SG_ 431 VCU_TorqDriverReqFAVD "";
BA_ "EventCommandSignal" SG_ 431 VCU_TorqDriverReqRAVD 0;
BA_ "GatewayedSignals" SG_ 431 VCU_TorqDriverReqRAVD 0;
BA_ "GenSigInactiveValue" SG_ 431 VCU_TorqDriverReqRAVD 0;
BA_ "GenSigInvalidValue" SG_ 431 VCU_TorqDriverReqRAVD 0;
BA_ "GenSigSendType" SG_ 431 VCU_TorqDriverReqRAVD 1;
BA_ "GenSigStartValue" SG_ 431 VCU_TorqDriverReqRAVD 0;
BA_ "GenSigTimeoutValue" SG_ 431 VCU_TorqDriverReqRAVD 0;
BA_ "Remark" SG_ 431 VCU_TorqDriverReqRAVD "";
BA_ "EventCommandSignal" SG_ 431 VCU_VehActDrvTorqFAVD 0;
BA_ "GatewayedSignals" SG_ 431 VCU_VehActDrvTorqFAVD 0;
BA_ "GenSigInactiveValue" SG_ 431 VCU_VehActDrvTorqFAVD 0;
BA_ "GenSigInvalidValue" SG_ 431 VCU_VehActDrvTorqFAVD 0;
BA_ "GenSigSendType" SG_ 431 VCU_VehActDrvTorqFAVD 1;
BA_ "GenSigStartValue" SG_ 431 VCU_VehActDrvTorqFAVD 0;
BA_ "GenSigTimeoutValue" SG_ 431 VCU_VehActDrvTorqFAVD 0;
BA_ "Remark" SG_ 431 VCU_VehActDrvTorqFAVD "";
BA_ "EventCommandSignal" SG_ 431 VCU_VehActDrvTorqRAVD 0;
BA_ "GatewayedSignals" SG_ 431 VCU_VehActDrvTorqRAVD 0;
BA_ "GenSigInactiveValue" SG_ 431 VCU_VehActDrvTorqRAVD 0;
BA_ "GenSigInvalidValue" SG_ 431 VCU_VehActDrvTorqRAVD 0;
BA_ "GenSigSendType" SG_ 431 VCU_VehActDrvTorqRAVD 1;
BA_ "GenSigStartValue" SG_ 431 VCU_VehActDrvTorqRAVD 0;
BA_ "GenSigTimeoutValue" SG_ 431 VCU_VehActDrvTorqRAVD 0;
BA_ "Remark" SG_ 431 VCU_VehActDrvTorqRAVD "";
BA_ "EventCommandSignal" SG_ 431 VCU_BcsDecelReq 0;
BA_ "GatewayedSignals" SG_ 431 VCU_BcsDecelReq 0;
BA_ "GenSigInactiveValue" SG_ 431 VCU_BcsDecelReq 0;
BA_ "GenSigInvalidValue" SG_ 431 VCU_BcsDecelReq 0;
BA_ "GenSigSendType" SG_ 431 VCU_BcsDecelReq 1;
BA_ "GenSigStartValue" SG_ 431 VCU_BcsDecelReq 15;
BA_ "GenSigTimeoutValue" SG_ 431 VCU_BcsDecelReq 0;
BA_ "Remark" SG_ 431 VCU_BcsDecelReq "";
BA_ "EventCommandSignal" SG_ 431 VCU_BcsDecelVD 0;
BA_ "GatewayedSignals" SG_ 431 VCU_BcsDecelVD 0;
BA_ "GenSigInactiveValue" SG_ 431 VCU_BcsDecelVD 0;
BA_ "GenSigInvalidValue" SG_ 431 VCU_BcsDecelVD 0;
BA_ "GenSigSendType" SG_ 431 VCU_BcsDecelVD 1;
BA_ "GenSigStartValue" SG_ 431 VCU_BcsDecelVD 0;
BA_ "GenSigTimeoutValue" SG_ 431 VCU_BcsDecelVD 0;
BA_ "Remark" SG_ 431 VCU_BcsDecelVD "";
BA_ "EventCommandSignal" SG_ 431 VCU_RecpTorqRL 0;
BA_ "GatewayedSignals" SG_ 431 VCU_RecpTorqRL 0;
BA_ "GenSigInactiveValue" SG_ 431 VCU_RecpTorqRL 0;
BA_ "GenSigInvalidValue" SG_ 431 VCU_RecpTorqRL 0;
BA_ "GenSigSendType" SG_ 431 VCU_RecpTorqRL 1;
BA_ "GenSigStartValue" SG_ 431 VCU_RecpTorqRL 0;
BA_ "GenSigTimeoutValue" SG_ 431 VCU_RecpTorqRL 0;
BA_ "Remark" SG_ 431 VCU_RecpTorqRL "";
BA_ "EventCommandSignal" SG_ 431 VCU_RecpTorqRLVD 0;
BA_ "GatewayedSignals" SG_ 431 VCU_RecpTorqRLVD 0;
BA_ "GenSigInactiveValue" SG_ 431 VCU_RecpTorqRLVD 0;
BA_ "GenSigInvalidValue" SG_ 431 VCU_RecpTorqRLVD 0;
BA_ "GenSigSendType" SG_ 431 VCU_RecpTorqRLVD 1;
BA_ "GenSigStartValue" SG_ 431 VCU_RecpTorqRLVD 0;
BA_ "GenSigTimeoutValue" SG_ 431 VCU_RecpTorqRLVD 0;
BA_ "Remark" SG_ 431 VCU_RecpTorqRLVD "";
BA_ "EventCommandSignal" SG_ 431 VCU_RecpTorqRR 0;
BA_ "GatewayedSignals" SG_ 431 VCU_RecpTorqRR 0;
BA_ "GenSigInactiveValue" SG_ 431 VCU_RecpTorqRR 0;
BA_ "GenSigInvalidValue" SG_ 431 VCU_RecpTorqRR 0;
BA_ "GenSigSendType" SG_ 431 VCU_RecpTorqRR 1;
BA_ "GenSigStartValue" SG_ 431 VCU_RecpTorqRR 0;
BA_ "GenSigTimeoutValue" SG_ 431 VCU_RecpTorqRR 0;
BA_ "Remark" SG_ 431 VCU_RecpTorqRR "";
BA_ "EventCommandSignal" SG_ 431 VCU_RecpTorqRRVD 0;
BA_ "GatewayedSignals" SG_ 431 VCU_RecpTorqRRVD 0;
BA_ "GenSigInactiveValue" SG_ 431 VCU_RecpTorqRRVD 0;
BA_ "GenSigInvalidValue" SG_ 431 VCU_RecpTorqRRVD 0;
BA_ "GenSigSendType" SG_ 431 VCU_RecpTorqRRVD 1;
BA_ "GenSigStartValue" SG_ 431 VCU_RecpTorqRRVD 0;
BA_ "GenSigTimeoutValue" SG_ 431 VCU_RecpTorqRRVD 0;
BA_ "Remark" SG_ 431 VCU_RecpTorqRRVD "";
BA_ "EventCommandSignal" SG_ 431 VCU_ADSNetErrorFb 0;
BA_ "GatewayedSignals" SG_ 431 VCU_ADSNetErrorFb 0;
BA_ "GenSigInactiveValue" SG_ 431 VCU_ADSNetErrorFb 0;
BA_ "GenSigInvalidValue" SG_ 431 VCU_ADSNetErrorFb 0;
BA_ "GenSigSendType" SG_ 431 VCU_ADSNetErrorFb 1;
BA_ "GenSigStartValue" SG_ 431 VCU_ADSNetErrorFb 0;
BA_ "GenSigTimeoutValue" SG_ 431 VCU_ADSNetErrorFb 0;
BA_ "Remark" SG_ 431 VCU_ADSNetErrorFb "";
BA_ "EventCommandSignal" SG_ 431 VCU_NetModeResp 0;
BA_ "GatewayedSignals" SG_ 431 VCU_NetModeResp 0;
BA_ "GenSigInactiveValue" SG_ 431 VCU_NetModeResp 0;
BA_ "GenSigInvalidValue" SG_ 431 VCU_NetModeResp 0;
BA_ "GenSigSendType" SG_ 431 VCU_NetModeResp 1;
BA_ "GenSigStartValue" SG_ 431 VCU_NetModeResp 0;
BA_ "GenSigTimeoutValue" SG_ 431 VCU_NetModeResp 0;
BA_ "Remark" SG_ 431 VCU_NetModeResp "";
BA_ "EventCommandSignal" SG_ 516 VCU_9_CRC 0;
BA_ "GatewayedSignals" SG_ 516 VCU_9_CRC 0;
BA_ "GenSigInactiveValue" SG_ 516 VCU_9_CRC 0;
BA_ "GenSigInvalidValue" SG_ 516 VCU_9_CRC 0;
BA_ "GenSigSendType" SG_ 516 VCU_9_CRC 1;
BA_ "GenSigStartValue" SG_ 516 VCU_9_CRC 0;
BA_ "GenSigTimeoutValue" SG_ 516 VCU_9_CRC 0;
BA_ "Remark" SG_ 516 VCU_9_CRC "";
BA_ "EventCommandSignal" SG_ 516 VCU_9_Counter 0;
BA_ "GatewayedSignals" SG_ 516 VCU_9_Counter 0;
BA_ "GenSigInactiveValue" SG_ 516 VCU_9_Counter 0;
BA_ "GenSigInvalidValue" SG_ 516 VCU_9_Counter 0;
BA_ "GenSigSendType" SG_ 516 VCU_9_Counter 1;
BA_ "GenSigStartValue" SG_ 516 VCU_9_Counter 0;
BA_ "GenSigTimeoutValue" SG_ 516 VCU_9_Counter 0;
BA_ "Remark" SG_ 516 VCU_9_Counter "";
BA_ "EventCommandSignal" SG_ 516 VCU_VehWheelTorqMaxVD 0;
BA_ "GatewayedSignals" SG_ 516 VCU_VehWheelTorqMaxVD 0;
BA_ "GenSigInactiveValue" SG_ 516 VCU_VehWheelTorqMaxVD 0;
BA_ "GenSigInvalidValue" SG_ 516 VCU_VehWheelTorqMaxVD 0;
BA_ "GenSigSendType" SG_ 516 VCU_VehWheelTorqMaxVD 1;
BA_ "GenSigStartValue" SG_ 516 VCU_VehWheelTorqMaxVD 0;
BA_ "GenSigTimeoutValue" SG_ 516 VCU_VehWheelTorqMaxVD 0;
BA_ "Remark" SG_ 516 VCU_VehWheelTorqMaxVD "";
BA_ "EventCommandSignal" SG_ 516 VCU_RecpTorq 0;
BA_ "GatewayedSignals" SG_ 516 VCU_RecpTorq 0;
BA_ "GenSigInactiveValue" SG_ 516 VCU_RecpTorq 0;
BA_ "GenSigInvalidValue" SG_ 516 VCU_RecpTorq 0;
BA_ "GenSigSendType" SG_ 516 VCU_RecpTorq 1;
BA_ "GenSigStartValue" SG_ 516 VCU_RecpTorq 0;
BA_ "GenSigTimeoutValue" SG_ 516 VCU_RecpTorq 0;
BA_ "Remark" SG_ 516 VCU_RecpTorq "";
BA_ "EventCommandSignal" SG_ 516 VCU_RecpTorqSt 0;
BA_ "GatewayedSignals" SG_ 516 VCU_RecpTorqSt 0;
BA_ "GenSigInactiveValue" SG_ 516 VCU_RecpTorqSt 0;
BA_ "GenSigInvalidValue" SG_ 516 VCU_RecpTorqSt 0;
BA_ "GenSigSendType" SG_ 516 VCU_RecpTorqSt 1;
BA_ "GenSigStartValue" SG_ 516 VCU_RecpTorqSt 0;
BA_ "GenSigTimeoutValue" SG_ 516 VCU_RecpTorqSt 0;
BA_ "Remark" SG_ 516 VCU_RecpTorqSt "";
BA_ "EventCommandSignal" SG_ 516 VCU_MaxRecpTorqSt 0;
BA_ "GatewayedSignals" SG_ 516 VCU_MaxRecpTorqSt 0;
BA_ "GenSigInactiveValue" SG_ 516 VCU_MaxRecpTorqSt 0;
BA_ "GenSigInvalidValue" SG_ 516 VCU_MaxRecpTorqSt 0;
BA_ "GenSigSendType" SG_ 516 VCU_MaxRecpTorqSt 1;
BA_ "GenSigStartValue" SG_ 516 VCU_MaxRecpTorqSt 0;
BA_ "GenSigTimeoutValue" SG_ 516 VCU_MaxRecpTorqSt 0;
BA_ "Remark" SG_ 516 VCU_MaxRecpTorqSt "";
BA_ "EventCommandSignal" SG_ 516 VCU_MaxRecpTorq 0;
BA_ "GatewayedSignals" SG_ 516 VCU_MaxRecpTorq 0;
BA_ "GenSigInactiveValue" SG_ 516 VCU_MaxRecpTorq 0;
BA_ "GenSigInvalidValue" SG_ 516 VCU_MaxRecpTorq 0;
BA_ "GenSigSendType" SG_ 516 VCU_MaxRecpTorq 1;
BA_ "GenSigStartValue" SG_ 516 VCU_MaxRecpTorq 0;
BA_ "GenSigTimeoutValue" SG_ 516 VCU_MaxRecpTorq 0;
BA_ "Remark" SG_ 516 VCU_MaxRecpTorq "";
BA_ "EventCommandSignal" SG_ 516 VCU_CrntGearLvl 0;
BA_ "GatewayedSignals" SG_ 516 VCU_CrntGearLvl 0;
BA_ "GenSigInactiveValue" SG_ 516 VCU_CrntGearLvl 0;
BA_ "GenSigInvalidValue" SG_ 516 VCU_CrntGearLvl 0;
BA_ "GenSigSendType" SG_ 516 VCU_CrntGearLvl 1;
BA_ "GenSigStartValue" SG_ 516 VCU_CrntGearLvl 0;
BA_ "GenSigTimeoutValue" SG_ 516 VCU_CrntGearLvl 0;
BA_ "Remark" SG_ 516 VCU_CrntGearLvl "";
BA_ "EventCommandSignal" SG_ 516 VCU_CrntGearLvlVD 0;
BA_ "GatewayedSignals" SG_ 516 VCU_CrntGearLvlVD 0;
BA_ "GenSigInactiveValue" SG_ 516 VCU_CrntGearLvlVD 0;
BA_ "GenSigInvalidValue" SG_ 516 VCU_CrntGearLvlVD 0;
BA_ "GenSigSendType" SG_ 516 VCU_CrntGearLvlVD 1;
BA_ "GenSigStartValue" SG_ 516 VCU_CrntGearLvlVD 0;
BA_ "GenSigTimeoutValue" SG_ 516 VCU_CrntGearLvlVD 0;
BA_ "Remark" SG_ 516 VCU_CrntGearLvlVD "";
BA_ "EventCommandSignal" SG_ 516 VCU_BrkPedPstVD 0;
BA_ "GatewayedSignals" SG_ 516 VCU_BrkPedPstVD 0;
BA_ "GenSigInactiveValue" SG_ 516 VCU_BrkPedPstVD 0;
BA_ "GenSigInvalidValue" SG_ 516 VCU_BrkPedPstVD 0;
BA_ "GenSigSendType" SG_ 516 VCU_BrkPedPstVD 1;
BA_ "GenSigStartValue" SG_ 516 VCU_BrkPedPstVD 0;
BA_ "GenSigTimeoutValue" SG_ 516 VCU_BrkPedPstVD 0;
BA_ "Remark" SG_ 516 VCU_BrkPedPstVD "";
BA_ "EventCommandSignal" SG_ 516 VCU_BrkPedPst 0;
BA_ "GatewayedSignals" SG_ 516 VCU_BrkPedPst 0;
BA_ "GenSigInactiveValue" SG_ 516 VCU_BrkPedPst 0;
BA_ "GenSigInvalidValue" SG_ 516 VCU_BrkPedPst 0;
BA_ "GenSigSendType" SG_ 516 VCU_BrkPedPst 1;
BA_ "GenSigStartValue" SG_ 516 VCU_BrkPedPst 0;
BA_ "GenSigTimeoutValue" SG_ 516 VCU_BrkPedPst 0;
BA_ "Remark" SG_ 516 VCU_BrkPedPst "";
BA_ "EventCommandSignal" SG_ 516 VCU_APAGasPedalIntv 0;
BA_ "GatewayedSignals" SG_ 516 VCU_APAGasPedalIntv 0;
BA_ "GenSigInactiveValue" SG_ 516 VCU_APAGasPedalIntv 0;
BA_ "GenSigInvalidValue" SG_ 516 VCU_APAGasPedalIntv 0;
BA_ "GenSigSendType" SG_ 516 VCU_APAGasPedalIntv 1;
BA_ "GenSigStartValue" SG_ 516 VCU_APAGasPedalIntv 0;
BA_ "GenSigTimeoutValue" SG_ 516 VCU_APAGasPedalIntv 0;
BA_ "Remark" SG_ 516 VCU_APAGasPedalIntv "";
BA_ "EventCommandSignal" SG_ 516 VCU_APAAvailable 0;
BA_ "GatewayedSignals" SG_ 516 VCU_APAAvailable 0;
BA_ "GenSigInactiveValue" SG_ 516 VCU_APAAvailable 0;
BA_ "GenSigInvalidValue" SG_ 516 VCU_APAAvailable 0;
BA_ "GenSigSendType" SG_ 516 VCU_APAAvailable 1;
BA_ "GenSigStartValue" SG_ 516 VCU_APAAvailable 0;
BA_ "GenSigTimeoutValue" SG_ 516 VCU_APAAvailable 0;
BA_ "Remark" SG_ 516 VCU_APAAvailable "";
BA_ "EventCommandSignal" SG_ 516 VCU_APAWheelTorqDriverReq 0;
BA_ "GatewayedSignals" SG_ 516 VCU_APAWheelTorqDriverReq 0;
BA_ "GenSigInactiveValue" SG_ 516 VCU_APAWheelTorqDriverReq 0;
BA_ "GenSigInvalidValue" SG_ 516 VCU_APAWheelTorqDriverReq 16383;
BA_ "GenSigSendType" SG_ 516 VCU_APAWheelTorqDriverReq 1;
BA_ "GenSigStartValue" SG_ 516 VCU_APAWheelTorqDriverReq 16382;
BA_ "GenSigTimeoutValue" SG_ 516 VCU_APAWheelTorqDriverReq 0;
BA_ "Remark" SG_ 516 VCU_APAWheelTorqDriverReq "";
BA_ "EventCommandSignal" SG_ 516 VCU_APAGearIntervern 0;
BA_ "GatewayedSignals" SG_ 516 VCU_APAGearIntervern 0;
BA_ "GenSigInactiveValue" SG_ 516 VCU_APAGearIntervern 0;
BA_ "GenSigInvalidValue" SG_ 516 VCU_APAGearIntervern 0;
BA_ "GenSigSendType" SG_ 516 VCU_APAGearIntervern 1;
BA_ "GenSigStartValue" SG_ 516 VCU_APAGearIntervern 0;
BA_ "GenSigTimeoutValue" SG_ 516 VCU_APAGearIntervern 0;
BA_ "Remark" SG_ 516 VCU_APAGearIntervern "";
BA_ "EventCommandSignal" SG_ 516 VCU_EMS_AccPedalActPst 0;
BA_ "GatewayedSignals" SG_ 516 VCU_EMS_AccPedalActPst 0;
BA_ "GenSigInactiveValue" SG_ 516 VCU_EMS_AccPedalActPst 0;
BA_ "GenSigInvalidValue" SG_ 516 VCU_EMS_AccPedalActPst 0;
BA_ "GenSigSendType" SG_ 516 VCU_EMS_AccPedalActPst 1;
BA_ "GenSigStartValue" SG_ 516 VCU_EMS_AccPedalActPst 0;
BA_ "GenSigTimeoutValue" SG_ 516 VCU_EMS_AccPedalActPst 0;
BA_ "Remark" SG_ 516 VCU_EMS_AccPedalActPst "";
BA_ "EventCommandSignal" SG_ 516 VCU_EMS_AccPedalActPstVD 0;
BA_ "GatewayedSignals" SG_ 516 VCU_EMS_AccPedalActPstVD 0;
BA_ "GenSigInactiveValue" SG_ 516 VCU_EMS_AccPedalActPstVD 0;
BA_ "GenSigInvalidValue" SG_ 516 VCU_EMS_AccPedalActPstVD 0;
BA_ "GenSigSendType" SG_ 516 VCU_EMS_AccPedalActPstVD 1;
BA_ "GenSigStartValue" SG_ 516 VCU_EMS_AccPedalActPstVD 0;
BA_ "GenSigTimeoutValue" SG_ 516 VCU_EMS_AccPedalActPstVD 0;
BA_ "Remark" SG_ 516 VCU_EMS_AccPedalActPstVD "";
BA_ "EventCommandSignal" SG_ 516 VCU_ActVehWheelTorq 0;
BA_ "GatewayedSignals" SG_ 516 VCU_ActVehWheelTorq 0;
BA_ "GenSigInactiveValue" SG_ 516 VCU_ActVehWheelTorq 0;
BA_ "GenSigInvalidValue" SG_ 516 VCU_ActVehWheelTorq 0;
BA_ "GenSigSendType" SG_ 516 VCU_ActVehWheelTorq 1;
BA_ "GenSigStartValue" SG_ 516 VCU_ActVehWheelTorq 16382;
BA_ "GenSigTimeoutValue" SG_ 516 VCU_ActVehWheelTorq 0;
BA_ "Remark" SG_ 516 VCU_ActVehWheelTorq "";
BA_ "EventCommandSignal" SG_ 516 VCU_VehWheelTorqMax 0;
BA_ "GatewayedSignals" SG_ 516 VCU_VehWheelTorqMax 0;
BA_ "GenSigInactiveValue" SG_ 516 VCU_VehWheelTorqMax 0;
BA_ "GenSigInvalidValue" SG_ 516 VCU_VehWheelTorqMax 0;
BA_ "GenSigSendType" SG_ 516 VCU_VehWheelTorqMax 1;
BA_ "GenSigStartValue" SG_ 516 VCU_VehWheelTorqMax 16382;
BA_ "GenSigTimeoutValue" SG_ 516 VCU_VehWheelTorqMax 0;
BA_ "Remark" SG_ 516 VCU_VehWheelTorqMax "";
BA_ "EventCommandSignal" SG_ 516 VCU_EMS_BrkPedalSt 0;
BA_ "GatewayedSignals" SG_ 516 VCU_EMS_BrkPedalSt 0;
BA_ "GenSigInactiveValue" SG_ 516 VCU_EMS_BrkPedalSt 0;
BA_ "GenSigInvalidValue" SG_ 516 VCU_EMS_BrkPedalSt 0;
BA_ "GenSigSendType" SG_ 516 VCU_EMS_BrkPedalSt 1;
BA_ "GenSigStartValue" SG_ 516 VCU_EMS_BrkPedalSt 0;
BA_ "GenSigTimeoutValue" SG_ 516 VCU_EMS_BrkPedalSt 0;
BA_ "Remark" SG_ 516 VCU_EMS_BrkPedalSt "";
BA_ "EventCommandSignal" SG_ 516 VCU_EMS_BrkPedalStVD 0;
BA_ "GatewayedSignals" SG_ 516 VCU_EMS_BrkPedalStVD 0;
BA_ "GenSigInactiveValue" SG_ 516 VCU_EMS_BrkPedalStVD 0;
BA_ "GenSigInvalidValue" SG_ 516 VCU_EMS_BrkPedalStVD 0;
BA_ "GenSigSendType" SG_ 516 VCU_EMS_BrkPedalStVD 1;
BA_ "GenSigStartValue" SG_ 516 VCU_EMS_BrkPedalStVD 0;
BA_ "GenSigTimeoutValue" SG_ 516 VCU_EMS_BrkPedalStVD 0;
BA_ "Remark" SG_ 516 VCU_EMS_BrkPedalStVD "";
BA_ "EventCommandSignal" SG_ 516 VCU_ACCMaxRecpDecelVD 0;
BA_ "GatewayedSignals" SG_ 516 VCU_ACCMaxRecpDecelVD 0;
BA_ "GenSigInactiveValue" SG_ 516 VCU_ACCMaxRecpDecelVD 0;
BA_ "GenSigInvalidValue" SG_ 516 VCU_ACCMaxRecpDecelVD 0;
BA_ "GenSigSendType" SG_ 516 VCU_ACCMaxRecpDecelVD 1;
BA_ "GenSigStartValue" SG_ 516 VCU_ACCMaxRecpDecelVD 0;
BA_ "GenSigTimeoutValue" SG_ 516 VCU_ACCMaxRecpDecelVD 0;
BA_ "Remark" SG_ 516 VCU_ACCMaxRecpDecelVD "";
BA_ "EventCommandSignal" SG_ 516 VCU_ACCLimitOperatingSt 0;
BA_ "GatewayedSignals" SG_ 516 VCU_ACCLimitOperatingSt 0;
BA_ "GenSigInactiveValue" SG_ 516 VCU_ACCLimitOperatingSt 0;
BA_ "GenSigInvalidValue" SG_ 516 VCU_ACCLimitOperatingSt 0;
BA_ "GenSigSendType" SG_ 516 VCU_ACCLimitOperatingSt 1;
BA_ "GenSigStartValue" SG_ 516 VCU_ACCLimitOperatingSt 0;
BA_ "GenSigTimeoutValue" SG_ 516 VCU_ACCLimitOperatingSt 0;
BA_ "Remark" SG_ 516 VCU_ACCLimitOperatingSt "";
BA_ "EventCommandSignal" SG_ 516 VCU_APAResp 0;
BA_ "GatewayedSignals" SG_ 516 VCU_APAResp 0;
BA_ "GenSigInactiveValue" SG_ 516 VCU_APAResp 0;
BA_ "GenSigInvalidValue" SG_ 516 VCU_APAResp 0;
BA_ "GenSigSendType" SG_ 516 VCU_APAResp 1;
BA_ "GenSigStartValue" SG_ 516 VCU_APAResp 0;
BA_ "GenSigTimeoutValue" SG_ 516 VCU_APAResp 0;
BA_ "Remark" SG_ 516 VCU_APAResp "";
BA_ "EventCommandSignal" SG_ 516 VCU_ADSEcoModReq 0;
BA_ "GatewayedSignals" SG_ 516 VCU_ADSEcoModReq 0;
BA_ "GenSigInactiveValue" SG_ 516 VCU_ADSEcoModReq 0;
BA_ "GenSigInvalidValue" SG_ 516 VCU_ADSEcoModReq 0;
BA_ "GenSigSendType" SG_ 516 VCU_ADSEcoModReq 1;
BA_ "GenSigStartValue" SG_ 516 VCU_ADSEcoModReq 0;
BA_ "GenSigTimeoutValue" SG_ 516 VCU_ADSEcoModReq 0;
BA_ "Remark" SG_ 516 VCU_ADSEcoModReq "";
BA_ "EventCommandSignal" SG_ 516 VCU_AccButtInfo 0;
BA_ "GatewayedSignals" SG_ 516 VCU_AccButtInfo 0;
BA_ "GenSigInactiveValue" SG_ 516 VCU_AccButtInfo 0;
BA_ "GenSigInvalidValue" SG_ 516 VCU_AccButtInfo 0;
BA_ "GenSigSendType" SG_ 516 VCU_AccButtInfo 1;
BA_ "GenSigStartValue" SG_ 516 VCU_AccButtInfo 0;
BA_ "GenSigTimeoutValue" SG_ 516 VCU_AccButtInfo 0;
BA_ "Remark" SG_ 516 VCU_AccButtInfo "";
BA_ "EventCommandSignal" SG_ 516 VCU_ACCMaxRecpDecel 0;
BA_ "GatewayedSignals" SG_ 516 VCU_ACCMaxRecpDecel 0;
BA_ "GenSigInactiveValue" SG_ 516 VCU_ACCMaxRecpDecel 0;
BA_ "GenSigInvalidValue" SG_ 516 VCU_ACCMaxRecpDecel 0;
BA_ "GenSigSendType" SG_ 516 VCU_ACCMaxRecpDecel 1;
BA_ "GenSigStartValue" SG_ 516 VCU_ACCMaxRecpDecel 0;
BA_ "GenSigTimeoutValue" SG_ 516 VCU_ACCMaxRecpDecel 0;
BA_ "Remark" SG_ 516 VCU_ACCMaxRecpDecel "";
BA_ "EventCommandSignal" SG_ 516 VCU_ACCmaxSpdLimit 0;
BA_ "GatewayedSignals" SG_ 516 VCU_ACCmaxSpdLimit 0;
BA_ "GenSigInactiveValue" SG_ 516 VCU_ACCmaxSpdLimit 0;
BA_ "GenSigInvalidValue" SG_ 516 VCU_ACCmaxSpdLimit 0;
BA_ "GenSigSendType" SG_ 516 VCU_ACCmaxSpdLimit 1;
BA_ "GenSigStartValue" SG_ 516 VCU_ACCmaxSpdLimit 0;
BA_ "GenSigTimeoutValue" SG_ 516 VCU_ACCmaxSpdLimit 0;
BA_ "Remark" SG_ 516 VCU_ACCmaxSpdLimit "";
BA_ "EventCommandSignal" SG_ 516 VCU_APA_Resp 0;
BA_ "GatewayedSignals" SG_ 516 VCU_APA_Resp 0;
BA_ "GenSigInactiveValue" SG_ 516 VCU_APA_Resp 0;
BA_ "GenSigInvalidValue" SG_ 516 VCU_APA_Resp 0;
BA_ "GenSigSendType" SG_ 516 VCU_APA_Resp 1;
BA_ "GenSigStartValue" SG_ 516 VCU_APA_Resp 0;
BA_ "GenSigTimeoutValue" SG_ 516 VCU_APA_Resp 0;
BA_ "Remark" SG_ 516 VCU_APA_Resp "";
BA_ "EventCommandSignal" SG_ 516 VCU_RecpTorqFAVD 0;
BA_ "GatewayedSignals" SG_ 516 VCU_RecpTorqFAVD 0;
BA_ "GenSigInactiveValue" SG_ 516 VCU_RecpTorqFAVD 0;
BA_ "GenSigInvalidValue" SG_ 516 VCU_RecpTorqFAVD 0;
BA_ "GenSigSendType" SG_ 516 VCU_RecpTorqFAVD 1;
BA_ "GenSigStartValue" SG_ 516 VCU_RecpTorqFAVD 0;
BA_ "GenSigTimeoutValue" SG_ 516 VCU_RecpTorqFAVD 0;
BA_ "Remark" SG_ 516 VCU_RecpTorqFAVD "";
BA_ "EventCommandSignal" SG_ 516 VCU_RecpTorqRAVD 0;
BA_ "GatewayedSignals" SG_ 516 VCU_RecpTorqRAVD 0;
BA_ "GenSigInactiveValue" SG_ 516 VCU_RecpTorqRAVD 0;
BA_ "GenSigInvalidValue" SG_ 516 VCU_RecpTorqRAVD 0;
BA_ "GenSigSendType" SG_ 516 VCU_RecpTorqRAVD 1;
BA_ "GenSigStartValue" SG_ 516 VCU_RecpTorqRAVD 0;
BA_ "GenSigTimeoutValue" SG_ 516 VCU_RecpTorqRAVD 0;
BA_ "Remark" SG_ 516 VCU_RecpTorqRAVD "";
BA_ "EventCommandSignal" SG_ 516 VCU_MaxRecpTorqFAVD 0;
BA_ "GatewayedSignals" SG_ 516 VCU_MaxRecpTorqFAVD 0;
BA_ "GenSigInactiveValue" SG_ 516 VCU_MaxRecpTorqFAVD 0;
BA_ "GenSigInvalidValue" SG_ 516 VCU_MaxRecpTorqFAVD 0;
BA_ "GenSigSendType" SG_ 516 VCU_MaxRecpTorqFAVD 1;
BA_ "GenSigStartValue" SG_ 516 VCU_MaxRecpTorqFAVD 0;
BA_ "GenSigTimeoutValue" SG_ 516 VCU_MaxRecpTorqFAVD 0;
BA_ "Remark" SG_ 516 VCU_MaxRecpTorqFAVD "";
BA_ "EventCommandSignal" SG_ 516 VCU_MaxRecpTorqRAVD 0;
BA_ "GatewayedSignals" SG_ 516 VCU_MaxRecpTorqRAVD 0;
BA_ "GenSigInactiveValue" SG_ 516 VCU_MaxRecpTorqRAVD 0;
BA_ "GenSigInvalidValue" SG_ 516 VCU_MaxRecpTorqRAVD 0;
BA_ "GenSigSendType" SG_ 516 VCU_MaxRecpTorqRAVD 1;
BA_ "GenSigStartValue" SG_ 516 VCU_MaxRecpTorqRAVD 0;
BA_ "GenSigTimeoutValue" SG_ 516 VCU_MaxRecpTorqRAVD 0;
BA_ "Remark" SG_ 516 VCU_MaxRecpTorqRAVD "";
BA_ "EventCommandSignal" SG_ 516 VCU_RecpTorqNm 0;
BA_ "GatewayedSignals" SG_ 516 VCU_RecpTorqNm 0;
BA_ "GenSigInactiveValue" SG_ 516 VCU_RecpTorqNm 0;
BA_ "GenSigInvalidValue" SG_ 516 VCU_RecpTorqNm 0;
BA_ "GenSigSendType" SG_ 516 VCU_RecpTorqNm 1;
BA_ "GenSigStartValue" SG_ 516 VCU_RecpTorqNm 0;
BA_ "GenSigTimeoutValue" SG_ 516 VCU_RecpTorqNm 0;
BA_ "Remark" SG_ 516 VCU_RecpTorqNm "";
BA_ "EventCommandSignal" SG_ 516 VCU_APAWheelTorqDriverReqNm 0;
BA_ "GatewayedSignals" SG_ 516 VCU_APAWheelTorqDriverReqNm 0;
BA_ "GenSigInactiveValue" SG_ 516 VCU_APAWheelTorqDriverReqNm 0;
BA_ "GenSigInvalidValue" SG_ 516 VCU_APAWheelTorqDriverReqNm 32767;
BA_ "GenSigSendType" SG_ 516 VCU_APAWheelTorqDriverReqNm 1;
BA_ "GenSigStartValue" SG_ 516 VCU_APAWheelTorqDriverReqNm 32766;
BA_ "GenSigTimeoutValue" SG_ 516 VCU_APAWheelTorqDriverReqNm 0;
BA_ "Remark" SG_ 516 VCU_APAWheelTorqDriverReqNm "";
BA_ "EventCommandSignal" SG_ 516 VCU_ActVehWheelTorqNm 0;
BA_ "GatewayedSignals" SG_ 516 VCU_ActVehWheelTorqNm 0;
BA_ "GenSigInactiveValue" SG_ 516 VCU_ActVehWheelTorqNm 0;
BA_ "GenSigInvalidValue" SG_ 516 VCU_ActVehWheelTorqNm 32767;
BA_ "GenSigSendType" SG_ 516 VCU_ActVehWheelTorqNm 1;
BA_ "GenSigStartValue" SG_ 516 VCU_ActVehWheelTorqNm 32766;
BA_ "GenSigTimeoutValue" SG_ 516 VCU_ActVehWheelTorqNm 0;
BA_ "Remark" SG_ 516 VCU_ActVehWheelTorqNm "";
BA_ "EventCommandSignal" SG_ 516 VCU_VehWheelTorqMinNm 0;
BA_ "GatewayedSignals" SG_ 516 VCU_VehWheelTorqMinNm 0;
BA_ "GenSigInactiveValue" SG_ 516 VCU_VehWheelTorqMinNm 0;
BA_ "GenSigInvalidValue" SG_ 516 VCU_VehWheelTorqMinNm 32767;
BA_ "GenSigSendType" SG_ 516 VCU_VehWheelTorqMinNm 1;
BA_ "GenSigStartValue" SG_ 516 VCU_VehWheelTorqMinNm 32766;
BA_ "GenSigTimeoutValue" SG_ 516 VCU_VehWheelTorqMinNm 0;
BA_ "Remark" SG_ 516 VCU_VehWheelTorqMinNm "";
BA_ "EventCommandSignal" SG_ 516 VCU_VehWheelTorqMaxNm 0;
BA_ "GatewayedSignals" SG_ 516 VCU_VehWheelTorqMaxNm 0;
BA_ "GenSigInactiveValue" SG_ 516 VCU_VehWheelTorqMaxNm 0;
BA_ "GenSigInvalidValue" SG_ 516 VCU_VehWheelTorqMaxNm 32767;
BA_ "GenSigSendType" SG_ 516 VCU_VehWheelTorqMaxNm 1;
BA_ "GenSigStartValue" SG_ 516 VCU_VehWheelTorqMaxNm 32766;
BA_ "GenSigTimeoutValue" SG_ 516 VCU_VehWheelTorqMaxNm 0;
BA_ "Remark" SG_ 516 VCU_VehWheelTorqMaxNm "";
BA_ "EventCommandSignal" SG_ 516 VCU_RecpTorqFA 0;
BA_ "GatewayedSignals" SG_ 516 VCU_RecpTorqFA 0;
BA_ "GenSigInactiveValue" SG_ 516 VCU_RecpTorqFA 0;
BA_ "GenSigInvalidValue" SG_ 516 VCU_RecpTorqFA 0;
BA_ "GenSigSendType" SG_ 516 VCU_RecpTorqFA 1;
BA_ "GenSigStartValue" SG_ 516 VCU_RecpTorqFA 0;
BA_ "GenSigTimeoutValue" SG_ 516 VCU_RecpTorqFA 0;
BA_ "Remark" SG_ 516 VCU_RecpTorqFA "";
BA_ "EventCommandSignal" SG_ 516 VCU_RecpTorqRA 0;
BA_ "GatewayedSignals" SG_ 516 VCU_RecpTorqRA 0;
BA_ "GenSigInactiveValue" SG_ 516 VCU_RecpTorqRA 0;
BA_ "GenSigInvalidValue" SG_ 516 VCU_RecpTorqRA 0;
BA_ "GenSigSendType" SG_ 516 VCU_RecpTorqRA 1;
BA_ "GenSigStartValue" SG_ 516 VCU_RecpTorqRA 0;
BA_ "GenSigTimeoutValue" SG_ 516 VCU_RecpTorqRA 0;
BA_ "Remark" SG_ 516 VCU_RecpTorqRA "";
BA_ "EventCommandSignal" SG_ 516 VCU_MaxRecpTorqFA 0;
BA_ "GatewayedSignals" SG_ 516 VCU_MaxRecpTorqFA 0;
BA_ "GenSigInactiveValue" SG_ 516 VCU_MaxRecpTorqFA 0;
BA_ "GenSigInvalidValue" SG_ 516 VCU_MaxRecpTorqFA 0;
BA_ "GenSigSendType" SG_ 516 VCU_MaxRecpTorqFA 1;
BA_ "GenSigStartValue" SG_ 516 VCU_MaxRecpTorqFA 0;
BA_ "GenSigTimeoutValue" SG_ 516 VCU_MaxRecpTorqFA 0;
BA_ "Remark" SG_ 516 VCU_MaxRecpTorqFA "";
BA_ "EventCommandSignal" SG_ 516 VCU_MaxRecpTorqRA 0;
BA_ "GatewayedSignals" SG_ 516 VCU_MaxRecpTorqRA 0;
BA_ "GenSigInactiveValue" SG_ 516 VCU_MaxRecpTorqRA 0;
BA_ "GenSigInvalidValue" SG_ 516 VCU_MaxRecpTorqRA 0;
BA_ "GenSigSendType" SG_ 516 VCU_MaxRecpTorqRA 1;
BA_ "GenSigStartValue" SG_ 516 VCU_MaxRecpTorqRA 0;
BA_ "GenSigTimeoutValue" SG_ 516 VCU_MaxRecpTorqRA 0;
BA_ "Remark" SG_ 516 VCU_MaxRecpTorqRA "";
BA_ "EventCommandSignal" SG_ 516 VCU_BcsDecelEnable 0;
BA_ "GatewayedSignals" SG_ 516 VCU_BcsDecelEnable 0;
BA_ "GenSigInactiveValue" SG_ 516 VCU_BcsDecelEnable 0;
BA_ "GenSigInvalidValue" SG_ 516 VCU_BcsDecelEnable 0;
BA_ "GenSigSendType" SG_ 516 VCU_BcsDecelEnable 1;
BA_ "GenSigStartValue" SG_ 516 VCU_BcsDecelEnable 0;
BA_ "GenSigTimeoutValue" SG_ 516 VCU_BcsDecelEnable 0;
BA_ "Remark" SG_ 516 VCU_BcsDecelEnable "";
BA_ "EventCommandSignal" SG_ 516 VCU_CrntGearNoTrans 0;
BA_ "GatewayedSignals" SG_ 516 VCU_CrntGearNoTrans 0;
BA_ "GenSigInactiveValue" SG_ 516 VCU_CrntGearNoTrans 0;
BA_ "GenSigInvalidValue" SG_ 516 VCU_CrntGearNoTrans 0;
BA_ "GenSigSendType" SG_ 516 VCU_CrntGearNoTrans 1;
BA_ "GenSigStartValue" SG_ 516 VCU_CrntGearNoTrans 0;
BA_ "GenSigTimeoutValue" SG_ 516 VCU_CrntGearNoTrans 0;
BA_ "Remark" SG_ 516 VCU_CrntGearNoTrans "";
BA_ "EventCommandSignal" SG_ 516 VCU_EzTSt 0;
BA_ "GatewayedSignals" SG_ 516 VCU_EzTSt 0;
BA_ "GenSigInactiveValue" SG_ 516 VCU_EzTSt 0;
BA_ "GenSigInvalidValue" SG_ 516 VCU_EzTSt 0;
BA_ "GenSigSendType" SG_ 516 VCU_EzTSt 1;
BA_ "GenSigStartValue" SG_ 516 VCU_EzTSt 0;
BA_ "GenSigTimeoutValue" SG_ 516 VCU_EzTSt 0;
BA_ "Remark" SG_ 516 VCU_EzTSt "";
BA_ "EventCommandSignal" SG_ 516 VCU_ITASSt 0;
BA_ "GatewayedSignals" SG_ 516 VCU_ITASSt 0;
BA_ "GenSigInactiveValue" SG_ 516 VCU_ITASSt 0;
BA_ "GenSigInvalidValue" SG_ 516 VCU_ITASSt 0;
BA_ "GenSigSendType" SG_ 516 VCU_ITASSt 1;
BA_ "GenSigStartValue" SG_ 516 VCU_ITASSt 0;
BA_ "GenSigTimeoutValue" SG_ 516 VCU_ITASSt 0;
BA_ "Remark" SG_ 516 VCU_ITASSt "";
BA_ "EventCommandSignal" SG_ 616 CCU_1_CRC 0;
BA_ "GatewayedSignals" SG_ 616 CCU_1_CRC 0;
BA_ "GenSigInactiveValue" SG_ 616 CCU_1_CRC 0;
BA_ "GenSigInvalidValue" SG_ 616 CCU_1_CRC 0;
BA_ "GenSigSendType" SG_ 616 CCU_1_CRC 1;
BA_ "GenSigStartValue" SG_ 616 CCU_1_CRC 0;
BA_ "GenSigTimeoutValue" SG_ 616 CCU_1_CRC 0;
BA_ "Remark" SG_ 616 CCU_1_CRC "";
BA_ "EventCommandSignal" SG_ 616 CCU_1_Counter 0;
BA_ "GatewayedSignals" SG_ 616 CCU_1_Counter 0;
BA_ "GenSigInactiveValue" SG_ 616 CCU_1_Counter 0;
BA_ "GenSigInvalidValue" SG_ 616 CCU_1_Counter 0;
BA_ "GenSigSendType" SG_ 616 CCU_1_Counter 1;
BA_ "GenSigStartValue" SG_ 616 CCU_1_Counter 0;
BA_ "GenSigTimeoutValue" SG_ 616 CCU_1_Counter 0;
BA_ "Remark" SG_ 616 CCU_1_Counter "";
BA_ "EventCommandSignal" SG_ 616 UMM_UsageModeSt 0;
BA_ "GatewayedSignals" SG_ 616 UMM_UsageModeSt 0;
BA_ "GenSigInactiveValue" SG_ 616 UMM_UsageModeSt 0;
BA_ "GenSigInvalidValue" SG_ 616 UMM_UsageModeSt 0;
BA_ "GenSigSendType" SG_ 616 UMM_UsageModeSt 1;
BA_ "GenSigStartValue" SG_ 616 UMM_UsageModeSt 7;
BA_ "GenSigTimeoutValue" SG_ 616 UMM_UsageModeSt 0;
BA_ "Remark" SG_ 616 UMM_UsageModeSt "";
BA_ "EventCommandSignal" SG_ 616 OTA_FuncReq_ADCWakeup 0;
BA_ "GatewayedSignals" SG_ 616 OTA_FuncReq_ADCWakeup 0;
BA_ "GenSigInactiveValue" SG_ 616 OTA_FuncReq_ADCWakeup 0;
BA_ "GenSigInvalidValue" SG_ 616 OTA_FuncReq_ADCWakeup 0;
BA_ "GenSigSendType" SG_ 616 OTA_FuncReq_ADCWakeup 1;
BA_ "GenSigStartValue" SG_ 616 OTA_FuncReq_ADCWakeup 0;
BA_ "GenSigTimeoutValue" SG_ 616 OTA_FuncReq_ADCWakeup 0;
BA_ "Remark" SG_ 616 OTA_FuncReq_ADCWakeup "";
BA_ "EventCommandSignal" SG_ 616 UMM_FrontPassengerSeatSt 0;
BA_ "GatewayedSignals" SG_ 616 UMM_FrontPassengerSeatSt 0;
BA_ "GenSigInactiveValue" SG_ 616 UMM_FrontPassengerSeatSt 0;
BA_ "GenSigInvalidValue" SG_ 616 UMM_FrontPassengerSeatSt 0;
BA_ "GenSigSendType" SG_ 616 UMM_FrontPassengerSeatSt 1;
BA_ "GenSigStartValue" SG_ 616 UMM_FrontPassengerSeatSt 0;
BA_ "GenSigTimeoutValue" SG_ 616 UMM_FrontPassengerSeatSt 0;
BA_ "Remark" SG_ 616 UMM_FrontPassengerSeatSt "";
BA_ "EventCommandSignal" SG_ 616 UMM_DriverSeatSt 0;
BA_ "GatewayedSignals" SG_ 616 UMM_DriverSeatSt 0;
BA_ "GenSigInactiveValue" SG_ 616 UMM_DriverSeatSt 0;
BA_ "GenSigInvalidValue" SG_ 616 UMM_DriverSeatSt 0;
BA_ "GenSigSendType" SG_ 616 UMM_DriverSeatSt 1;
BA_ "GenSigStartValue" SG_ 616 UMM_DriverSeatSt 0;
BA_ "GenSigTimeoutValue" SG_ 616 UMM_DriverSeatSt 0;
BA_ "Remark" SG_ 616 UMM_DriverSeatSt "";
BA_ "EventCommandSignal" SG_ 616 VMM_VehModeSt 0;
BA_ "GatewayedSignals" SG_ 616 VMM_VehModeSt 0;
BA_ "GenSigInactiveValue" SG_ 616 VMM_VehModeSt 0;
BA_ "GenSigInvalidValue" SG_ 616 VMM_VehModeSt 15;
BA_ "GenSigSendType" SG_ 616 VMM_VehModeSt 1;
BA_ "GenSigStartValue" SG_ 616 VMM_VehModeSt 15;
BA_ "GenSigTimeoutValue" SG_ 616 VMM_VehModeSt 15;
BA_ "Remark" SG_ 616 VMM_VehModeSt "";
BA_ "EventCommandSignal" SG_ 616 VMM_LastVehModeSt 0;
BA_ "GatewayedSignals" SG_ 616 VMM_LastVehModeSt 0;
BA_ "GenSigInactiveValue" SG_ 616 VMM_LastVehModeSt 0;
BA_ "GenSigInvalidValue" SG_ 616 VMM_LastVehModeSt 15;
BA_ "GenSigSendType" SG_ 616 VMM_LastVehModeSt 1;
BA_ "GenSigStartValue" SG_ 616 VMM_LastVehModeSt 15;
BA_ "GenSigTimeoutValue" SG_ 616 VMM_LastVehModeSt 15;
BA_ "Remark" SG_ 616 VMM_LastVehModeSt "";
BA_ "EventCommandSignal" SG_ 616 VMM_OTAModeSt 0;
BA_ "GatewayedSignals" SG_ 616 VMM_OTAModeSt 0;
BA_ "GenSigInactiveValue" SG_ 616 VMM_OTAModeSt 0;
BA_ "GenSigInvalidValue" SG_ 616 VMM_OTAModeSt 2;
BA_ "GenSigSendType" SG_ 616 VMM_OTAModeSt 1;
BA_ "GenSigStartValue" SG_ 616 VMM_OTAModeSt 0;
BA_ "GenSigTimeoutValue" SG_ 616 VMM_OTAModeSt 0;
BA_ "Remark" SG_ 616 VMM_OTAModeSt "";
BA_ "EventCommandSignal" SG_ 616 CSM_RC_PAARequest 0;
BA_ "GatewayedSignals" SG_ 616 CSM_RC_PAARequest 0;
BA_ "GenSigInactiveValue" SG_ 616 CSM_RC_PAARequest 0;
BA_ "GenSigInvalidValue" SG_ 616 CSM_RC_PAARequest 0;
BA_ "GenSigSendType" SG_ 616 CSM_RC_PAARequest 1;
BA_ "GenSigStartValue" SG_ 616 CSM_RC_PAARequest 0;
BA_ "GenSigTimeoutValue" SG_ 616 CSM_RC_PAARequest 0;
BA_ "Remark" SG_ 616 CSM_RC_PAARequest "";
BA_ "EventCommandSignal" SG_ 616 CSM_RC_AuthSt 0;
BA_ "GatewayedSignals" SG_ 616 CSM_RC_AuthSt 0;
BA_ "GenSigInactiveValue" SG_ 616 CSM_RC_AuthSt 0;
BA_ "GenSigInvalidValue" SG_ 616 CSM_RC_AuthSt 0;
BA_ "GenSigSendType" SG_ 616 CSM_RC_AuthSt 1;
BA_ "GenSigStartValue" SG_ 616 CSM_RC_AuthSt 0;
BA_ "GenSigTimeoutValue" SG_ 616 CSM_RC_AuthSt 0;
BA_ "Remark" SG_ 616 CSM_RC_AuthSt "";
BA_ "EventCommandSignal" SG_ 616 IPDS_EnablePowerSup 0;
BA_ "GatewayedSignals" SG_ 616 IPDS_EnablePowerSup 0;
BA_ "GenSigInactiveValue" SG_ 616 IPDS_EnablePowerSup 0;
BA_ "GenSigInvalidValue" SG_ 616 IPDS_EnablePowerSup 0;
BA_ "GenSigSendType" SG_ 616 IPDS_EnablePowerSup 1;
BA_ "GenSigStartValue" SG_ 616 IPDS_EnablePowerSup 0;
BA_ "GenSigTimeoutValue" SG_ 616 IPDS_EnablePowerSup 0;
BA_ "Remark" SG_ 616 IPDS_EnablePowerSup "";
BA_ "EventCommandSignal" SG_ 616 Time_Year 0;
BA_ "GatewayedSignals" SG_ 616 Time_Year 0;
BA_ "GenSigInactiveValue" SG_ 616 Time_Year 0;
BA_ "GenSigInvalidValue" SG_ 616 Time_Year 0;
BA_ "GenSigSendType" SG_ 616 Time_Year 1;
BA_ "GenSigStartValue" SG_ 616 Time_Year 0;
BA_ "GenSigTimeoutValue" SG_ 616 Time_Year 0;
BA_ "Remark" SG_ 616 Time_Year "";
BA_ "EventCommandSignal" SG_ 616 Time_Month 0;
BA_ "GatewayedSignals" SG_ 616 Time_Month 0;
BA_ "GenSigInactiveValue" SG_ 616 Time_Month 0;
BA_ "GenSigInvalidValue" SG_ 616 Time_Month 0;
BA_ "GenSigSendType" SG_ 616 Time_Month 1;
BA_ "GenSigStartValue" SG_ 616 Time_Month 0;
BA_ "GenSigTimeoutValue" SG_ 616 Time_Month 0;
BA_ "Remark" SG_ 616 Time_Month "";
BA_ "EventCommandSignal" SG_ 616 Time_Day 0;
BA_ "GatewayedSignals" SG_ 616 Time_Day 0;
BA_ "GenSigInactiveValue" SG_ 616 Time_Day 0;
BA_ "GenSigInvalidValue" SG_ 616 Time_Day 0;
BA_ "GenSigSendType" SG_ 616 Time_Day 1;
BA_ "GenSigStartValue" SG_ 616 Time_Day 1;
BA_ "GenSigTimeoutValue" SG_ 616 Time_Day 0;
BA_ "Remark" SG_ 616 Time_Day "";
BA_ "EventCommandSignal" SG_ 616 Time_Hour 0;
BA_ "GatewayedSignals" SG_ 616 Time_Hour 0;
BA_ "GenSigInactiveValue" SG_ 616 Time_Hour 0;
BA_ "GenSigInvalidValue" SG_ 616 Time_Hour 0;
BA_ "GenSigSendType" SG_ 616 Time_Hour 1;
BA_ "GenSigStartValue" SG_ 616 Time_Hour 1;
BA_ "GenSigTimeoutValue" SG_ 616 Time_Hour 0;
BA_ "Remark" SG_ 616 Time_Hour "";
BA_ "EventCommandSignal" SG_ 616 Time_Min 0;
BA_ "GatewayedSignals" SG_ 616 Time_Min 0;
BA_ "GenSigInactiveValue" SG_ 616 Time_Min 0;
BA_ "GenSigInvalidValue" SG_ 616 Time_Min 0;
BA_ "GenSigSendType" SG_ 616 Time_Min 1;
BA_ "GenSigStartValue" SG_ 616 Time_Min 1;
BA_ "GenSigTimeoutValue" SG_ 616 Time_Min 0;
BA_ "Remark" SG_ 616 Time_Min "";
BA_ "EventCommandSignal" SG_ 616 Time_Sec 0;
BA_ "GatewayedSignals" SG_ 616 Time_Sec 0;
BA_ "GenSigInactiveValue" SG_ 616 Time_Sec 0;
BA_ "GenSigInvalidValue" SG_ 616 Time_Sec 0;
BA_ "GenSigSendType" SG_ 616 Time_Sec 1;
BA_ "GenSigStartValue" SG_ 616 Time_Sec 1;
BA_ "GenSigTimeoutValue" SG_ 616 Time_Sec 0;
BA_ "Remark" SG_ 616 Time_Sec "";
BA_ "EventCommandSignal" SG_ 616 CCU_DstFlag 0;
BA_ "GatewayedSignals" SG_ 616 CCU_DstFlag 0;
BA_ "GenSigInactiveValue" SG_ 616 CCU_DstFlag 0;
BA_ "GenSigInvalidValue" SG_ 616 CCU_DstFlag 0;
BA_ "GenSigSendType" SG_ 616 CCU_DstFlag 1;
BA_ "GenSigStartValue" SG_ 616 CCU_DstFlag 0;
BA_ "GenSigTimeoutValue" SG_ 616 CCU_DstFlag 0;
BA_ "Remark" SG_ 616 CCU_DstFlag "";
BA_ "EventCommandSignal" SG_ 616 ASB_DriverActiveBeltFaultSt 0;
BA_ "GatewayedSignals" SG_ 616 ASB_DriverActiveBeltFaultSt 0;
BA_ "GenSigInactiveValue" SG_ 616 ASB_DriverActiveBeltFaultSt 0;
BA_ "GenSigInvalidValue" SG_ 616 ASB_DriverActiveBeltFaultSt 0;
BA_ "GenSigSendType" SG_ 616 ASB_DriverActiveBeltFaultSt 0;
BA_ "GenSigStartValue" SG_ 616 ASB_DriverActiveBeltFaultSt 0;
BA_ "GenSigTimeoutValue" SG_ 616 ASB_DriverActiveBeltFaultSt 1;
BA_ "Remark" SG_ 616 ASB_DriverActiveBeltFaultSt "";
BA_ "EventCommandSignal" SG_ 432 ICC_1_CRC 0;
BA_ "GatewayedSignals" SG_ 432 ICC_1_CRC 0;
BA_ "GenSigInactiveValue" SG_ 432 ICC_1_CRC 0;
BA_ "GenSigInvalidValue" SG_ 432 ICC_1_CRC 0;
BA_ "GenSigSendType" SG_ 432 ICC_1_CRC 1;
BA_ "GenSigStartValue" SG_ 432 ICC_1_CRC 0;
BA_ "GenSigTimeoutValue" SG_ 432 ICC_1_CRC 0;
BA_ "Remark" SG_ 432 ICC_1_CRC "";
BA_ "EventCommandSignal" SG_ 432 ICC_1_Counter 0;
BA_ "GatewayedSignals" SG_ 432 ICC_1_Counter 0;
BA_ "GenSigInactiveValue" SG_ 432 ICC_1_Counter 0;
BA_ "GenSigInvalidValue" SG_ 432 ICC_1_Counter 0;
BA_ "GenSigSendType" SG_ 432 ICC_1_Counter 1;
BA_ "GenSigStartValue" SG_ 432 ICC_1_Counter 0;
BA_ "GenSigTimeoutValue" SG_ 432 ICC_1_Counter 0;
BA_ "Remark" SG_ 432 ICC_1_Counter "";
BA_ "EventCommandSignal" SG_ 432 ICC_FcnInfo 0;
BA_ "GatewayedSignals" SG_ 432 ICC_FcnInfo 0;
BA_ "GenSigInactiveValue" SG_ 432 ICC_FcnInfo 0;
BA_ "GenSigInvalidValue" SG_ 432 ICC_FcnInfo 0;
BA_ "GenSigSendType" SG_ 432 ICC_FcnInfo 1;
BA_ "GenSigStartValue" SG_ 432 ICC_FcnInfo 0;
BA_ "GenSigTimeoutValue" SG_ 432 ICC_FcnInfo 0;
BA_ "Remark" SG_ 432 ICC_FcnInfo "";
BA_ "EventCommandSignal" SG_ 432 ICC_FaultSt 0;
BA_ "GatewayedSignals" SG_ 432 ICC_FaultSt 0;
BA_ "GenSigInactiveValue" SG_ 432 ICC_FaultSt 0;
BA_ "GenSigInvalidValue" SG_ 432 ICC_FaultSt 0;
BA_ "GenSigSendType" SG_ 432 ICC_FaultSt 1;
BA_ "GenSigStartValue" SG_ 432 ICC_FaultSt 0;
BA_ "GenSigTimeoutValue" SG_ 432 ICC_FaultSt 0;
BA_ "Remark" SG_ 432 ICC_FaultSt "";
BA_ "EventCommandSignal" SG_ 432 ICC_ActorSt 0;
BA_ "GatewayedSignals" SG_ 432 ICC_ActorSt 0;
BA_ "GenSigInactiveValue" SG_ 432 ICC_ActorSt 0;
BA_ "GenSigInvalidValue" SG_ 432 ICC_ActorSt 0;
BA_ "GenSigSendType" SG_ 432 ICC_ActorSt 1;
BA_ "GenSigStartValue" SG_ 432 ICC_ActorSt 0;
BA_ "GenSigTimeoutValue" SG_ 432 ICC_ActorSt 0;
BA_ "Remark" SG_ 432 ICC_ActorSt "";
BA_ "EventCommandSignal" SG_ 432 ICC_RAS_AgCtrlAvl 0;
BA_ "GatewayedSignals" SG_ 432 ICC_RAS_AgCtrlAvl 0;
BA_ "GenSigInactiveValue" SG_ 432 ICC_RAS_AgCtrlAvl 0;
BA_ "GenSigInvalidValue" SG_ 432 ICC_RAS_AgCtrlAvl 0;
BA_ "GenSigSendType" SG_ 432 ICC_RAS_AgCtrlAvl 1;
BA_ "GenSigStartValue" SG_ 432 ICC_RAS_AgCtrlAvl 0;
BA_ "GenSigTimeoutValue" SG_ 432 ICC_RAS_AgCtrlAvl 0;
BA_ "Remark" SG_ 432 ICC_RAS_AgCtrlAvl "";
BA_ "EventCommandSignal" SG_ 432 ICC_RAS_CalibratedSt 0;
BA_ "GatewayedSignals" SG_ 432 ICC_RAS_CalibratedSt 0;
BA_ "GenSigInactiveValue" SG_ 432 ICC_RAS_CalibratedSt 0;
BA_ "GenSigInvalidValue" SG_ 432 ICC_RAS_CalibratedSt 0;
BA_ "GenSigSendType" SG_ 432 ICC_RAS_CalibratedSt 1;
BA_ "GenSigStartValue" SG_ 432 ICC_RAS_CalibratedSt 1;
BA_ "GenSigTimeoutValue" SG_ 432 ICC_RAS_CalibratedSt 0;
BA_ "Remark" SG_ 432 ICC_RAS_CalibratedSt "";
BA_ "EventCommandSignal" SG_ 432 ICC_RAS_ErrFeedback 0;
BA_ "GatewayedSignals" SG_ 432 ICC_RAS_ErrFeedback 0;
BA_ "GenSigInactiveValue" SG_ 432 ICC_RAS_ErrFeedback 0;
BA_ "GenSigInvalidValue" SG_ 432 ICC_RAS_ErrFeedback 0;
BA_ "GenSigSendType" SG_ 432 ICC_RAS_ErrFeedback 1;
BA_ "GenSigStartValue" SG_ 432 ICC_RAS_ErrFeedback 0;
BA_ "GenSigTimeoutValue" SG_ 432 ICC_RAS_ErrFeedback 0;
BA_ "Remark" SG_ 432 ICC_RAS_ErrFeedback "";
BA_ "EventCommandSignal" SG_ 432 ICC_RAS_AngleVD 0;
BA_ "GatewayedSignals" SG_ 432 ICC_RAS_AngleVD 0;
BA_ "GenSigInactiveValue" SG_ 432 ICC_RAS_AngleVD 0;
BA_ "GenSigInvalidValue" SG_ 432 ICC_RAS_AngleVD 0;
BA_ "GenSigSendType" SG_ 432 ICC_RAS_AngleVD 1;
BA_ "GenSigStartValue" SG_ 432 ICC_RAS_AngleVD 1;
BA_ "GenSigTimeoutValue" SG_ 432 ICC_RAS_AngleVD 0;
BA_ "Remark" SG_ 432 ICC_RAS_AngleVD "";
BA_ "EventCommandSignal" SG_ 432 ICC_RAS_PstOverlaySt 0;
BA_ "GatewayedSignals" SG_ 432 ICC_RAS_PstOverlaySt 0;
BA_ "GenSigInactiveValue" SG_ 432 ICC_RAS_PstOverlaySt 0;
BA_ "GenSigInvalidValue" SG_ 432 ICC_RAS_PstOverlaySt 0;
BA_ "GenSigSendType" SG_ 432 ICC_RAS_PstOverlaySt 1;
BA_ "GenSigStartValue" SG_ 432 ICC_RAS_PstOverlaySt 0;
BA_ "GenSigTimeoutValue" SG_ 432 ICC_RAS_PstOverlaySt 0;
BA_ "Remark" SG_ 432 ICC_RAS_PstOverlaySt "";
BA_ "EventCommandSignal" SG_ 432 ICC_RAS_SteerMod 0;
BA_ "GatewayedSignals" SG_ 432 ICC_RAS_SteerMod 0;
BA_ "GenSigInactiveValue" SG_ 432 ICC_RAS_SteerMod 0;
BA_ "GenSigInvalidValue" SG_ 432 ICC_RAS_SteerMod 0;
BA_ "GenSigSendType" SG_ 432 ICC_RAS_SteerMod 1;
BA_ "GenSigStartValue" SG_ 432 ICC_RAS_SteerMod 1;
BA_ "GenSigTimeoutValue" SG_ 432 ICC_RAS_SteerMod 1;
BA_ "Remark" SG_ 432 ICC_RAS_SteerMod "";
BA_ "EventCommandSignal" SG_ 432 ICC_RAS_SteeringAngle 0;
BA_ "GatewayedSignals" SG_ 432 ICC_RAS_SteeringAngle 0;
BA_ "GenSigInactiveValue" SG_ 432 ICC_RAS_SteeringAngle 0;
BA_ "GenSigInvalidValue" SG_ 432 ICC_RAS_SteeringAngle 0;
BA_ "GenSigSendType" SG_ 432 ICC_RAS_SteeringAngle 1;
BA_ "GenSigStartValue" SG_ 432 ICC_RAS_SteeringAngle 1023;
BA_ "GenSigTimeoutValue" SG_ 432 ICC_RAS_SteeringAngle 1023;
BA_ "Remark" SG_ 432 ICC_RAS_SteeringAngle "";
BA_ "EventCommandSignal" SG_ 432 ICC_RAS_HealthyStForADC 0;
BA_ "GatewayedSignals" SG_ 432 ICC_RAS_HealthyStForADC 0;
BA_ "GenSigInactiveValue" SG_ 432 ICC_RAS_HealthyStForADC 0;
BA_ "GenSigInvalidValue" SG_ 432 ICC_RAS_HealthyStForADC 0;
BA_ "GenSigSendType" SG_ 432 ICC_RAS_HealthyStForADC 1;
BA_ "GenSigStartValue" SG_ 432 ICC_RAS_HealthyStForADC 0;
BA_ "GenSigTimeoutValue" SG_ 432 ICC_RAS_HealthyStForADC 0;
BA_ "Remark" SG_ 432 ICC_RAS_HealthyStForADC "";
BA_ "EventCommandSignal" SG_ 432 ICC_RAS_SteeringAngleSpdVD 0;
BA_ "GatewayedSignals" SG_ 432 ICC_RAS_SteeringAngleSpdVD 0;
BA_ "GenSigInactiveValue" SG_ 432 ICC_RAS_SteeringAngleSpdVD 0;
BA_ "GenSigInvalidValue" SG_ 432 ICC_RAS_SteeringAngleSpdVD 0;
BA_ "GenSigSendType" SG_ 432 ICC_RAS_SteeringAngleSpdVD 1;
BA_ "GenSigStartValue" SG_ 432 ICC_RAS_SteeringAngleSpdVD 1;
BA_ "GenSigTimeoutValue" SG_ 432 ICC_RAS_SteeringAngleSpdVD 1;
BA_ "Remark" SG_ 432 ICC_RAS_SteeringAngleSpdVD "";
BA_ "EventCommandSignal" SG_ 432 ICC_RAS_ThermalSt 0;
BA_ "GatewayedSignals" SG_ 432 ICC_RAS_ThermalSt 0;
BA_ "GenSigInactiveValue" SG_ 432 ICC_RAS_ThermalSt 0;
BA_ "GenSigInvalidValue" SG_ 432 ICC_RAS_ThermalSt 0;
BA_ "GenSigSendType" SG_ 432 ICC_RAS_ThermalSt 1;
BA_ "GenSigStartValue" SG_ 432 ICC_RAS_ThermalSt 0;
BA_ "GenSigTimeoutValue" SG_ 432 ICC_RAS_ThermalSt 0;
BA_ "Remark" SG_ 432 ICC_RAS_ThermalSt "";
BA_ "EventCommandSignal" SG_ 432 ICC_RAS_SteeringAngleRate 0;
BA_ "GatewayedSignals" SG_ 432 ICC_RAS_SteeringAngleRate 0;
BA_ "GenSigInactiveValue" SG_ 432 ICC_RAS_SteeringAngleRate 0;
BA_ "GenSigInvalidValue" SG_ 432 ICC_RAS_SteeringAngleRate 0;
BA_ "GenSigSendType" SG_ 432 ICC_RAS_SteeringAngleRate 1;
BA_ "GenSigStartValue" SG_ 432 ICC_RAS_SteeringAngleRate 2252;
BA_ "GenSigTimeoutValue" SG_ 432 ICC_RAS_SteeringAngleRate 2252;
BA_ "Remark" SG_ 432 ICC_RAS_SteeringAngleRate "";
BA_ "EventCommandSignal" SG_ 432 ICC_RAS_WarnLamp 0;
BA_ "GatewayedSignals" SG_ 432 ICC_RAS_WarnLamp 0;
BA_ "GenSigInactiveValue" SG_ 432 ICC_RAS_WarnLamp 0;
BA_ "GenSigInvalidValue" SG_ 432 ICC_RAS_WarnLamp 0;
BA_ "GenSigSendType" SG_ 432 ICC_RAS_WarnLamp 1;
BA_ "GenSigStartValue" SG_ 432 ICC_RAS_WarnLamp 0;
BA_ "GenSigTimeoutValue" SG_ 432 ICC_RAS_WarnLamp 0;
BA_ "Remark" SG_ 432 ICC_RAS_WarnLamp "";
BA_ "EventCommandSignal" SG_ 432 ICC_RAS_MotorTorActMot 0;
BA_ "GatewayedSignals" SG_ 432 ICC_RAS_MotorTorActMot 0;
BA_ "GenSigInactiveValue" SG_ 432 ICC_RAS_MotorTorActMot 0;
BA_ "GenSigInvalidValue" SG_ 432 ICC_RAS_MotorTorActMot 4095;
BA_ "GenSigSendType" SG_ 432 ICC_RAS_MotorTorActMot 1;
BA_ "GenSigStartValue" SG_ 432 ICC_RAS_MotorTorActMot 1500;
BA_ "GenSigTimeoutValue" SG_ 432 ICC_RAS_MotorTorActMot 4095;
BA_ "Remark" SG_ 432 ICC_RAS_MotorTorActMot "";
BA_ "EventCommandSignal" SG_ 432 ICC_RAS_ADASTargetAngle 0;
BA_ "GatewayedSignals" SG_ 432 ICC_RAS_ADASTargetAngle 0;
BA_ "GenSigInactiveValue" SG_ 432 ICC_RAS_ADASTargetAngle 0;
BA_ "GenSigInvalidValue" SG_ 432 ICC_RAS_ADASTargetAngle 0;
BA_ "GenSigSendType" SG_ 432 ICC_RAS_ADASTargetAngle 1;
BA_ "GenSigStartValue" SG_ 432 ICC_RAS_ADASTargetAngle 1023;
BA_ "GenSigTimeoutValue" SG_ 432 ICC_RAS_ADASTargetAngle 1023;
BA_ "Remark" SG_ 432 ICC_RAS_ADASTargetAngle "";
BA_ "EventCommandSignal" SG_ 1359 CCU_NMNodeAddress 0;
BA_ "GatewayedSignals" SG_ 1359 CCU_NMNodeAddress 0;
BA_ "GenSigInactiveValue" SG_ 1359 CCU_NMNodeAddress 0;
BA_ "GenSigInvalidValue" SG_ 1359 CCU_NMNodeAddress 0;
BA_ "GenSigSendType" SG_ 1359 CCU_NMNodeAddress 1;
BA_ "GenSigStartValue" SG_ 1359 CCU_NMNodeAddress 79;
BA_ "GenSigTimeoutValue" SG_ 1359 CCU_NMNodeAddress 0;
BA_ "Remark" SG_ 1359 CCU_NMNodeAddress "";
BA_ "EventCommandSignal" SG_ 1359 CCU_NMCBV 0;
BA_ "GatewayedSignals" SG_ 1359 CCU_NMCBV 0;
BA_ "GenSigInactiveValue" SG_ 1359 CCU_NMCBV 0;
BA_ "GenSigInvalidValue" SG_ 1359 CCU_NMCBV 0;
BA_ "GenSigSendType" SG_ 1359 CCU_NMCBV 1;
BA_ "GenSigStartValue" SG_ 1359 CCU_NMCBV 0;
BA_ "GenSigTimeoutValue" SG_ 1359 CCU_NMCBV 0;
BA_ "Remark" SG_ 1359 CCU_NMCBV "";
BA_ "EventCommandSignal" SG_ 1359 CCU_NMWakeupOrigin 0;
BA_ "GatewayedSignals" SG_ 1359 CCU_NMWakeupOrigin 0;
BA_ "GenSigInactiveValue" SG_ 1359 CCU_NMWakeupOrigin 0;
BA_ "GenSigInvalidValue" SG_ 1359 CCU_NMWakeupOrigin 0;
BA_ "GenSigSendType" SG_ 1359 CCU_NMWakeupOrigin 1;
BA_ "GenSigStartValue" SG_ 1359 CCU_NMWakeupOrigin 0;
BA_ "GenSigTimeoutValue" SG_ 1359 CCU_NMWakeupOrigin 0;
BA_ "Remark" SG_ 1359 CCU_NMWakeupOrigin "";
BA_ "EventCommandSignal" SG_ 1359 CCU_PNCInformation0 0;
BA_ "GatewayedSignals" SG_ 1359 CCU_PNCInformation0 0;
BA_ "GenSigInactiveValue" SG_ 1359 CCU_PNCInformation0 0;
BA_ "GenSigInvalidValue" SG_ 1359 CCU_PNCInformation0 0;
BA_ "GenSigSendType" SG_ 1359 CCU_PNCInformation0 1;
BA_ "GenSigStartValue" SG_ 1359 CCU_PNCInformation0 0;
BA_ "GenSigTimeoutValue" SG_ 1359 CCU_PNCInformation0 0;
BA_ "Remark" SG_ 1359 CCU_PNCInformation0 "";
BA_ "EventCommandSignal" SG_ 1359 CCU_PNCInformation1 0;
BA_ "GatewayedSignals" SG_ 1359 CCU_PNCInformation1 0;
BA_ "GenSigInactiveValue" SG_ 1359 CCU_PNCInformation1 0;
BA_ "GenSigInvalidValue" SG_ 1359 CCU_PNCInformation1 0;
BA_ "GenSigSendType" SG_ 1359 CCU_PNCInformation1 1;
BA_ "GenSigStartValue" SG_ 1359 CCU_PNCInformation1 0;
BA_ "GenSigTimeoutValue" SG_ 1359 CCU_PNCInformation1 0;
BA_ "Remark" SG_ 1359 CCU_PNCInformation1 "";
BA_ "EventCommandSignal" SG_ 1359 CCU_PNCInformation2 0;
BA_ "GatewayedSignals" SG_ 1359 CCU_PNCInformation2 0;
BA_ "GenSigInactiveValue" SG_ 1359 CCU_PNCInformation2 0;
BA_ "GenSigInvalidValue" SG_ 1359 CCU_PNCInformation2 0;
BA_ "GenSigSendType" SG_ 1359 CCU_PNCInformation2 1;
BA_ "GenSigStartValue" SG_ 1359 CCU_PNCInformation2 0;
BA_ "GenSigTimeoutValue" SG_ 1359 CCU_PNCInformation2 0;
BA_ "Remark" SG_ 1359 CCU_PNCInformation2 "";
BA_ "EventCommandSignal" SG_ 359 BCS_1_B_CRC 0;
BA_ "GatewayedSignals" SG_ 359 BCS_1_B_CRC 0;
BA_ "GenSigInactiveValue" SG_ 359 BCS_1_B_CRC 0;
BA_ "GenSigInvalidValue" SG_ 359 BCS_1_B_CRC 0;
BA_ "GenSigSendType" SG_ 359 BCS_1_B_CRC 1;
BA_ "GenSigStartValue" SG_ 359 BCS_1_B_CRC 0;
BA_ "GenSigTimeoutValue" SG_ 359 BCS_1_B_CRC 0;
BA_ "Remark" SG_ 359 BCS_1_B_CRC "";
BA_ "EventCommandSignal" SG_ 359 BCS_1_B_Counter 0;
BA_ "GatewayedSignals" SG_ 359 BCS_1_B_Counter 0;
BA_ "GenSigInactiveValue" SG_ 359 BCS_1_B_Counter 0;
BA_ "GenSigInvalidValue" SG_ 359 BCS_1_B_Counter 0;
BA_ "GenSigSendType" SG_ 359 BCS_1_B_Counter 1;
BA_ "GenSigStartValue" SG_ 359 BCS_1_B_Counter 0;
BA_ "GenSigTimeoutValue" SG_ 359 BCS_1_B_Counter 0;
BA_ "Remark" SG_ 359 BCS_1_B_Counter "";
BA_ "EventCommandSignal" SG_ 359 BCS_FLWheelSpd_B 0;
BA_ "GatewayedSignals" SG_ 359 BCS_FLWheelSpd_B 0;
BA_ "GenSigInactiveValue" SG_ 359 BCS_FLWheelSpd_B 0;
BA_ "GenSigInvalidValue" SG_ 359 BCS_FLWheelSpd_B 0;
BA_ "GenSigSendType" SG_ 359 BCS_FLWheelSpd_B 1;
BA_ "GenSigStartValue" SG_ 359 BCS_FLWheelSpd_B 0;
BA_ "GenSigTimeoutValue" SG_ 359 BCS_FLWheelSpd_B 0;
BA_ "Remark" SG_ 359 BCS_FLWheelSpd_B "";
BA_ "EventCommandSignal" SG_ 359 BCS_FLWheelSpdVD_B 0;
BA_ "GatewayedSignals" SG_ 359 BCS_FLWheelSpdVD_B 0;
BA_ "GenSigInactiveValue" SG_ 359 BCS_FLWheelSpdVD_B 0;
BA_ "GenSigInvalidValue" SG_ 359 BCS_FLWheelSpdVD_B 0;
BA_ "GenSigSendType" SG_ 359 BCS_FLWheelSpdVD_B 1;
BA_ "GenSigStartValue" SG_ 359 BCS_FLWheelSpdVD_B 0;
BA_ "GenSigTimeoutValue" SG_ 359 BCS_FLWheelSpdVD_B 0;
BA_ "Remark" SG_ 359 BCS_FLWheelSpdVD_B "";
BA_ "EventCommandSignal" SG_ 359 BCS_FLWheelRotatedDirection_B 0;
BA_ "GatewayedSignals" SG_ 359 BCS_FLWheelRotatedDirection_B 0;
BA_ "GenSigInactiveValue" SG_ 359 BCS_FLWheelRotatedDirection_B 0;
BA_ "GenSigInvalidValue" SG_ 359 BCS_FLWheelRotatedDirection_B 0;
BA_ "GenSigSendType" SG_ 359 BCS_FLWheelRotatedDirection_B 1;
BA_ "GenSigStartValue" SG_ 359 BCS_FLWheelRotatedDirection_B 0;
BA_ "GenSigTimeoutValue" SG_ 359 BCS_FLWheelRotatedDirection_B 0;
BA_ "Remark" SG_ 359 BCS_FLWheelRotatedDirection_B "";
BA_ "EventCommandSignal" SG_ 359 BCS_FLWheelRotatedDirectionVD_B 0;
BA_ "GatewayedSignals" SG_ 359 BCS_FLWheelRotatedDirectionVD_B 0;
BA_ "GenSigInactiveValue" SG_ 359 BCS_FLWheelRotatedDirectionVD_B 0;
BA_ "GenSigInvalidValue" SG_ 359 BCS_FLWheelRotatedDirectionVD_B 0;
BA_ "GenSigSendType" SG_ 359 BCS_FLWheelRotatedDirectionVD_B 1;
BA_ "GenSigStartValue" SG_ 359 BCS_FLWheelRotatedDirectionVD_B 0;
BA_ "GenSigTimeoutValue" SG_ 359 BCS_FLWheelRotatedDirectionVD_B 0;
BA_ "Remark" SG_ 359 BCS_FLWheelRotatedDirectionVD_B "";
BA_ "EventCommandSignal" SG_ 359 BCS_FRWheelSpd_B 0;
BA_ "GatewayedSignals" SG_ 359 BCS_FRWheelSpd_B 0;
BA_ "GenSigInactiveValue" SG_ 359 BCS_FRWheelSpd_B 0;
BA_ "GenSigInvalidValue" SG_ 359 BCS_FRWheelSpd_B 0;
BA_ "GenSigSendType" SG_ 359 BCS_FRWheelSpd_B 1;
BA_ "GenSigStartValue" SG_ 359 BCS_FRWheelSpd_B 0;
BA_ "GenSigTimeoutValue" SG_ 359 BCS_FRWheelSpd_B 0;
BA_ "Remark" SG_ 359 BCS_FRWheelSpd_B "";
BA_ "EventCommandSignal" SG_ 359 BCS_FRWheelSpdVD_B 0;
BA_ "GatewayedSignals" SG_ 359 BCS_FRWheelSpdVD_B 0;
BA_ "GenSigInactiveValue" SG_ 359 BCS_FRWheelSpdVD_B 0;
BA_ "GenSigInvalidValue" SG_ 359 BCS_FRWheelSpdVD_B 0;
BA_ "GenSigSendType" SG_ 359 BCS_FRWheelSpdVD_B 1;
BA_ "GenSigStartValue" SG_ 359 BCS_FRWheelSpdVD_B 0;
BA_ "GenSigTimeoutValue" SG_ 359 BCS_FRWheelSpdVD_B 0;
BA_ "Remark" SG_ 359 BCS_FRWheelSpdVD_B "";
BA_ "EventCommandSignal" SG_ 359 BCS_FRWheelRotatedDirection_B 0;
BA_ "GatewayedSignals" SG_ 359 BCS_FRWheelRotatedDirection_B 0;
BA_ "GenSigInactiveValue" SG_ 359 BCS_FRWheelRotatedDirection_B 0;
BA_ "GenSigInvalidValue" SG_ 359 BCS_FRWheelRotatedDirection_B 0;
BA_ "GenSigSendType" SG_ 359 BCS_FRWheelRotatedDirection_B 1;
BA_ "GenSigStartValue" SG_ 359 BCS_FRWheelRotatedDirection_B 0;
BA_ "GenSigTimeoutValue" SG_ 359 BCS_FRWheelRotatedDirection_B 0;
BA_ "Remark" SG_ 359 BCS_FRWheelRotatedDirection_B "";
BA_ "EventCommandSignal" SG_ 359 BCS_FRWheelRotatedDirectionVD_B 0;
BA_ "GatewayedSignals" SG_ 359 BCS_FRWheelRotatedDirectionVD_B 0;
BA_ "GenSigInactiveValue" SG_ 359 BCS_FRWheelRotatedDirectionVD_B 0;
BA_ "GenSigInvalidValue" SG_ 359 BCS_FRWheelRotatedDirectionVD_B 0;
BA_ "GenSigSendType" SG_ 359 BCS_FRWheelRotatedDirectionVD_B 1;
BA_ "GenSigStartValue" SG_ 359 BCS_FRWheelRotatedDirectionVD_B 0;
BA_ "GenSigTimeoutValue" SG_ 359 BCS_FRWheelRotatedDirectionVD_B 0;
BA_ "Remark" SG_ 359 BCS_FRWheelRotatedDirectionVD_B "";
BA_ "EventCommandSignal" SG_ 359 BCS_RLWheelSpd_B 0;
BA_ "GatewayedSignals" SG_ 359 BCS_RLWheelSpd_B 0;
BA_ "GenSigInactiveValue" SG_ 359 BCS_RLWheelSpd_B 0;
BA_ "GenSigInvalidValue" SG_ 359 BCS_RLWheelSpd_B 0;
BA_ "GenSigSendType" SG_ 359 BCS_RLWheelSpd_B 1;
BA_ "GenSigStartValue" SG_ 359 BCS_RLWheelSpd_B 0;
BA_ "GenSigTimeoutValue" SG_ 359 BCS_RLWheelSpd_B 0;
BA_ "Remark" SG_ 359 BCS_RLWheelSpd_B "";
BA_ "EventCommandSignal" SG_ 359 BCS_RLWheelSpdVD_B 0;
BA_ "GatewayedSignals" SG_ 359 BCS_RLWheelSpdVD_B 0;
BA_ "GenSigInactiveValue" SG_ 359 BCS_RLWheelSpdVD_B 0;
BA_ "GenSigInvalidValue" SG_ 359 BCS_RLWheelSpdVD_B 0;
BA_ "GenSigSendType" SG_ 359 BCS_RLWheelSpdVD_B 1;
BA_ "GenSigStartValue" SG_ 359 BCS_RLWheelSpdVD_B 0;
BA_ "GenSigTimeoutValue" SG_ 359 BCS_RLWheelSpdVD_B 0;
BA_ "Remark" SG_ 359 BCS_RLWheelSpdVD_B "";
BA_ "EventCommandSignal" SG_ 359 BCS_RLWheelRotatedDirection_B 0;
BA_ "GatewayedSignals" SG_ 359 BCS_RLWheelRotatedDirection_B 0;
BA_ "GenSigInactiveValue" SG_ 359 BCS_RLWheelRotatedDirection_B 0;
BA_ "GenSigInvalidValue" SG_ 359 BCS_RLWheelRotatedDirection_B 0;
BA_ "GenSigSendType" SG_ 359 BCS_RLWheelRotatedDirection_B 1;
BA_ "GenSigStartValue" SG_ 359 BCS_RLWheelRotatedDirection_B 0;
BA_ "GenSigTimeoutValue" SG_ 359 BCS_RLWheelRotatedDirection_B 0;
BA_ "Remark" SG_ 359 BCS_RLWheelRotatedDirection_B "";
BA_ "EventCommandSignal" SG_ 359 BCS_RLWheelRotatedDirectionVD_B 0;
BA_ "GatewayedSignals" SG_ 359 BCS_RLWheelRotatedDirectionVD_B 0;
BA_ "GenSigInactiveValue" SG_ 359 BCS_RLWheelRotatedDirectionVD_B 0;
BA_ "GenSigInvalidValue" SG_ 359 BCS_RLWheelRotatedDirectionVD_B 0;
BA_ "GenSigSendType" SG_ 359 BCS_RLWheelRotatedDirectionVD_B 1;
BA_ "GenSigStartValue" SG_ 359 BCS_RLWheelRotatedDirectionVD_B 0;
BA_ "GenSigTimeoutValue" SG_ 359 BCS_RLWheelRotatedDirectionVD_B 0;
BA_ "Remark" SG_ 359 BCS_RLWheelRotatedDirectionVD_B "";
BA_ "EventCommandSignal" SG_ 359 BCS_RRWheelSpd_B 0;
BA_ "GatewayedSignals" SG_ 359 BCS_RRWheelSpd_B 0;
BA_ "GenSigInactiveValue" SG_ 359 BCS_RRWheelSpd_B 0;
BA_ "GenSigInvalidValue" SG_ 359 BCS_RRWheelSpd_B 0;
BA_ "GenSigSendType" SG_ 359 BCS_RRWheelSpd_B 1;
BA_ "GenSigStartValue" SG_ 359 BCS_RRWheelSpd_B 0;
BA_ "GenSigTimeoutValue" SG_ 359 BCS_RRWheelSpd_B 0;
BA_ "Remark" SG_ 359 BCS_RRWheelSpd_B "";
BA_ "EventCommandSignal" SG_ 359 BCS_RRWheelSpdVD_B 0;
BA_ "GatewayedSignals" SG_ 359 BCS_RRWheelSpdVD_B 0;
BA_ "GenSigInactiveValue" SG_ 359 BCS_RRWheelSpdVD_B 0;
BA_ "GenSigInvalidValue" SG_ 359 BCS_RRWheelSpdVD_B 0;
BA_ "GenSigSendType" SG_ 359 BCS_RRWheelSpdVD_B 1;
BA_ "GenSigStartValue" SG_ 359 BCS_RRWheelSpdVD_B 0;
BA_ "GenSigTimeoutValue" SG_ 359 BCS_RRWheelSpdVD_B 0;
BA_ "Remark" SG_ 359 BCS_RRWheelSpdVD_B "";
BA_ "EventCommandSignal" SG_ 359 BCS_RRWheelRotatedDirection_B 0;
BA_ "GatewayedSignals" SG_ 359 BCS_RRWheelRotatedDirection_B 0;
BA_ "GenSigInactiveValue" SG_ 359 BCS_RRWheelRotatedDirection_B 0;
BA_ "GenSigInvalidValue" SG_ 359 BCS_RRWheelRotatedDirection_B 0;
BA_ "GenSigSendType" SG_ 359 BCS_RRWheelRotatedDirection_B 1;
BA_ "GenSigStartValue" SG_ 359 BCS_RRWheelRotatedDirection_B 0;
BA_ "GenSigTimeoutValue" SG_ 359 BCS_RRWheelRotatedDirection_B 0;
BA_ "Remark" SG_ 359 BCS_RRWheelRotatedDirection_B "";
BA_ "EventCommandSignal" SG_ 359 BCS_RRWheelRotatedDirectionVD_B 0;
BA_ "GatewayedSignals" SG_ 359 BCS_RRWheelRotatedDirectionVD_B 0;
BA_ "GenSigInactiveValue" SG_ 359 BCS_RRWheelRotatedDirectionVD_B 0;
BA_ "GenSigInvalidValue" SG_ 359 BCS_RRWheelRotatedDirectionVD_B 0;
BA_ "GenSigSendType" SG_ 359 BCS_RRWheelRotatedDirectionVD_B 1;
BA_ "GenSigStartValue" SG_ 359 BCS_RRWheelRotatedDirectionVD_B 0;
BA_ "GenSigTimeoutValue" SG_ 359 BCS_RRWheelRotatedDirectionVD_B 0;
BA_ "Remark" SG_ 359 BCS_RRWheelRotatedDirectionVD_B "";
BA_ "EventCommandSignal" SG_ 359 BCS_HHCCtrlSt_B 0;
BA_ "GatewayedSignals" SG_ 359 BCS_HHCCtrlSt_B 0;
BA_ "GenSigInactiveValue" SG_ 359 BCS_HHCCtrlSt_B 0;
BA_ "GenSigInvalidValue" SG_ 359 BCS_HHCCtrlSt_B 0;
BA_ "GenSigSendType" SG_ 359 BCS_HHCCtrlSt_B 1;
BA_ "GenSigStartValue" SG_ 359 BCS_HHCCtrlSt_B 0;
BA_ "GenSigTimeoutValue" SG_ 359 BCS_HHCCtrlSt_B 0;
BA_ "Remark" SG_ 359 BCS_HHCCtrlSt_B "";
BA_ "EventCommandSignal" SG_ 359 BCS_HDCCtrlSt_B 0;
BA_ "GatewayedSignals" SG_ 359 BCS_HDCCtrlSt_B 0;
BA_ "GenSigInactiveValue" SG_ 359 BCS_HDCCtrlSt_B 0;
BA_ "GenSigInvalidValue" SG_ 359 BCS_HDCCtrlSt_B 0;
BA_ "GenSigSendType" SG_ 359 BCS_HDCCtrlSt_B 1;
BA_ "GenSigStartValue" SG_ 359 BCS_HDCCtrlSt_B 0;
BA_ "GenSigTimeoutValue" SG_ 359 BCS_HDCCtrlSt_B 0;
BA_ "Remark" SG_ 359 BCS_HDCCtrlSt_B "";
BA_ "EventCommandSignal" SG_ 359 BCS_HDCErrSt_B 0;
BA_ "GatewayedSignals" SG_ 359 BCS_HDCErrSt_B 0;
BA_ "GenSigInactiveValue" SG_ 359 BCS_HDCErrSt_B 0;
BA_ "GenSigInvalidValue" SG_ 359 BCS_HDCErrSt_B 0;
BA_ "GenSigSendType" SG_ 359 BCS_HDCErrSt_B 1;
BA_ "GenSigStartValue" SG_ 359 BCS_HDCErrSt_B 0;
BA_ "GenSigTimeoutValue" SG_ 359 BCS_HDCErrSt_B 1;
BA_ "Remark" SG_ 359 BCS_HDCErrSt_B "";
BA_ "EventCommandSignal" SG_ 359 BCS_FLWheelSpdEdgesSum_B 0;
BA_ "GatewayedSignals" SG_ 359 BCS_FLWheelSpdEdgesSum_B 0;
BA_ "GenSigInactiveValue" SG_ 359 BCS_FLWheelSpdEdgesSum_B 0;
BA_ "GenSigInvalidValue" SG_ 359 BCS_FLWheelSpdEdgesSum_B 0;
BA_ "GenSigSendType" SG_ 359 BCS_FLWheelSpdEdgesSum_B 1;
BA_ "GenSigStartValue" SG_ 359 BCS_FLWheelSpdEdgesSum_B 0;
BA_ "GenSigTimeoutValue" SG_ 359 BCS_FLWheelSpdEdgesSum_B 0;
BA_ "Remark" SG_ 359 BCS_FLWheelSpdEdgesSum_B "";
BA_ "EventCommandSignal" SG_ 359 BCS_FRWheelSpdEdgesSum_B 0;
BA_ "GatewayedSignals" SG_ 359 BCS_FRWheelSpdEdgesSum_B 0;
BA_ "GenSigInactiveValue" SG_ 359 BCS_FRWheelSpdEdgesSum_B 0;
BA_ "GenSigInvalidValue" SG_ 359 BCS_FRWheelSpdEdgesSum_B 0;
BA_ "GenSigSendType" SG_ 359 BCS_FRWheelSpdEdgesSum_B 1;
BA_ "GenSigStartValue" SG_ 359 BCS_FRWheelSpdEdgesSum_B 0;
BA_ "GenSigTimeoutValue" SG_ 359 BCS_FRWheelSpdEdgesSum_B 0;
BA_ "Remark" SG_ 359 BCS_FRWheelSpdEdgesSum_B "";
BA_ "EventCommandSignal" SG_ 359 BCS_RLWheelSpdEdgesSum_B 0;
BA_ "GatewayedSignals" SG_ 359 BCS_RLWheelSpdEdgesSum_B 0;
BA_ "GenSigInactiveValue" SG_ 359 BCS_RLWheelSpdEdgesSum_B 0;
BA_ "GenSigInvalidValue" SG_ 359 BCS_RLWheelSpdEdgesSum_B 0;
BA_ "GenSigSendType" SG_ 359 BCS_RLWheelSpdEdgesSum_B 1;
BA_ "GenSigStartValue" SG_ 359 BCS_RLWheelSpdEdgesSum_B 0;
BA_ "GenSigTimeoutValue" SG_ 359 BCS_RLWheelSpdEdgesSum_B 0;
BA_ "Remark" SG_ 359 BCS_RLWheelSpdEdgesSum_B "";
BA_ "EventCommandSignal" SG_ 359 BCS_RRWheelSpdEdgesSum_B 0;
BA_ "GatewayedSignals" SG_ 359 BCS_RRWheelSpdEdgesSum_B 0;
BA_ "GenSigInactiveValue" SG_ 359 BCS_RRWheelSpdEdgesSum_B 0;
BA_ "GenSigInvalidValue" SG_ 359 BCS_RRWheelSpdEdgesSum_B 0;
BA_ "GenSigSendType" SG_ 359 BCS_RRWheelSpdEdgesSum_B 1;
BA_ "GenSigStartValue" SG_ 359 BCS_RRWheelSpdEdgesSum_B 0;
BA_ "GenSigTimeoutValue" SG_ 359 BCS_RRWheelSpdEdgesSum_B 0;
BA_ "Remark" SG_ 359 BCS_RRWheelSpdEdgesSum_B "";
BA_ "EventCommandSignal" SG_ 359 BCS_FLWheelSpdEdgesSumVD_B 0;
BA_ "GatewayedSignals" SG_ 359 BCS_FLWheelSpdEdgesSumVD_B 0;
BA_ "GenSigInactiveValue" SG_ 359 BCS_FLWheelSpdEdgesSumVD_B 0;
BA_ "GenSigInvalidValue" SG_ 359 BCS_FLWheelSpdEdgesSumVD_B 0;
BA_ "GenSigSendType" SG_ 359 BCS_FLWheelSpdEdgesSumVD_B 1;
BA_ "GenSigStartValue" SG_ 359 BCS_FLWheelSpdEdgesSumVD_B 0;
BA_ "GenSigTimeoutValue" SG_ 359 BCS_FLWheelSpdEdgesSumVD_B 0;
BA_ "Remark" SG_ 359 BCS_FLWheelSpdEdgesSumVD_B "";
BA_ "EventCommandSignal" SG_ 359 BCS_FRWheelSpdEdgesSumVD_B 0;
BA_ "GatewayedSignals" SG_ 359 BCS_FRWheelSpdEdgesSumVD_B 0;
BA_ "GenSigInactiveValue" SG_ 359 BCS_FRWheelSpdEdgesSumVD_B 0;
BA_ "GenSigInvalidValue" SG_ 359 BCS_FRWheelSpdEdgesSumVD_B 0;
BA_ "GenSigSendType" SG_ 359 BCS_FRWheelSpdEdgesSumVD_B 1;
BA_ "GenSigStartValue" SG_ 359 BCS_FRWheelSpdEdgesSumVD_B 0;
BA_ "GenSigTimeoutValue" SG_ 359 BCS_FRWheelSpdEdgesSumVD_B 0;
BA_ "Remark" SG_ 359 BCS_FRWheelSpdEdgesSumVD_B "";
BA_ "EventCommandSignal" SG_ 359 BCS_RLWheelSpdEdgesSumVD_B 0;
BA_ "GatewayedSignals" SG_ 359 BCS_RLWheelSpdEdgesSumVD_B 0;
BA_ "GenSigInactiveValue" SG_ 359 BCS_RLWheelSpdEdgesSumVD_B 0;
BA_ "GenSigInvalidValue" SG_ 359 BCS_RLWheelSpdEdgesSumVD_B 0;
BA_ "GenSigSendType" SG_ 359 BCS_RLWheelSpdEdgesSumVD_B 1;
BA_ "GenSigStartValue" SG_ 359 BCS_RLWheelSpdEdgesSumVD_B 0;
BA_ "GenSigTimeoutValue" SG_ 359 BCS_RLWheelSpdEdgesSumVD_B 0;
BA_ "Remark" SG_ 359 BCS_RLWheelSpdEdgesSumVD_B "";
BA_ "EventCommandSignal" SG_ 359 BCS_RRWheelSpdEdgesSumVD_B 0;
BA_ "GatewayedSignals" SG_ 359 BCS_RRWheelSpdEdgesSumVD_B 0;
BA_ "GenSigInactiveValue" SG_ 359 BCS_RRWheelSpdEdgesSumVD_B 0;
BA_ "GenSigInvalidValue" SG_ 359 BCS_RRWheelSpdEdgesSumVD_B 0;
BA_ "GenSigSendType" SG_ 359 BCS_RRWheelSpdEdgesSumVD_B 1;
BA_ "GenSigStartValue" SG_ 359 BCS_RRWheelSpdEdgesSumVD_B 0;
BA_ "GenSigTimeoutValue" SG_ 359 BCS_RRWheelSpdEdgesSumVD_B 0;
BA_ "Remark" SG_ 359 BCS_RRWheelSpdEdgesSumVD_B "";
BA_ "EventCommandSignal" SG_ 359 BCS_FLWheelRotatedDirectionAPA_B 0;
BA_ "GatewayedSignals" SG_ 359 BCS_FLWheelRotatedDirectionAPA_B 0;
BA_ "GenSigInactiveValue" SG_ 359 BCS_FLWheelRotatedDirectionAPA_B 0;
BA_ "GenSigInvalidValue" SG_ 359 BCS_FLWheelRotatedDirectionAPA_B 0;
BA_ "GenSigSendType" SG_ 359 BCS_FLWheelRotatedDirectionAPA_B 1;
BA_ "GenSigStartValue" SG_ 359 BCS_FLWheelRotatedDirectionAPA_B 0;
BA_ "GenSigTimeoutValue" SG_ 359 BCS_FLWheelRotatedDirectionAPA_B 0;
BA_ "Remark" SG_ 359 BCS_FLWheelRotatedDirectionAPA_B "";
BA_ "EventCommandSignal" SG_ 359 BCS_FRWheelRotatedDirectionAPA_B 0;
BA_ "GatewayedSignals" SG_ 359 BCS_FRWheelRotatedDirectionAPA_B 0;
BA_ "GenSigInactiveValue" SG_ 359 BCS_FRWheelRotatedDirectionAPA_B 0;
BA_ "GenSigInvalidValue" SG_ 359 BCS_FRWheelRotatedDirectionAPA_B 0;
BA_ "GenSigSendType" SG_ 359 BCS_FRWheelRotatedDirectionAPA_B 1;
BA_ "GenSigStartValue" SG_ 359 BCS_FRWheelRotatedDirectionAPA_B 0;
BA_ "GenSigTimeoutValue" SG_ 359 BCS_FRWheelRotatedDirectionAPA_B 0;
BA_ "Remark" SG_ 359 BCS_FRWheelRotatedDirectionAPA_B "";
BA_ "EventCommandSignal" SG_ 359 BCS_RLWheelRotatedDirectionAPA_B 0;
BA_ "GatewayedSignals" SG_ 359 BCS_RLWheelRotatedDirectionAPA_B 0;
BA_ "GenSigInactiveValue" SG_ 359 BCS_RLWheelRotatedDirectionAPA_B 0;
BA_ "GenSigInvalidValue" SG_ 359 BCS_RLWheelRotatedDirectionAPA_B 0;
BA_ "GenSigSendType" SG_ 359 BCS_RLWheelRotatedDirectionAPA_B 1;
BA_ "GenSigStartValue" SG_ 359 BCS_RLWheelRotatedDirectionAPA_B 0;
BA_ "GenSigTimeoutValue" SG_ 359 BCS_RLWheelRotatedDirectionAPA_B 0;
BA_ "Remark" SG_ 359 BCS_RLWheelRotatedDirectionAPA_B "";
BA_ "EventCommandSignal" SG_ 359 BCS_RRWheelRotatedDirectionAPA_B 0;
BA_ "GatewayedSignals" SG_ 359 BCS_RRWheelRotatedDirectionAPA_B 0;
BA_ "GenSigInactiveValue" SG_ 359 BCS_RRWheelRotatedDirectionAPA_B 0;
BA_ "GenSigInvalidValue" SG_ 359 BCS_RRWheelRotatedDirectionAPA_B 0;
BA_ "GenSigSendType" SG_ 359 BCS_RRWheelRotatedDirectionAPA_B 1;
BA_ "GenSigStartValue" SG_ 359 BCS_RRWheelRotatedDirectionAPA_B 0;
BA_ "GenSigTimeoutValue" SG_ 359 BCS_RRWheelRotatedDirectionAPA_B 0;
BA_ "Remark" SG_ 359 BCS_RRWheelRotatedDirectionAPA_B "";
BA_ "EventCommandSignal" SG_ 359 BCS_ParkingReqToEPB_B 0;
BA_ "GatewayedSignals" SG_ 359 BCS_ParkingReqToEPB_B 0;
BA_ "GenSigInactiveValue" SG_ 359 BCS_ParkingReqToEPB_B 0;
BA_ "GenSigInvalidValue" SG_ 359 BCS_ParkingReqToEPB_B 0;
BA_ "GenSigSendType" SG_ 359 BCS_ParkingReqToEPB_B 1;
BA_ "GenSigStartValue" SG_ 359 BCS_ParkingReqToEPB_B 0;
BA_ "GenSigTimeoutValue" SG_ 359 BCS_ParkingReqToEPB_B 0;
BA_ "Remark" SG_ 359 BCS_ParkingReqToEPB_B "";
BA_ "EventCommandSignal" SG_ 359 BCS_VDCOff_B 0;
BA_ "GatewayedSignals" SG_ 359 BCS_VDCOff_B 0;
BA_ "GenSigInactiveValue" SG_ 359 BCS_VDCOff_B 0;
BA_ "GenSigInvalidValue" SG_ 359 BCS_VDCOff_B 0;
BA_ "GenSigSendType" SG_ 359 BCS_VDCOff_B 1;
BA_ "GenSigStartValue" SG_ 359 BCS_VDCOff_B 0;
BA_ "GenSigTimeoutValue" SG_ 359 BCS_VDCOff_B 0;
BA_ "Remark" SG_ 359 BCS_VDCOff_B "";
BA_ "EventCommandSignal" SG_ 359 BCS_AVHSt_B 0;
BA_ "GatewayedSignals" SG_ 359 BCS_AVHSt_B 0;
BA_ "GenSigInactiveValue" SG_ 359 BCS_AVHSt_B 0;
BA_ "GenSigInvalidValue" SG_ 359 BCS_AVHSt_B 0;
BA_ "GenSigSendType" SG_ 359 BCS_AVHSt_B 1;
BA_ "GenSigStartValue" SG_ 359 BCS_AVHSt_B 0;
BA_ "GenSigTimeoutValue" SG_ 359 BCS_AVHSt_B 0;
BA_ "Remark" SG_ 359 BCS_AVHSt_B "";
BA_ "EventCommandSignal" SG_ 359 BCS_AVHStandby_B 0;
BA_ "GatewayedSignals" SG_ 359 BCS_AVHStandby_B 0;
BA_ "GenSigInactiveValue" SG_ 359 BCS_AVHStandby_B 0;
BA_ "GenSigInvalidValue" SG_ 359 BCS_AVHStandby_B 0;
BA_ "GenSigSendType" SG_ 359 BCS_AVHStandby_B 1;
BA_ "GenSigStartValue" SG_ 359 BCS_AVHStandby_B 0;
BA_ "GenSigTimeoutValue" SG_ 359 BCS_AVHStandby_B 0;
BA_ "Remark" SG_ 359 BCS_AVHStandby_B "";
BA_ "EventCommandSignal" SG_ 359 BCS_AVHAvailable_B 0;
BA_ "GatewayedSignals" SG_ 359 BCS_AVHAvailable_B 0;
BA_ "GenSigInactiveValue" SG_ 359 BCS_AVHAvailable_B 0;
BA_ "GenSigInvalidValue" SG_ 359 BCS_AVHAvailable_B 0;
BA_ "GenSigSendType" SG_ 359 BCS_AVHAvailable_B 1;
BA_ "GenSigStartValue" SG_ 359 BCS_AVHAvailable_B 0;
BA_ "GenSigTimeoutValue" SG_ 359 BCS_AVHAvailable_B 0;
BA_ "Remark" SG_ 359 BCS_AVHAvailable_B "";
BA_ "EventCommandSignal" SG_ 359 BCS_TCSOff_B 0;
BA_ "GatewayedSignals" SG_ 359 BCS_TCSOff_B 0;
BA_ "GenSigInactiveValue" SG_ 359 BCS_TCSOff_B 0;
BA_ "GenSigInvalidValue" SG_ 359 BCS_TCSOff_B 0;
BA_ "GenSigSendType" SG_ 359 BCS_TCSOff_B 1;
BA_ "GenSigStartValue" SG_ 359 BCS_TCSOff_B 0;
BA_ "GenSigTimeoutValue" SG_ 359 BCS_TCSOff_B 0;
BA_ "Remark" SG_ 359 BCS_TCSOff_B "";
BA_ "EventCommandSignal" SG_ 359 BCS_BrakeOverHeat_B 0;
BA_ "GatewayedSignals" SG_ 359 BCS_BrakeOverHeat_B 0;
BA_ "GenSigInactiveValue" SG_ 359 BCS_BrakeOverHeat_B 0;
BA_ "GenSigInvalidValue" SG_ 359 BCS_BrakeOverHeat_B 0;
BA_ "GenSigSendType" SG_ 359 BCS_BrakeOverHeat_B 1;
BA_ "GenSigStartValue" SG_ 359 BCS_BrakeOverHeat_B 0;
BA_ "GenSigTimeoutValue" SG_ 359 BCS_BrakeOverHeat_B 0;
BA_ "Remark" SG_ 359 BCS_BrakeOverHeat_B "";
BA_ "EventCommandSignal" SG_ 359 BCS_ABAactive_B 0;
BA_ "GatewayedSignals" SG_ 359 BCS_ABAactive_B 0;
BA_ "GenSigInactiveValue" SG_ 359 BCS_ABAactive_B 0;
BA_ "GenSigInvalidValue" SG_ 359 BCS_ABAactive_B 0;
BA_ "GenSigSendType" SG_ 359 BCS_ABAactive_B 1;
BA_ "GenSigStartValue" SG_ 359 BCS_ABAactive_B 0;
BA_ "GenSigTimeoutValue" SG_ 359 BCS_ABAactive_B 0;
BA_ "Remark" SG_ 359 BCS_ABAactive_B "";
BA_ "EventCommandSignal" SG_ 359 BCS_ABAavailable_B 0;
BA_ "GatewayedSignals" SG_ 359 BCS_ABAavailable_B 0;
BA_ "GenSigInactiveValue" SG_ 359 BCS_ABAavailable_B 0;
BA_ "GenSigInvalidValue" SG_ 359 BCS_ABAavailable_B 0;
BA_ "GenSigSendType" SG_ 359 BCS_ABAavailable_B 1;
BA_ "GenSigStartValue" SG_ 359 BCS_ABAavailable_B 0;
BA_ "GenSigTimeoutValue" SG_ 359 BCS_ABAavailable_B 0;
BA_ "Remark" SG_ 359 BCS_ABAavailable_B "";
BA_ "EventCommandSignal" SG_ 359 BCS_ABPActive_B 0;
BA_ "GatewayedSignals" SG_ 359 BCS_ABPActive_B 0;
BA_ "GenSigInactiveValue" SG_ 359 BCS_ABPActive_B 0;
BA_ "GenSigInvalidValue" SG_ 359 BCS_ABPActive_B 0;
BA_ "GenSigSendType" SG_ 359 BCS_ABPActive_B 1;
BA_ "GenSigStartValue" SG_ 359 BCS_ABPActive_B 0;
BA_ "GenSigTimeoutValue" SG_ 359 BCS_ABPActive_B 0;
BA_ "Remark" SG_ 359 BCS_ABPActive_B "";
BA_ "EventCommandSignal" SG_ 359 BCS_ABPAvailable_B 0;
BA_ "GatewayedSignals" SG_ 359 BCS_ABPAvailable_B 0;
BA_ "GenSigInactiveValue" SG_ 359 BCS_ABPAvailable_B 0;
BA_ "GenSigInvalidValue" SG_ 359 BCS_ABPAvailable_B 0;
BA_ "GenSigSendType" SG_ 359 BCS_ABPAvailable_B 1;
BA_ "GenSigStartValue" SG_ 359 BCS_ABPAvailable_B 0;
BA_ "GenSigTimeoutValue" SG_ 359 BCS_ABPAvailable_B 0;
BA_ "Remark" SG_ 359 BCS_ABPAvailable_B "";
BA_ "EventCommandSignal" SG_ 359 BCS_AEBActive_B 0;
BA_ "GatewayedSignals" SG_ 359 BCS_AEBActive_B 0;
BA_ "GenSigInactiveValue" SG_ 359 BCS_AEBActive_B 0;
BA_ "GenSigInvalidValue" SG_ 359 BCS_AEBActive_B 0;
BA_ "GenSigSendType" SG_ 359 BCS_AEBActive_B 1;
BA_ "GenSigStartValue" SG_ 359 BCS_AEBActive_B 0;
BA_ "GenSigTimeoutValue" SG_ 359 BCS_AEBActive_B 0;
BA_ "Remark" SG_ 359 BCS_AEBActive_B "";
BA_ "EventCommandSignal" SG_ 359 BCS_AEBAvailable_B 0;
BA_ "GatewayedSignals" SG_ 359 BCS_AEBAvailable_B 0;
BA_ "GenSigInactiveValue" SG_ 359 BCS_AEBAvailable_B 0;
BA_ "GenSigInvalidValue" SG_ 359 BCS_AEBAvailable_B 0;
BA_ "GenSigSendType" SG_ 359 BCS_AEBAvailable_B 1;
BA_ "GenSigStartValue" SG_ 359 BCS_AEBAvailable_B 0;
BA_ "GenSigTimeoutValue" SG_ 359 BCS_AEBAvailable_B 0;
BA_ "Remark" SG_ 359 BCS_AEBAvailable_B "";
BA_ "EventCommandSignal" SG_ 359 BCS_AWBActive_B 0;
BA_ "GatewayedSignals" SG_ 359 BCS_AWBActive_B 0;
BA_ "GenSigInactiveValue" SG_ 359 BCS_AWBActive_B 0;
BA_ "GenSigInvalidValue" SG_ 359 BCS_AWBActive_B 0;
BA_ "GenSigSendType" SG_ 359 BCS_AWBActive_B 1;
BA_ "GenSigStartValue" SG_ 359 BCS_AWBActive_B 0;
BA_ "GenSigTimeoutValue" SG_ 359 BCS_AWBActive_B 0;
BA_ "Remark" SG_ 359 BCS_AWBActive_B "";
BA_ "EventCommandSignal" SG_ 359 BCS_AWBAvailable_B 0;
BA_ "GatewayedSignals" SG_ 359 BCS_AWBAvailable_B 0;
BA_ "GenSigInactiveValue" SG_ 359 BCS_AWBAvailable_B 0;
BA_ "GenSigInvalidValue" SG_ 359 BCS_AWBAvailable_B 0;
BA_ "GenSigSendType" SG_ 359 BCS_AWBAvailable_B 1;
BA_ "GenSigStartValue" SG_ 359 BCS_AWBAvailable_B 0;
BA_ "GenSigTimeoutValue" SG_ 359 BCS_AWBAvailable_B 0;
BA_ "Remark" SG_ 359 BCS_AWBAvailable_B "";
BA_ "EventCommandSignal" SG_ 359 BCS_VehicleStandStillSt_B 0;
BA_ "GatewayedSignals" SG_ 359 BCS_VehicleStandStillSt_B 0;
BA_ "GenSigInactiveValue" SG_ 359 BCS_VehicleStandStillSt_B 0;
BA_ "GenSigInvalidValue" SG_ 359 BCS_VehicleStandStillSt_B 0;
BA_ "GenSigSendType" SG_ 359 BCS_VehicleStandStillSt_B 1;
BA_ "GenSigStartValue" SG_ 359 BCS_VehicleStandStillSt_B 0;
BA_ "GenSigTimeoutValue" SG_ 359 BCS_VehicleStandStillSt_B 0;
BA_ "Remark" SG_ 359 BCS_VehicleStandStillSt_B "";
BA_ "EventCommandSignal" SG_ 359 BCS_AEBBAActive_B 0;
BA_ "GatewayedSignals" SG_ 359 BCS_AEBBAActive_B 0;
BA_ "GenSigInactiveValue" SG_ 359 BCS_AEBBAActive_B 0;
BA_ "GenSigInvalidValue" SG_ 359 BCS_AEBBAActive_B 0;
BA_ "GenSigSendType" SG_ 359 BCS_AEBBAActive_B 1;
BA_ "GenSigStartValue" SG_ 359 BCS_AEBBAActive_B 0;
BA_ "GenSigTimeoutValue" SG_ 359 BCS_AEBBAActive_B 0;
BA_ "Remark" SG_ 359 BCS_AEBBAActive_B "";
BA_ "EventCommandSignal" SG_ 359 IPB_InputRodStroke_B 0;
BA_ "GatewayedSignals" SG_ 359 IPB_InputRodStroke_B 0;
BA_ "GenSigInactiveValue" SG_ 359 IPB_InputRodStroke_B 0;
BA_ "GenSigInvalidValue" SG_ 359 IPB_InputRodStroke_B 0;
BA_ "GenSigSendType" SG_ 359 IPB_InputRodStroke_B 1;
BA_ "GenSigStartValue" SG_ 359 IPB_InputRodStroke_B 100;
BA_ "GenSigTimeoutValue" SG_ 359 IPB_InputRodStroke_B 0;
BA_ "Remark" SG_ 359 IPB_InputRodStroke_B "";
BA_ "EventCommandSignal" SG_ 359 IPB_InputRodStrokeSt_B 0;
BA_ "GatewayedSignals" SG_ 359 IPB_InputRodStrokeSt_B 0;
BA_ "GenSigInactiveValue" SG_ 359 IPB_InputRodStrokeSt_B 0;
BA_ "GenSigInvalidValue" SG_ 359 IPB_InputRodStrokeSt_B 0;
BA_ "GenSigSendType" SG_ 359 IPB_InputRodStrokeSt_B 1;
BA_ "GenSigStartValue" SG_ 359 IPB_InputRodStrokeSt_B 0;
BA_ "GenSigTimeoutValue" SG_ 359 IPB_InputRodStrokeSt_B 0;
BA_ "Remark" SG_ 359 IPB_InputRodStrokeSt_B "";
BA_ "EventCommandSignal" SG_ 359 BCS_RAEBActive_B 0;
BA_ "GatewayedSignals" SG_ 359 BCS_RAEBActive_B 0;
BA_ "GenSigInactiveValue" SG_ 359 BCS_RAEBActive_B 0;
BA_ "GenSigInvalidValue" SG_ 359 BCS_RAEBActive_B 0;
BA_ "GenSigSendType" SG_ 359 BCS_RAEBActive_B 1;
BA_ "GenSigStartValue" SG_ 359 BCS_RAEBActive_B 0;
BA_ "GenSigTimeoutValue" SG_ 359 BCS_RAEBActive_B 0;
BA_ "Remark" SG_ 359 BCS_RAEBActive_B "";
BA_ "EventCommandSignal" SG_ 359 BCS_RAEBAvailable_B 0;
BA_ "GatewayedSignals" SG_ 359 BCS_RAEBAvailable_B 0;
BA_ "GenSigInactiveValue" SG_ 359 BCS_RAEBAvailable_B 0;
BA_ "GenSigInvalidValue" SG_ 359 BCS_RAEBAvailable_B 0;
BA_ "GenSigSendType" SG_ 359 BCS_RAEBAvailable_B 1;
BA_ "GenSigStartValue" SG_ 359 BCS_RAEBAvailable_B 0;
BA_ "GenSigTimeoutValue" SG_ 359 BCS_RAEBAvailable_B 0;
BA_ "Remark" SG_ 359 BCS_RAEBAvailable_B "";
BA_ "EventCommandSignal" SG_ 359 IPB_PlungerPressureSt_B 0;
BA_ "GatewayedSignals" SG_ 359 IPB_PlungerPressureSt_B 0;
BA_ "GenSigInactiveValue" SG_ 359 IPB_PlungerPressureSt_B 0;
BA_ "GenSigInvalidValue" SG_ 359 IPB_PlungerPressureSt_B 0;
BA_ "GenSigSendType" SG_ 359 IPB_PlungerPressureSt_B 1;
BA_ "GenSigStartValue" SG_ 359 IPB_PlungerPressureSt_B 0;
BA_ "GenSigTimeoutValue" SG_ 359 IPB_PlungerPressureSt_B 0;
BA_ "Remark" SG_ 359 IPB_PlungerPressureSt_B "";
BA_ "EventCommandSignal" SG_ 359 IPB_PlungerPressure_B 0;
BA_ "GatewayedSignals" SG_ 359 IPB_PlungerPressure_B 0;
BA_ "GenSigInactiveValue" SG_ 359 IPB_PlungerPressure_B 0;
BA_ "GenSigInvalidValue" SG_ 359 IPB_PlungerPressure_B 0;
BA_ "GenSigSendType" SG_ 359 IPB_PlungerPressure_B 1;
BA_ "GenSigStartValue" SG_ 359 IPB_PlungerPressure_B 17;
BA_ "GenSigTimeoutValue" SG_ 359 IPB_PlungerPressure_B 0;
BA_ "Remark" SG_ 359 IPB_PlungerPressure_B "";
BA_ "EventCommandSignal" SG_ 359 BCS_BrkTqCtrlAvlDrivingRdn_B 0;
BA_ "GatewayedSignals" SG_ 359 BCS_BrkTqCtrlAvlDrivingRdn_B 0;
BA_ "GenSigInactiveValue" SG_ 359 BCS_BrkTqCtrlAvlDrivingRdn_B 0;
BA_ "GenSigInvalidValue" SG_ 359 BCS_BrkTqCtrlAvlDrivingRdn_B 0;
BA_ "GenSigSendType" SG_ 359 BCS_BrkTqCtrlAvlDrivingRdn_B 1;
BA_ "GenSigStartValue" SG_ 359 BCS_BrkTqCtrlAvlDrivingRdn_B 0;
BA_ "GenSigTimeoutValue" SG_ 359 BCS_BrkTqCtrlAvlDrivingRdn_B 0;
BA_ "Remark" SG_ 359 BCS_BrkTqCtrlAvlDrivingRdn_B "";
BA_ "EventCommandSignal" SG_ 359 BCS_BrkTqCtrlActvRdn_B 0;
BA_ "GatewayedSignals" SG_ 359 BCS_BrkTqCtrlActvRdn_B 0;
BA_ "GenSigInactiveValue" SG_ 359 BCS_BrkTqCtrlActvRdn_B 0;
BA_ "GenSigInvalidValue" SG_ 359 BCS_BrkTqCtrlActvRdn_B 0;
BA_ "GenSigSendType" SG_ 359 BCS_BrkTqCtrlActvRdn_B 1;
BA_ "GenSigStartValue" SG_ 359 BCS_BrkTqCtrlActvRdn_B 0;
BA_ "GenSigTimeoutValue" SG_ 359 BCS_BrkTqCtrlActvRdn_B 0;
BA_ "Remark" SG_ 359 BCS_BrkTqCtrlActvRdn_B "";
BA_ "EventCommandSignal" SG_ 359 BCS_L3CommunicationVld_B 0;
BA_ "GatewayedSignals" SG_ 359 BCS_L3CommunicationVld_B 0;
BA_ "GenSigInactiveValue" SG_ 359 BCS_L3CommunicationVld_B 0;
BA_ "GenSigInvalidValue" SG_ 359 BCS_L3CommunicationVld_B 0;
BA_ "GenSigSendType" SG_ 359 BCS_L3CommunicationVld_B 1;
BA_ "GenSigStartValue" SG_ 359 BCS_L3CommunicationVld_B 0;
BA_ "GenSigTimeoutValue" SG_ 359 BCS_L3CommunicationVld_B 0;
BA_ "Remark" SG_ 359 BCS_L3CommunicationVld_B "";
BA_ "EventCommandSignal" SG_ 359 BCS_LFIActiveSt_B 0;
BA_ "GatewayedSignals" SG_ 359 BCS_LFIActiveSt_B 0;
BA_ "GenSigInactiveValue" SG_ 359 BCS_LFIActiveSt_B 0;
BA_ "GenSigInvalidValue" SG_ 359 BCS_LFIActiveSt_B 0;
BA_ "GenSigSendType" SG_ 359 BCS_LFIActiveSt_B 1;
BA_ "GenSigStartValue" SG_ 359 BCS_LFIActiveSt_B 0;
BA_ "GenSigTimeoutValue" SG_ 359 BCS_LFIActiveSt_B 0;
BA_ "Remark" SG_ 359 BCS_LFIActiveSt_B "";

VAL_ 368 DCU_ModeSt 12 "HillholdCtrl" 11 "Service_General( reserved)" 10 "Power off" 9 "Offsetcal" 8 "Failure" 7 "AfterRun" 6 "Discharge" 5 "SpdCtrl" 4 "TrqCtrl" 3 "Ready" 2 "Standby" 1 "Init" 0 "Reserved"  ;
VAL_ 368 DCU_ADC_MCUBlkst 0 "no block" 1 "block" 2 "reserved"  ;
VAL_ 368 DCU_ADC_SpdSvModAvl 0 "not available" 1 "available"  ;
VAL_ 368 DCU_ADC_MCUStandstill 0 "not standstill" 1 "standstill"  ;
VAL_ 368 DCU_ADC_MCUSpdSVModFit 0 "no fault" 1 "excessive output torque fault"  ;
VAL_ 368 DCU_ADC_MCUVehSldSt 0 "not slide" 1 "slide"  ;
VAL_ 369 DCU2_ModeSt_Hyb 12 "HillholdCtrl" 11 "Service_General( reserved)" 10 "Power off" 9 "Offsetcal" 8 "Failure" 7 "AfterRun" 6 "Discharge" 5 "SpdCtrl" 4 "TrqCtrl" 3 "Ready" 2 "Standby" 1 "Init" 0 "Reserved"  ;
VAL_ 369 DCU2_ADC_MCUBlkst 0 "no block" 1 "block" 2 "reserved"  ;
VAL_ 369 DCU2_ADC_SpdSvModAvl 0 "not available" 1 "available"  ;
VAL_ 369 DCU2_ADC_MCUStandstill 0 "not standstill" 1 "standstill"  ;
VAL_ 369 DCU2_ADC_MCUSpdSVModFit 0 "no fault" 1 "excessive output torque fault"  ;
VAL_ 369 DCU2_ADC_MCUVehSldSt 0 "not slide" 1 "slide"  ;
VAL_ 860 VCU_RoadMod 0 "Invalid" 1 "Mud Mode" 2 "Snow Mode" 3 "Sand Mode" 4 "Offroad Mode" 5 "Slippery Mode" 7 "Off"  ;
VAL_ 860 VCU_GearLvl 0 "Invalid" 1 "'D' Drive gear" 2 "'N' Neutral gear" 3 "'R' Reverse gear" 4 "'P' Park gear" 5 "Not used" 6 "Not used" 7 "Not used" 8 "Not used" 9 "Not used" 10 "Not used" 11 "Not used" 12 "Not used" 13 "Not used" 14 "Not used" 15 "Not used"  ;
VAL_ 860 VCU_VehDrvMod 7 "Individual" 6 "I-pedal Mode;" 5 "SPORT Mode;" 4 "Driving Mode/Offroad Mode;" 3 "Comfort Mode;" 2 "ECO Mode;" 1 "ECO+ Mode;" 0 "Invalid;"  ;
VAL_ 860 VCU_VehRdySt 0 "Not ready" 1 "Ready"  ;
VAL_ 860 VCU_ChgActiveSt_toADC 0 "Not charging" 1 "charging"  ;
VAL_ 860 VCU_PlgConnSt 0 "Not connected" 1 "Plug connector connected"  ;
VAL_ 860 VCU_GearLvlDisp 0 "Invalid" 1 "'D' Drive gear" 2 "'N' Neutral gear" 3 "'R' Reverse gear" 4 "'P' Park gear" 5 "Reserved" 6 "Reserved" 7 "Reserved" 8 "Reserved" 9 "Reserved" 10 "Reserved" 11 "Reserved" 12 "Reserved" 13 "Reserved" 14 "Reserved" 15 "Reserved"  ;
VAL_ 860 VCU_SuspModeReq 0 "not request" 1 "comfort mode" 2 "normal mode(reserved)" 3 "sport mode"  ;
VAL_ 860 VCU_SuspModeReqEnable 0 "disable" 1 "enable"  ;
VAL_ 860 VCU_PivotSteeringStAvailable 0 "Not Available" 1 "Available"  ;
VAL_ 860 VCU_PivotSteeringSt 0 "Invalid" 1 "OFF" 2 "Standby" 3 "Active" 4 "Closing" 5 "Activing" 6 "Reserved" 7 "Reserved"  ;
VAL_ 860 VCU_GearPosition 0 "Undefined" 1 "P_Pending" 2 "'P' Park gear" 3 "'N' Neutral gear" 4 "'R' Reverse gear" 5 "'D' Drive gear" 6 "EPB Locking failure,return 'N' gear" 7 "Reserved"  ;
VAL_ 860 VCU_EcoPlusMod 0 "No command" 1 "ON" 2 "OFF" 3 "reserved"  ;
VAL_ 860 ICC_RoadMod 0 "Invalid" 1 "Highway" 2 "Auto Mode" 3 "Snow Mode" 4 "Mud Mode" 5 "Sand Mode" 6 "Ruggged Mode" 7 "Wade Mode" 8 "Expert Mode"  ;
VAL_ 431 VCU_TargetRecpTorqSt 0 "NotIntialized" 1 "Normal" 2 "Faulty" 3 "Reserved"  ;
VAL_ 431 VCU_AccElecECFail 0 "No failure" 1 "Failure"  ;
VAL_ 431 VCU_AccDriverOrvd 0 "No override" 1 "Driver override"  ;
VAL_ 431 VCU_AccTMCFail 0 "Normal mode" 1 "In limp-home mode"  ;
VAL_ 431 VCU_TargetRecpTorqFAVD 1 "Valid;" 0 "Invalid;"  ;
VAL_ 431 VCU_TargetRecpTorqRAVD 1 "Valid;" 0 "Invalid;"  ;
VAL_ 431 VCU_TorqDriverReqFAVD 1 "Valid;" 0 "Invalid;"  ;
VAL_ 431 VCU_TorqDriverReqRAVD 1 "Valid;" 0 "Invalid;"  ;
VAL_ 431 VCU_VehActDrvTorqFAVD 1 "Valid;" 0 "Invalid;"  ;
VAL_ 431 VCU_VehActDrvTorqRAVD 1 "Valid;" 0 "Invalid;"  ;
VAL_ 431 VCU_BcsDecelVD 0 "Invalid" 1 "Valid"  ;
VAL_ 431 VCU_RecpTorqRLVD 1 "Valid;" 0 "Invalid;"  ;
VAL_ 431 VCU_RecpTorqRRVD 1 "Valid;" 0 "Invalid;"  ;
VAL_ 431 VCU_ADSNetErrorFb 0 "No Error" 1 "Main Net E2E Error" 2 "Sub Net E2E Error" 3 "Both Net E2E Error" 4 "Reserved" 5 "Reserved" 6 "Reserved" 7 "Reserved"  ;
VAL_ 431 VCU_NetModeResp 0 "None" 1 "Main/sub Net active" 2 "Main/sub Net active with error" 3 "Reserved"  ;
VAL_ 516 VCU_VehWheelTorqMaxVD 0 "Not valid" 1 "Valid"  ;
VAL_ 516 VCU_RecpTorqSt 0 "NotIntialized" 1 "Normal" 2 "Faulty" 3 "Reserved"  ;
VAL_ 516 VCU_MaxRecpTorqSt 0 "NotIntialized" 1 "Normal" 2 "Faulty" 3 "Reserved"  ;
VAL_ 516 VCU_CrntGearLvl 0 "Invalid" 1 "'D' Drive gear" 2 "'N' Neutral gear" 3 "'R' Reverse gear" 4 "'P' Park gear" 5 "Not used" 6 "Not used" 7 "Not used"  ;
VAL_ 516 VCU_CrntGearLvlVD 1 "Valid;" 0 "Not valid.;"  ;
VAL_ 516 VCU_BrkPedPstVD 0 "Not valid" 1 "Valid"  ;
VAL_ 516 VCU_APAGasPedalIntv 0 "With not intervention" 1 "With intervention"  ;
VAL_ 516 VCU_APAAvailable 0 "Not Available" 1 "Available"  ;
VAL_ 516 VCU_APAGearIntervern 0 "with not intervention" 1 "with intervention"  ;
VAL_ 516 VCU_EMS_AccPedalActPstVD 0 "Not valid" 1 "Valid"  ;
VAL_ 516 VCU_EMS_BrkPedalSt 0 "Not pressed                                                                     1"  ;
VAL_ 516 VCU_EMS_BrkPedalStVD 0 "Not Valid                                                                           1"  ;
VAL_ 516 VCU_ACCMaxRecpDecelVD 1 "Valid;" 0 "Invalid;"  ;
VAL_ 516 VCU_ACCLimitOperatingSt 0 "Not active" 1 "active"  ;
VAL_ 516 VCU_APAResp 0 "without response" 1 "with response"  ;
VAL_ 516 VCU_ADSEcoModReq 1 "Active;" 0 "Not Active;"  ;
VAL_ 516 VCU_AccButtInfo 0 "not press" 1 "press" 0 "not press" 1 "press" 0 "not press" 1 "press" 0 "not press" 1 "press" 0 "not press" 1 "press" 0 "Normal" 1 "Abnormal"  ;
VAL_ 516 VCU_ACCmaxSpdLimit 0 "No Limit" 1 "10 Km/h" 2 "20 Km/h" 3 "30 Km/h" 4 "40 Km/h" 5 "50 Km/h" 6 "60 Km/h" 7 "70 Km/h" 8 "80 Km/h" 9 "90 Km/h" 10 "100 Km/h" 11 "110 Km/h" 12 "120 Km/h" 13 "130 Km/h" 14 "140 Km/h" 15 "Reserved"  ;
VAL_ 516 VCU_APA_Resp 1 "Yes;" 0 "No;"  ;
VAL_ 516 VCU_RecpTorqFAVD 1 "Valid;" 0 "Invalid;"  ;
VAL_ 516 VCU_RecpTorqRAVD 1 "Valid;" 0 "Invalid;"  ;
VAL_ 516 VCU_MaxRecpTorqFAVD 1 "Valid;" 0 "Not valid;"  ;
VAL_ 516 VCU_MaxRecpTorqRAVD 1 "Valid;" 0 "Not valid;"  ;
VAL_ 516 VCU_BcsDecelEnable 0 "Not active" 1 "Active"  ;
VAL_ 516 VCU_CrntGearNoTrans 4 "'P' Park gear;" 3 "'R' Reverse gear;" 2 "'N' Neutral gear;" 1 "'D' Drive gear;" 0 "Invalid;"  ;
VAL_ 516 VCU_EzTSt 0 "Invalid" 1 "Off" 2 "Standby" 3 "Active"  ;
VAL_ 516 VCU_ITASSt 0 "invalid" 1 "Off" 2 "Standby" 3 "Active" 4 "Rampoff Request" 5 "Reserved" 6 "Reserved" 7 "Reserved"  ;
VAL_ 616 UMM_UsageModeSt 0 "Standby" 1 "Comfort" 2 "Reserved" 3 "DRV" 4 "Reserved" 5 "Reserved" 6 "Reserved" 7 "Invalid"  ;
VAL_ 616 OTA_FuncReq_ADCWakeup 0 "Inactive" 1 "Active" 2 "Reserved" 3 "Reserved" 4 "Reserved" 5 "Reserved" 6 "Reserved" 7 "Reserved"  ;
VAL_ 616 UMM_FrontPassengerSeatSt 0 "Undefined" 1 "Off" 2 "On" 3 "Failure"  ;
VAL_ 616 UMM_DriverSeatSt 0 "Undefined" 1 "Off" 2 "On" 3 "Failure"  ;
VAL_ 616 VMM_VehModeSt 0 "Normal Mode" 1 "Manufacture Mode" 2 "Transport Mode" 3 "Showroom Mode" 4 "PostCrash Mode" 5 "Maintenance Mode" 6 "Reserved" 7 "Reserved" 8 "Reserved" 9 "Reserved" 10 "Reserved" 11 "Reserved" 12 "Reserved" 13 "Reserved" 14 "Reserved" 15 "Invalid Value"  ;
VAL_ 616 VMM_LastVehModeSt 0 "Normal Mode" 1 "Manufacture Mode" 2 "Transport Mode" 3 "Showroom Mode" 4 "PostCrash Mode" 5 "Maintenance Mode" 6 "Reserved" 7 "Reserved" 8 "Reserved" 9 "Reserved" 10 "Reserved" 11 "Reserved" 12 "Reserved" 13 "Reserved" 14 "Reserved" 15 "Invalid Value"  ;
VAL_ 616 VMM_OTAModeSt 0 "NonOTA Mode" 1 "OTA Mode" 2 "Invalid Value" 3 "reserved"  ;
VAL_ 616 CSM_RC_PAARequest 0 "No request" 1 "SBM RPA request" 2 "SBM HPA request" 3 "EDK request" 4 "TSP HPA request" 5 "TSP AVP request" 6 "check picture" 7 "check video"  ;
VAL_ 616 CSM_RC_AuthSt 0 "Not Used" 1 "Pass" 2 "Failed"  ;
VAL_ 616 IPDS_EnablePowerSup 0 "Not Active" 1 "Active" 2 "PreOFF" 3 "Reserve"  ;
VAL_ 616 CCU_DstFlag 0 "inactive" 1 "active"  ;
VAL_ 616 ASB_DriverActiveBeltFaultSt 0 "Not fault" 1 "Fault"  ;
VAL_ 432 ICC_FcnInfo 0 "TVC Off" 1 "TVC Action" 0 "TBIP Off" 1 "TBIP Action" 0 "RAS APP Off" 1 "RAS APP Action" 0 "SBW Off" 1 "SBW Action" 0 "TSC Off" 1 "TSC Action" 0 "PDC Off" 1 "PDC Action" 0 "ASTC Off" 1 "ASTC Action" 0 "MSC Off" 1 "MSC Action" 0 "SDC Cor Off" 1 "SDC Cor Aciton" 0 "ECAS Cor Off" 1 "ECAS Cor Action" 0 "WSC Off" 1 "WSC Action" 0 "IOS Off" 1 "IOS Active"  ;
VAL_ 432 ICC_FaultSt 0 "No Fault" 1 "Fault" 0 "No Fault" 1 "Fault" 0 "No Fault" 1 "Fault" 0 "No Fault" 1 "Fault" 0 "No Fault" 1 "Fault" 0 "No Fault" 1 "Fault" 0 "No Fault" 1 "Fault" 0 "No Fault" 1 "Fault" 0 "No Fault" 1 "Fault" 0 "No Fault" 1 "Fault" 0 "No Fault" 1 "Fault"  ;
VAL_ 432 ICC_ActorSt 0 "All Actor Normal" 1 "Actors Abnormal" 0 "VCU Normal" 1 "VCU Abnormal" 0 "EPS Normal" 1 "EPS Abnormal" 0 "RAS Normal" 1 "RAS Abnormal" 0 "IBCS Normal" 1 "IBCS Abnormal" 0 "SDC&ECAS Normal" 1 "SDC&ECAS Abnormal" 0 "SBW Normal" 1 "SBW Abnormal"  ;
VAL_ 432 ICC_RAS_AgCtrlAvl 0 "Not available" 1 "Available" 2 "Reserved" 3 "Reserved"  ;
VAL_ 432 ICC_RAS_CalibratedSt 0 "Not calibrated" 1 "Calibrated"  ;
VAL_ 432 ICC_RAS_ErrFeedback 0 "No interruption；" 1 "ADAS AngleReq Invaild or Timeout" 2 "Reserved" 3 "Vehicle Speed Invalid" 4 "Reserved" 5 "ADC Channel A signal Error" 6 "RAS Error" 7 "Other Abnormal" 8 "ADAS AngleReq Over range" 9 "ADAS AngleSpdReq Over range" 10 "Reserved" 11 "Both ADAS Channel Error" 12 "ADC Channel B signal Error；" 13 "Reserved；" 14 "Reserved；" 15 "Reserved；"  ;
VAL_ 432 ICC_RAS_AngleVD 0 "Not valid" 1 "Valid"  ;
VAL_ 432 ICC_RAS_PstOverlaySt 0 "No active" 1 "Ready" 2 "active" 3 "Failed"  ;
VAL_ 432 ICC_RAS_SteerMod 0 "Initial" 1 "Adaptive Mode" 2 "Normal Mode(智驾)" 3 "Emergency Mode(智驾)" 4 "Crab Mode" 5 "Abnormal Mode" 6 "reserved" 7 "reserved"  ;
VAL_ 432 ICC_RAS_HealthyStForADC 0 "Healthy" 1 "Slightly failure" 2 "Abnormal" 3 "Shut off"  ;
VAL_ 432 ICC_RAS_SteeringAngleSpdVD 0 "Not valid" 1 "Valid"  ;
VAL_ 432 ICC_RAS_WarnLamp 0 "No Fault" 1 "Slight Fault" 2 "Urgency Fault" 3 "Severity Urgency Fault"  ;
VAL_ 1359 CCU_NMCBV 0 "Node has not woken up the    network(passive wakeup);" 1 "Node has woken up the network(active wakeup)" 0 "NM PDU contains no Partial Network request information" 1 "NM PDU contains Partial Network request information"  ;
VAL_ 1359 CCU_NMWakeupOrigin 0 "Reserved" 1 "CAN channel 0" 2 "CAN channel 1" 3 "CAN channel 2" 4 "CAN channel 3" 5 "CAN channel 4" 6 "CAN channel 5" 7 "CAN channel 6" 8 "CAN channel 7" 9 "CAN channel 8" 10 "CAN channel 9" 11 "CAN channel 10" 12 "CAN channel 11" 13 "CAN channel 12" 14 "CAN channel 13" 15 "CAN channel 14" 16 "CAN channel 15" 17 "Reserved" 18 "Reserved" 19 "Reserved" 20 "AcoreRequest" 21 "Reserved" 22 "Reserved" 23 "Reserved" 24 "Reserved" 25 "Reserved" 26 "Reserved" 27 "Reserved" 28 "Reserved" 29 "Reserved" 30 "Reserved" 31 "Reserved" 32 "Reserved" 33 "Reserved" 34 "Reserved" 35 "Reserved" 36 "Reserved" 37 "Reserved" 38 "Reserved" 39 "Reserved" 40 "Reserved" 41 "Reserved" 42 "Reserved" 43 "Reserved" 44 "Reserved" 45 "Reserved" 46 "Reserved" 47 "Reserved" 48 "Reserved" 49 "Reserved" 50 "UsageModeSt" 51 "NMiDPSNMKeepAwakeFlag" 52 "NMEEMKeepAwakeFlag" 53 "NMEEMKeepAwakeFlag_Aux" 54 "NMVCUGlobalKeepAwakeFlag" 55 "NMVCUChargingKeepAwakeFlag（新能源，VCU_hcu）" 56 "DoIPActiveLineStatus" 57 "NMBMSGlobalKeepAwakeFlag" 58 "NMBMSChargingKeepAwakeFlag" 59 "NMBMSThermalRunawayKeepAwakeFlag（新能源，BMS）" 60 "Reserved" 61 "NMBMSThermalRunawayKeepAwakeFlag （动力，VCU_slccu）" 62 "NMVCUChargingKeepAwakeFlag（动力，VCU_slccu）" 63 "NMVCU2GlobalKeepAwakeFlag" 64 "NMVHMKeepAwakeFlag" 65 "Reserved" 66 "CSM_RC_KeepAwake" 67 "NMHVACKeepAwakeFlag（新能源，TMS）" 68 "Reserved" 69 "Reserved" 70 "BDC_NMBDCKeepAwakeFlag" 71 "NMTMSChargingKeepAwakeFlag" 72 "NMTMSGlobalKeepAwakeFlag" 73 "Reserved" 74 "Reserved" 75 "Reserved" 76 "Reserved" 77 "Reserved" 78 "Reserved" 79 "Reserved" 80 "Reserved" 81 "Reserved" 82 "Reserved" 83 "Reserved" 84 "Reserved" 85 "Reserved" 86 "Reserved" 87 "Reserved" 88 "Reserved" 89 "NMWCCDownloadRequest_RT1" 90 "CAN7_DiagMSG_ID ！" 91 "CAN7_DiagMSG_ID" 92 "Reserved" 93 "Reserved" 94 "Reserved" 95 "Reserved" 96 "Reserved" 97 "Reserved" 98 "Reserved" 99 "Reserved" 100 "NMATWSKeepAwakeFlag" 101 "NMExteriorLightKeepAwakeFlag" 102 "NMLockingKeepAwakeFlag" 103 "NMPWLKeepAwakeFlag" 104 "NMSunRoofKeepAwakeFlag" 105 "NMPLGKeepAwakeFlag" 106 "NMPowerOperatedDoorKeepAwakeFlag" 107 "MR_NMMirrorKeepAwakeFlag" 108 "NMSeatControlKeepAwakeFlag" 109 "NMHVACKeepAwakeFlag" 110 "NMHVACRLSLinAwakeFlag" 111 "NMAQCKeepAwakeFlag" 112 "NMTPMSKeepAwakeFlag" 113 "ILC_NMKeepAwakeFlag" 114 "NMESMKeepAwakeFlag" 115 "NMKAEKeepAwakeFlag" 116 "NMVRMPNCCharingKeepAwakeFlag" 140 "NMWCCDownloadReques_RT2"  ;
VAL_ 1359 CCU_PNCInformation0 0 "No request" 1 "Request" 0 "No request" 1 "Request" 0 "No request" 1 "Request" 0 "No request" 1 "Request" 1 "Request" 0 "No request" 1 "Request" 0 "No request" 1 "Request"  ;
VAL_ 1359 CCU_PNCInformation1 0 "No request" 1 "Request" 0 "No request" 1 "Request"  ;
VAL_ 359 BCS_FLWheelSpdVD_B 0 "Not valid" 1 "Valid"  ;
VAL_ 359 BCS_FLWheelRotatedDirection_B 0 "Forward" 1 "Backward"  ;
VAL_ 359 BCS_FLWheelRotatedDirectionVD_B 0 "Not valid" 1 "Valid"  ;
VAL_ 359 BCS_FRWheelSpdVD_B 0 "Not valid" 1 "Valid"  ;
VAL_ 359 BCS_FRWheelRotatedDirection_B 0 "Forward" 1 "Backward"  ;
VAL_ 359 BCS_FRWheelRotatedDirectionVD_B 0 "Not valid" 1 "Valid"  ;
VAL_ 359 BCS_RLWheelSpdVD_B 0 "Not valid" 1 "Valid"  ;
VAL_ 359 BCS_RLWheelRotatedDirection_B 0 "Forward" 1 "Backward"  ;
VAL_ 359 BCS_RLWheelRotatedDirectionVD_B 0 "Not valid" 1 "Valid"  ;
VAL_ 359 BCS_RRWheelSpdVD_B 0 "Not valid" 1 "Valid"  ;
VAL_ 359 BCS_RRWheelRotatedDirection_B 0 "Forward" 1 "Backward"  ;
VAL_ 359 BCS_RRWheelRotatedDirectionVD_B 0 "Not valid" 1 "Valid"  ;
VAL_ 359 BCS_HHCCtrlSt_B 0 "Not active" 1 "Active"  ;
VAL_ 359 BCS_HDCCtrlSt_B 0 "Off" 1 "On active braking" 2 "On not active braking" 3 "Not used"  ;
VAL_ 359 BCS_HDCErrSt_B 0 "No error" 1 "Error"  ;
VAL_ 359 BCS_FLWheelSpdEdgesSumVD_B 0 "Not valid" 1 "Valid"  ;
VAL_ 359 BCS_FRWheelSpdEdgesSumVD_B 0 "Not valid" 1 "Valid"  ;
VAL_ 359 BCS_RLWheelSpdEdgesSumVD_B 0 "Not valid" 1 "Valid"  ;
VAL_ 359 BCS_RRWheelSpdEdgesSumVD_B 0 "Not valid" 1 "Valid"  ;
VAL_ 359 BCS_FLWheelRotatedDirectionAPA_B 0 "Standstill" 1 "Forward" 2 "Backward" 3 "Unknown"  ;
VAL_ 359 BCS_FRWheelRotatedDirectionAPA_B 0 "Standstill" 1 "Forward" 2 "Backward" 3 "Unknown"  ;
VAL_ 359 BCS_RLWheelRotatedDirectionAPA_B 0 "Standstill" 1 "Forward" 2 "Backward" 3 "Unknown"  ;
VAL_ 359 BCS_RRWheelRotatedDirectionAPA_B 0 "Standstill" 1 "Forward" 2 "Backward" 3 "Unknown"  ;
VAL_ 359 BCS_ParkingReqToEPB_B 0 "No request" 1 "Release brake request" 2 "Lock brake request" 3 "Not used"  ;
VAL_ 359 BCS_VDCOff_B 0 "On" 1 "Off"  ;
VAL_ 359 BCS_AVHSt_B 0 "Not active" 1 "Active"  ;
VAL_ 359 BCS_AVHStandby_B 0 "Not standby" 1 "Standby"  ;
VAL_ 359 BCS_AVHAvailable_B 0 "Not available" 1 "Available"  ;
VAL_ 359 BCS_TCSOff_B 0 "On" 1 "Off"  ;
VAL_ 359 BCS_BrakeOverHeat_B 0 "Not high" 1 "Temp too high"  ;
VAL_ 359 BCS_ABAactive_B 0 "Not active" 1 "Active"  ;
VAL_ 359 BCS_ABAavailable_B 0 "Not available" 1 "Available"  ;
VAL_ 359 BCS_ABPActive_B 0 "Not active" 1 "Active"  ;
VAL_ 359 BCS_ABPAvailable_B 0 "Not available" 1 "Available"  ;
VAL_ 359 BCS_AEBActive_B 0 "Not active" 1 "Active"  ;
VAL_ 359 BCS_AEBAvailable_B 0 "Not available" 1 "Available"  ;
VAL_ 359 BCS_AWBActive_B 0 "Not active" 1 "Active"  ;
VAL_ 359 BCS_AWBAvailable_B 0 "Not available" 1 "Available"  ;
VAL_ 359 BCS_VehicleStandStillSt_B 0 "Not standstill" 1 "standstill" 2 "Invalid (short unavailability, max 3s)" 3 "Not used"  ;
VAL_ 359 BCS_AEBBAActive_B 0 "Not active" 1 "Active"  ;
VAL_ 359 IPB_InputRodStrokeSt_B 0 "Valid/Init" 1 "Invalid/Default"  ;
VAL_ 359 BCS_RAEBActive_B 0 "Not active" 1 "Active"  ;
VAL_ 359 BCS_RAEBAvailable_B 0 "Not avaialbe" 1 "Available"  ;
VAL_ 359 IPB_PlungerPressureSt_B 0 "Valid/Init" 1 "Invalid/Default"  ;
VAL_ 359 BCS_BrkTqCtrlAvlDrivingRdn_B 0 "BrakeBackupStrategyAvailability_None" 1 "BrakeBackupStrategyAvailability_Full" 2 "BrakeBackupStrategyAvailability_Fault" 3 "BrakeBackupStrategyAvailability_TestPending" 4 "BrakeBackupStrategyAvailability_NotInitialized" 5 "Reserved" 6 "Reserved" 7 "Reserved"  ;
VAL_ 359 BCS_BrkTqCtrlActvRdn_B 0 "BrakeMain_None" 1 "BrakeMain_APAactive" 2 "BrakeMain_ACCactive" 3 "Reserved"  ;
VAL_ 359 BCS_L3CommunicationVld_B 0 "Invalid" 1 "Valid"  ;
VAL_ 359 BCS_LFIActiveSt_B 0 "Not Active" 1 "Active"  ;
